VERSION ""

NS_ :

BS_:

BU_: TCM_Diesel ECM_Diesel BECMB_EPM TCM ECM Generic_BCM GWM _delete APIM BCM DCDC_VQM PAM TSTR PCM

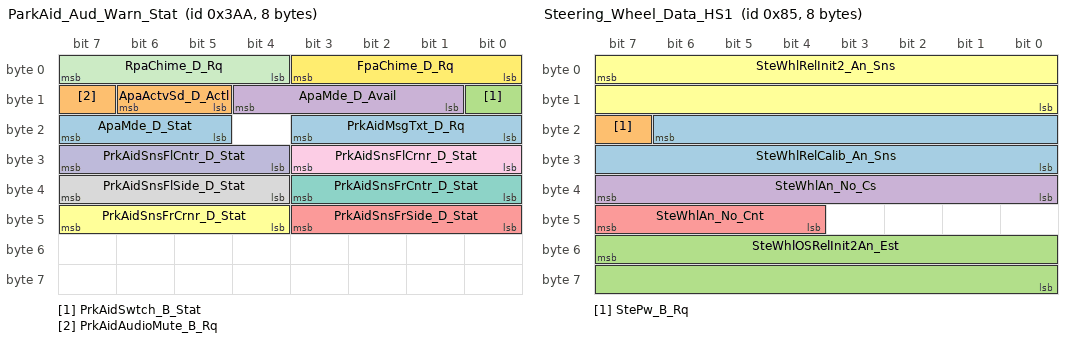
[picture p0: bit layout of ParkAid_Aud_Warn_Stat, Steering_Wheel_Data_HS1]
BO_ 938 ParkAid_Aud_Warn_Stat: 8 PAM
 SG_ ApaMde_D_Stat : 23|3@0+ (1,0) [0|7] "SED"  GWM
 SG_ ApaActvSd_D_Actl : 14|2@0+ (1,0) [0|3] "SED"  GWM
 SG_ PrkAidSwtch_B_Stat : 8|1@0+ (1,0) [0|1] "SED"  GWM
 SG_ ApaMde_D_Avail : 12|4@0+ (1,0) [0|15] "SED"  GWM
 SG_ PrkAidSnsFrSide_D_Stat : 43|4@0+ (1,0) [0|15] "SED"  GWM
 SG_ PrkAidSnsFrCrnr_D_Stat : 47|4@0+ (1,0) [0|15] "SED"  GWM
 SG_ PrkAidSnsFrCntr_D_Stat : 35|4@0+ (1,0) [0|15] "SED"  GWM
 SG_ PrkAidSnsFlSide_D_Stat : 39|4@0+ (1,0) [0|15] "SED"  GWM
 SG_ PrkAidSnsFlCrnr_D_Stat : 27|4@0+ (1,0) [0|15] "SED"  GWM
 SG_ PrkAidSnsFlCntr_D_Stat : 31|4@0+ (1,0) [0|15] "SED"  GWM
 SG_ RpaChime_D_Rq : 7|4@0+ (1,0) [0|15] "SED"  GWM
 SG_ FpaChime_D_Rq : 3|4@0+ (1,0) [0|15] "SED"  GWM
 SG_ PrkAidMsgTxt_D_Rq : 19|4@0+ (1,0) [0|15] "SED"  GWM
 SG_ PrkAidAudioMute_B_Rq : 15|1@0+ (1,0) [0|1] "SED"  GWM

BO_ 963 BCM_Lamp_Stat: 8 BCM
 SG_ WrlssAcsyChrgInhbt_B_Rq : 40|1@0+ (1,0) [0|1] "SED"  GWM
 SG_ PudLampPsngr_D_Rq : 57|2@0+ (1,0) [0|3] "SED"  GWM
 SG_ PudLampDrv_D_Rq : 59|2@0+ (1,0) [0|3] "SED"  GWM
 SG_ DrTgateLck_D_Stat : 61|2@0+ (1,0) [0|3] "SED"  GWM
 SG_ Illuminated_Entry_Stat : 63|2@0+ (1,0) [0|3] "SED"  GWM
 SG_ Dr_Courtesy_Light_Stat : 49|2@0+ (1,0) [0|3] "SED"  GWM
 SG_ Courtesy_Delay_Status : 51|2@0+ (1,0) [0|3] "SED"  GWM
 SG_ ImpactEvntFdbck_D_Stat : 53|2@0+ (1,0) [0|3] "SED"  GWM
 SG_ HeadLampLoOut_B_Stat : 32|1@0+ (1,0) [0|1] "SED"  GWM
 SG_ CrnrLghtRight_Pc_Rq : 47|7@0+ (1,0) [0|100] "percent"  GWM
 SG_ CrnrLghtLeft_Pc_Rq : 39|7@0+ (1,0) [0|100] "percent"  GWM
 SG_ HeadLghtHiFdbck_D_Stat : 55|2@0+ (1,0) [0|3] "SED"  GWM
 SG_ TrnNotInPrkChime_B_Rq : 24|1@0+ (1,0) [0|1] "SED"  GWM
 SG_ PrkLightChime_B_Rq : 25|1@0+ (1,0) [0|1] "SED"  GWM
 SG_ KeyInIgnWarn_B_Cmd : 27|1@0+ (1,0) [0|1] "SED"  GWM
 SG_ HomeSafeLtChime_B_Rq : 28|1@0+ (1,0) [0|1] "SED"  GWM
 SG_ StopLghtOn_B_Stat : 8|1@0+ (1,0) [0|1] "SED"  GWM
 SG_ RvrseLghtOn_B_Stat : 9|1@0+ (1,0) [0|1] "SED"  GWM
 SG_ PrkLght_D_Stat : 13|2@0+ (1,0) [0|3] "SED"  GWM
 SG_ HeadLghtSwtch_D_Stat : 15|2@0+ (1,0) [0|3] "SED"  GWM
 SG_ HeadLampLoFrOn_B_Stat : 2|1@0+ (1,0) [0|1] "SED"  GWM
 SG_ HeadLampLoFlOn_B_Stat : 3|1@0+ (1,0) [0|1] "SED"  GWM
 SG_ HeadLampLoActv_B_Stat : 4|1@0+ (1,0) [0|1] "SED"  ECM_Diesel,ECM,PCM,GWM
 SG_ Headlamp_On_Wrning_Cmd : 29|1@0+ (1,0) [0|1] "SED"  GWM
 SG_ Park_Brake_Chime_Rqst : 26|1@0+ (1,0) [0|1] "SED"  GWM
 SG_ HeadLghtHiOn_B_Stat : 1|1@0+ (1,0) [0|1] "SED"  ECM_Diesel,ECM,PCM,GWM
 SG_ BrkWarnInd_B_Rq : 20|1@0+ (1,0) [0|1] "SED"  GWM
 SG_ Brk_Fluid_Lvl_Low : 31|2@0+ (1,0) [0|3] "SED"  GWM
 SG_ ReducedGuard_D_Stat : 19|2@0+ (1,0) [0|3] "SED"  GWM
 SG_ Perimeter_Alarm_Status : 17|2@0+ (1,0) [0|3] "SED"  GWM
 SG_ Courtesy_BSave_Stat : 7|2@0+ (1,0) [0|3] "SED"  GWM
 SG_ WndwGlbl_D_Cmd : 23|3@0+ (1,0) [0|7] "SED"  GWM
 SG_ PudLamp_D_Rq : 11|2@0+ (1,0) [0|3] "SED"  GWM
 SG_ DayRnngLampOn_B_Stat : 5|1@0+ (1,0) [0|1] "SED"  GWM
 SG_ PerimeterAlarmChimeRq : 0|1@0+ (1,0) [0|1] "SED"  GWM

BO_ 1506 APIM_AutoSar_Network_HS1: 8 APIM
 SG_ APIM_AutoSar_Network_Mgmt : 7|64@0+ (1,0) [0|1.844674407371E+019] "unitless"  TCM_Diesel,BECMB_EPM,TCM,ECM,PCM,BCM,GWM

BO_ 133 Steering_Wheel_Data_HS1: 8 GWM
 SG_ SteWhlRelCalib_An_Sns : 22|15@0+ (0.1,-1600) [-1600|1676.5] "deg" Vector__XXX
 SG_ StePw_B_Rq : 23|1@0+ (1,0) [0|1] "SED"  ECM_Diesel,ECM,PCM
 SG_ SteWhlOSRelInit2An_Est : 55|16@0+ (0.1,-3200) [-3200|3353.3] "deg" Vector__XXX
 SG_ SteWhlAn_No_Cs : 39|8@0+ (1,0) [0|255] "Unitless" Vector__XXX
 SG_ SteWhlAn_No_Cnt : 47|4@0+ (1,0) [0|15] "Counts" Vector__XXX
 SG_ SteWhlRelInit2_An_Sns : 7|16@0+ (0.1,-3200) [-3200|3353.3] "deg"  ECM_Diesel,ECM,PCM

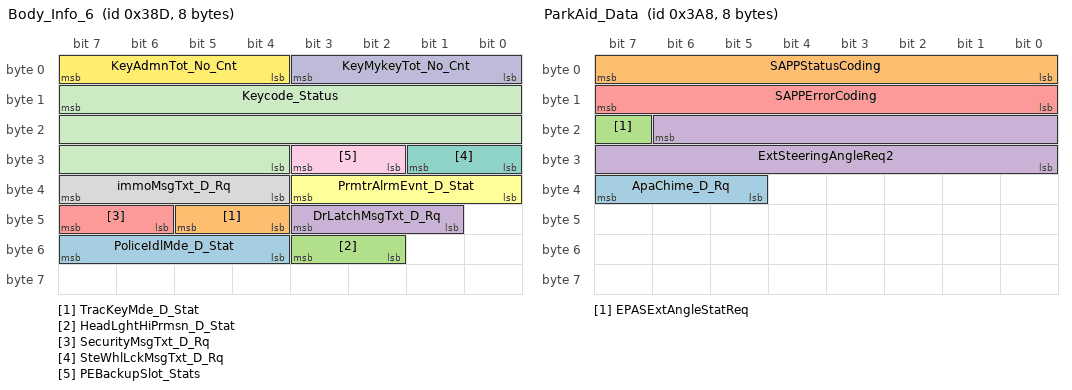
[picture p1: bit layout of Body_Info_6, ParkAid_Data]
BO_ 909 Body_Info_6: 8 BCM
 SG_ PoliceIdlMde_D_Stat : 55|4@0+ (1,0) [0|15] "SED"  GWM
 SG_ TracKeyMde_D_Stat : 45|2@0+ (1,0) [0|3] "SED"  GWM
 SG_ HeadLghtHiPrmsn_D_Stat : 51|2@0+ (1,0) [0|3] "SED"  GWM
 SG_ DrLatchMsgTxt_D_Rq : 43|3@0+ (1,0) [0|7] "SED"  GWM
 SG_ SecurityMsgTxt_D_Rq : 47|2@0+ (1,0) [0|3] "SED"  GWM
 SG_ PrmtrAlrmEvnt_D_Stat : 35|4@0+ (1,0) [0|15] "SED"  GWM
 SG_ SteWhlLckMsgTxt_D_Rq : 25|2@0+ (1,0) [0|3] "SED"  GWM
 SG_ immoMsgTxt_D_Rq : 39|4@0+ (1,0) [0|15] "SED"  GWM
 SG_ PEBackupSlot_Stats : 27|2@0+ (1,0) [0|3] "SED"  GWM
 SG_ KeyMykeyTot_No_Cnt : 3|4@0+ (1,0) [0|15] "Counts"  GWM
 SG_ Keycode_Status : 15|20@0+ (1,0) [0|1048575] "unitless"  GWM
 SG_ KeyAdmnTot_No_Cnt : 7|4@0+ (1,0) [0|15] "Counts"  GWM

BO_ 2024 TesterPhysicalResPCM: 8 PCM
 SG_ TesterPhysicalResPCM : 7|64@0+ (1,0) [0|1.84467E+019] "unitless"  TSTR

BO_ 936 ParkAid_Data: 8 PAM
 SG_ ApaChime_D_Rq : 39|3@0+ (1,0) [0|7] "SED"  GWM
 SG_ SAPPStatusCoding : 7|8@0+ (1,0) [0|255] "unitless"  ECM_Diesel,ECM,BCM,PCM,GWM
 SG_ EPASExtAngleStatReq : 23|1@0+ (1,0) [0|1] "SED"  GWM
 SG_ ExtSteeringAngleReq2 : 22|15@0+ (0.1,-1000) [-1000|2276.5] "Degrees"  GWM
 SG_ SAPPErrorCoding : 15|8@0+ (1,0) [0|255] "SED"  GWM

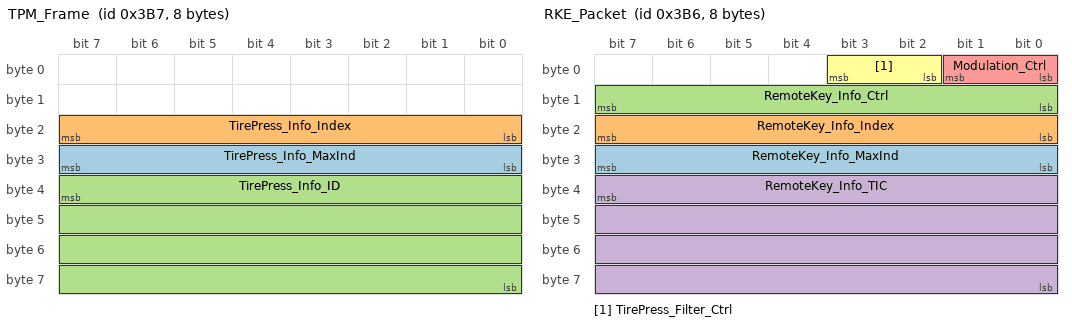
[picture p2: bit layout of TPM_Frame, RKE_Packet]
BO_ 951 TPM_Frame: 8 BCM
 SG_ TirePress_Info_MaxInd : 31|8@0+ (1,0) [0|255] "Unitless"  GWM
 SG_ TirePress_Info_Index : 23|8@0+ (1,0) [0|255] "Unitless"  GWM
 SG_ TirePress_Info_ID : 39|32@0+ (1,0) [0|4294967295] "Unitless"  GWM

BO_ 950 RKE_Packet: 8 BCM
 SG_ RemoteKey_Info_MaxInd : 31|8@0+ (1,0) [0|255] "Unitless"  GWM
 SG_ RemoteKey_Info_Index : 23|8@0+ (1,0) [0|255] "Unitless"  GWM
 SG_ RemoteKey_Info_Ctrl : 15|8@0+ (1,0) [0|255] "Unitless"  GWM
 SG_ RemoteKey_Info_TIC : 39|32@0+ (1,0) [0|4294967295] "Unitless"  GWM
 SG_ Modulation_Ctrl : 1|2@0+ (1,0) [0|3] "SED"  GWM
 SG_ TirePress_Filter_Ctrl : 3|2@0+ (1,0) [0|3] "SED"  GWM

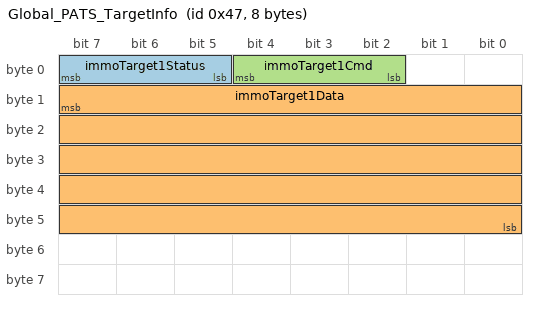
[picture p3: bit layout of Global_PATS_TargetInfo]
BO_ 71 Global_PATS_TargetInfo: 8 PCM
 SG_ immoTarget1Status : 7|3@0+ (1,0) [0|7] "SED"  TCM_Diesel,TCM,GWM,BCM
 SG_ immoTarget1Data : 15|40@0+ (1,0) [0|1099511627775] "Encrypted"  GWM,BCM
 SG_ immoTarget1Cmd : 4|3@0+ (1,0) [0|7] "SED"  GWM,BCM

BO_TX_BU_ 2024 : ECM_Diesel,ECM,PCM;
BO_TX_BU_ 71 : ECM_Diesel,ECM,PCM;
CM_ SG_ 133 SteWhlRelCalib_An_Sns "Signal is not transmitted on vehicles where PSCM is transmitting the message that contains this signal.
Signal data set to 0x0 for ABS only vehicle option content";
CM_ SG_ 133 SteWhlAn_No_Cs "Signal data set to 0x0 for ABS only vehicle option content";
CM_ SG_ 133 SteWhlAn_No_Cnt "Signal data set to 0x0 for ABS only vehicle option content";
CM_ BO_ 71 "Provide target function info. to control function of PATS";
BA_DEF_ SG_  "U_D568C_MY19_Gas_Tx" ENUM  "No","Yes";
BA_DEF_ SG_  "U_CD4_MY19_Diesel_Tx" ENUM  "No","Yes";
BA_DEF_ SG_  "U_CD4_MY19_Gas_Tx" ENUM  "No","Yes";
BA_DEF_ SG_  "U_CD4_MY19_Hev_Tx" ENUM  "No","Yes";
BA_DEF_ SG_  "U_CD4_MY19_Phev_Tx" ENUM  "No","Yes";
BA_DEF_ SG_  "U_V36X_MY19_Tx" ENUM  "No","Yes";
BA_DEF_ SG_  "U_V36X_MY18_5_Gas_Tx" ENUM  "No","Yes";
BA_DEF_ SG_  "U_V36X_MY18_5_Hev_Tx" ENUM  "No","Yes";
BA_DEF_ SG_  "U_V36X_MY19_5_Diesel_Tx" ENUM  "No","Yes";
BA_DEF_ SG_  "U_V363E_N_MY19_5_20_Gas_Tx" ENUM  "No","Yes";
BA_DEF_ SG_  "U_V363E_N_MY19_5_20_Diesel_Tx" ENUM  "No","Yes";
BA_DEF_ SG_  "U_S550_MY18_Gas_Rx" ENUM  "No","Yes";
BA_DEF_ SG_  "U_V408_MY18_Gas_Rx" ENUM  "No","Yes";
BA_DEF_ SG_  "U_V408_MY18_Diesel_Rx" ENUM  "No","Yes";
BA_DEF_ SG_  "U_U502_MY17_Gas_Tx" ENUM  "No","Yes";
BA_DEF_ SG_  "U_CD4_MY18_Diesel_Tx" ENUM  "No","Yes";
BA_DEF_ SG_  "U_CD4_MY18_Gas_Tx" ENUM  "No","Yes";
BA_DEF_ SG_  "U_CD4_MY18_Hev_Tx" ENUM  "No","Yes";
BA_DEF_ SG_  "U_CD4_MY18_Phev_Tx" ENUM  "No","Yes";
BA_DEF_ SG_  "U_S550_MY18_Gas_Tx" ENUM  "No","Yes";
BA_DEF_ SG_  "U_V408_MY18_Gas_Tx" ENUM  "No","Yes";
BA_DEF_ SG_  "U_V408_MY18_Diesel_Tx" ENUM  "No","Yes";
BA_DEF_ SG_  "U_V36X_MY18_5_Diesel_Tx" ENUM  "No","Yes";
BA_DEF_ SG_  "U_P552_MY18_5_Gas_Tx" ENUM  "No","Yes";
BA_DEF_ SG_  "U_P552_MY18_5_Diesel_Tx" ENUM  "No","Yes";
BA_DEF_ SG_  "U_U55x_MY18_Gas_Rx" ENUM  "No","Yes";
BA_DEF_ SG_  "U_P552_MY18_Gas_Tx" ENUM  "No","Yes";
BA_DEF_ SG_  "U_U55x_MY18_Gas_Tx" ENUM  "No","Yes";
BA_DEF_ BO_  "FrameGatewayNetwork" STRING ;
BA_DEF_ SG_  "U_C489_MY17_Gas_Rx" ENUM  "No","Yes";
BA_DEF_ SG_  "U_CD43_MY17_Gas_Rx" ENUM  "No","Yes";
BA_DEF_ SG_  "U_P552_MY17_Gas_Rx" ENUM  "No","Yes";
BA_DEF_ SG_  "U_B515_MCA_MY17_Diesel_Rx" ENUM  "No","Yes";
BA_DEF_ SG_  "U_B515_MCA_MY17_Gas_Rx" ENUM  "No","Yes";
BA_DEF_ SG_  "U_C489_MY17_Gas_Tx" ENUM  "No","Yes";
BA_DEF_ SG_  "U_CD43_MY17_Gas_Tx" ENUM  "No","Yes";
BA_DEF_ SG_  "U_CD4_MY17_Diesel_Rx" ENUM  "No","Yes";
BA_DEF_ SG_  "U_CD4_MY17_Gas_Rx" ENUM  "No","Yes";
BA_DEF_ SG_  "U_CD4_MY17_Hev_Rx" ENUM  "No","Yes";
BA_DEF_ SG_  "U_CD4_MY17_Phev_Rx" ENUM  "No","Yes";
BA_DEF_ SG_  "U_CD42_MY16_Diesel_Rx" ENUM  "No","Yes";
BA_DEF_ SG_  "U_CD42_MY16_Gas_Rx" ENUM  "No","Yes";
BA_DEF_ SG_  "U_B562LC_MY15_Diesel_Tx" ENUM  "No","Yes";
BA_DEF_ SG_  "U_CD4_MY17_Diesel_Tx" ENUM  "No","Yes";
BA_DEF_ SG_  "U_CD4_MY17_Gas_Tx" ENUM  "No","Yes";
BA_DEF_ SG_  "U_CD4_MY17_Hev_Tx" ENUM  "No","Yes";
BA_DEF_ SG_  "U_CD4_MY17_Phev_Tx" ENUM  "No","Yes";
BA_DEF_ SG_  "U_CD42_MY16_Diesel_Tx" ENUM  "No","Yes";
BA_DEF_ SG_  "U_CD42_MY16_Gas_Tx" ENUM  "No","Yes";
BA_DEF_ SG_  "U_CD42_MY15_Gas_Rx" ENUM  "No","Yes";
BA_DEF_ SG_  "U_U502_MY16_Gas_Rx" ENUM  "No","Yes";
BA_DEF_ SG_  "U_P558_MY17_Gas_Rx" ENUM  "No","Yes";
BA_DEF_ SG_  "U_P558_MY17_Diesel_Rx" ENUM  "No","Yes";
BA_DEF_ SG_  "U_V36X_MY16_5_Diesel_Rx" ENUM  "No","Yes";
BA_DEF_ SG_  "U_CD42_MY15_Diesel_Tx" ENUM  "No","Yes";
BA_DEF_ SG_  "U_CD42_MY15_Gas_Tx" ENUM  "No","Yes";
BA_DEF_ SG_  "U_U502_MY16_Gas_Tx" ENUM  "No","Yes";
BA_DEF_ SG_  "U_CD4_MY15_Diesel_Tx" ENUM  "No","Yes";
BA_DEF_ SG_  "U_CD4_MY15_Gas_Tx" ENUM  "No","Yes";
BA_DEF_ SG_  "U_CD4_MY15_Hev_Tx" ENUM  "No","Yes";
BA_DEF_ SG_  "U_CD4_MY15_Phev_Tx" ENUM  "No","Yes";
BA_DEF_ SG_  "U_P558_MY17_Gas_Tx" ENUM  "No","Yes";
BA_DEF_ SG_  "U_P558_MY17_Diesel_Tx" ENUM  "No","Yes";
BA_DEF_ SG_  "U_V36X_MY16_5_Diesel_Tx" ENUM  "No","Yes";
BA_DEF_ BO_  "FrameGatewayHS2" HEX 0 1407;
BA_DEF_ BO_  "NetworkInitialization" ENUM  "No","Yes";
BA_DEF_ BO_  "FrameGatewayId" HEX 0 1407;
BA_DEF_ BO_  "GenMsgStartDelayTime" INT 0 10000;
BA_DEF_ BO_  "GenMsgDelayTime" INT 0 1000;
BA_DEF_ BO_  "GenMsgCycleTime" INT 0 100000;
BA_DEF_ BO_  "GenMsgSendType" ENUM  "FixedPeriodic","Event","EnabledPeriodic","NotUsed","NotUsed","EventPeriodic","NotUsed","NotUsed","NoMsgSendType";
BA_DEF_ SG_  "U_CD4_MY14_Phev_Tx" ENUM  "No","Yes";
BA_DEF_ SG_  "U_CD4_MY14_Hev_Tx" ENUM  "No","Yes";
BA_DEF_ SG_  "U_CD4_MY14_Gas_Tx" ENUM  "No","Yes";
BA_DEF_ SG_  "U_CD4_MY14_Diesel_Tx" ENUM  "No","Yes";
BA_DEF_ SG_  "U_CD43_MY16_Gas_Tx" ENUM  "No","Yes";
BA_DEF_ SG_  "U_UP375_MY15_Diesel_Tx" ENUM  "No","Yes";
BA_DEF_ SG_  "U_UP375_MY15_Gas_Tx" ENUM  "No","Yes";
BA_DEF_ SG_  "U_U502_MY15_Gas_Tx" ENUM  "No","Yes";
BA_DEF_ SG_  "U_B562LC_MY14_Diesel_Tx" ENUM  "No","Yes";
BA_DEF_ SG_  "U_C489_MY14_Gas_Tx" ENUM  "No","Yes";
BA_DEF_ SG_  "U_S550_MY15_Gas_Tx" ENUM  "No","Yes";
BA_DEF_ SG_  "U_P552_MY15_Gas_Tx" ENUM  "No","Yes";
BA_DEF_ SG_  "U_CD42_MY14_Gas_Tx" ENUM  "No","Yes";
BA_DEF_ SG_  "U_CD42_MY14_Diesel_Tx" ENUM  "No","Yes";
BA_DEF_ SG_  "U_CD4_MY13_Phev_Tx" ENUM  "No","Yes";
BA_DEF_ SG_  "U_CD4_MY13_Hev_Tx" ENUM  "No","Yes";
BA_DEF_ SG_  "U_CD4_MY13_Gas_Tx" ENUM  "No","Yes";
BA_DEF_ SG_  "U_CD4_MY13_Diesel_Tx" ENUM  "No","Yes";
BA_DEF_ SG_  "U_CD4_MY14_Phev_Rx" ENUM  "No","Yes";
BA_DEF_ SG_  "U_CD4_MY14_Hev_Rx" ENUM  "No","Yes";
BA_DEF_ SG_  "U_CD4_MY14_Gas_Rx" ENUM  "No","Yes";
BA_DEF_ SG_  "U_CD4_MY14_Diesel_Rx" ENUM  "No","Yes";
BA_DEF_ SG_  "U_CD43_MY16_Gas_Rx" ENUM  "No","Yes";
BA_DEF_ SG_  "U_UP375_MY15_Diesel_Rx" ENUM  "No","Yes";
BA_DEF_ SG_  "U_UP375_MY15_Gas_Rx" ENUM  "No","Yes";
BA_DEF_ SG_  "U_B479_MY15_Gas_Rx" ENUM  "No","Yes";
BA_DEF_ SG_  "U_U502_MY15_Gas_Rx" ENUM  "No","Yes";
BA_DEF_ SG_  "U_C489_MY14_Gas_Rx" ENUM  "No","Yes";
BA_DEF_ SG_  "U_S550_MY15_Gas_Rx" ENUM  "No","Yes";
BA_DEF_ SG_  "U_P552_MY15_Gas_Rx" ENUM  "No","Yes";
BA_DEF_ SG_  "U_CD42_MY14_Gas_Rx" ENUM  "No","Yes";
BA_DEF_ SG_  "U_CD42_MY14_Diesel_Rx" ENUM  "No","Yes";
BA_DEF_ SG_  "U_CD4_MY13_Phev_Rx" ENUM  "No","Yes";
BA_DEF_ SG_  "U_CD4_MY13_Hev_Rx" ENUM  "No","Yes";
BA_DEF_ SG_  "U_CD4_MY13_Gas_Rx" ENUM  "No","Yes";
BA_DEF_ SG_  "U_CD4_MY13_Diesel_Rx" ENUM  "No","Yes";
BA_DEF_ SG_  "ContentDependant" ENUM  "No","Yes";
BA_DEF_ SG_  "GenSigStartValue" INT 0 1000000000;
BA_DEF_ SG_  "CrossOver_LIN" ENUM  "No","Yes";
BA_DEF_ SG_  "CrossOver_InfoCAN" ENUM  "No","Yes";
BA_DEF_ SG_  "WakeupSignal" ENUM  "No","Yes";
BA_DEF_ SG_  "GenSigMissingSourceValue" INT 0 1000000000;
BA_DEF_ SG_  "GenSigSendType" ENUM  "Cyclic","OnWrite","vector_leerstring","OnChange","vector_leerstring","IfActive","vector_leerstring","NoSigSendType";
BA_DEF_ BO_  "NmAsrMessage" ENUM  "No","Yes";
BA_DEF_ BO_  "DiagResponse" ENUM  "No","Yes";
BA_DEF_ BO_  "GenMsgILSupport" ENUM  "No","Yes";
BA_DEF_DEF_  "U_D568C_MY19_Gas_Tx" "No";
BA_DEF_DEF_  "U_CD4_MY19_Diesel_Tx" "No";
BA_DEF_DEF_  "U_CD4_MY19_Gas_Tx" "No";
BA_DEF_DEF_  "U_CD4_MY19_Hev_Tx" "No";
BA_DEF_DEF_  "U_CD4_MY19_Phev_Tx" "No";
BA_DEF_DEF_  "U_V36X_MY19_Tx" "No";
BA_DEF_DEF_  "U_V36X_MY18_5_Gas_Tx" "No";
BA_DEF_DEF_  "U_V36X_MY18_5_Hev_Tx" "No";
BA_DEF_DEF_  "U_V36X_MY19_5_Diesel_Tx" "No";
BA_DEF_DEF_  "U_V363E_N_MY19_5_20_Gas_Tx" "No";
BA_DEF_DEF_  "U_V363E_N_MY19_5_20_Diesel_Tx" "No";
BA_DEF_DEF_  "U_S550_MY18_Gas_Rx" "No";
BA_DEF_DEF_  "U_V408_MY18_Gas_Rx" "No";
BA_DEF_DEF_  "U_V408_MY18_Diesel_Rx" "No";
BA_DEF_DEF_  "U_U502_MY17_Gas_Tx" "No";
BA_DEF_DEF_  "U_CD4_MY18_Diesel_Tx" "No";
BA_DEF_DEF_  "U_CD4_MY18_Gas_Tx" "No";
BA_DEF_DEF_  "U_CD4_MY18_Hev_Tx" "No";
BA_DEF_DEF_  "U_CD4_MY18_Phev_Tx" "No";
BA_DEF_DEF_  "U_S550_MY18_Gas_Tx" "No";
BA_DEF_DEF_  "U_V408_MY18_Gas_Tx" "No";
BA_DEF_DEF_  "U_V408_MY18_Diesel_Tx" "No";
BA_DEF_DEF_  "U_V36X_MY18_5_Diesel_Tx" "No";
BA_DEF_DEF_  "U_P552_MY18_5_Gas_Tx" "No";
BA_DEF_DEF_  "U_P552_MY18_5_Diesel_Tx" "No";
BA_DEF_DEF_  "U_U55x_MY18_Gas_Rx" "No";
BA_DEF_DEF_  "U_P552_MY18_Gas_Tx" "No";
BA_DEF_DEF_  "U_U55x_MY18_Gas_Tx" "No";
BA_DEF_DEF_  "FrameGatewayNetwork" "NONE";
BA_DEF_DEF_  "U_C489_MY17_Gas_Rx" "No";
BA_DEF_DEF_  "U_CD43_MY17_Gas_Rx" "No";
BA_DEF_DEF_  "U_P552_MY17_Gas_Rx" "No";
BA_DEF_DEF_  "U_B515_MCA_MY17_Diesel_Rx" "No";
BA_DEF_DEF_  "U_B515_MCA_MY17_Gas_Rx" "No";
BA_DEF_DEF_  "U_C489_MY17_Gas_Tx" "No";
BA_DEF_DEF_  "U_CD43_MY17_Gas_Tx" "No";
BA_DEF_DEF_  "U_CD4_MY17_Diesel_Rx" "No";
BA_DEF_DEF_  "U_CD4_MY17_Gas_Rx" "No";
BA_DEF_DEF_  "U_CD4_MY17_Hev_Rx" "No";
BA_DEF_DEF_  "U_CD4_MY17_Phev_Rx" "No";
BA_DEF_DEF_  "U_CD42_MY16_Diesel_Rx" "No";
BA_DEF_DEF_  "U_CD42_MY16_Gas_Rx" "No";
BA_DEF_DEF_  "U_B562LC_MY15_Diesel_Tx" "No";
BA_DEF_DEF_  "U_CD4_MY17_Diesel_Tx" "No";
BA_DEF_DEF_  "U_CD4_MY17_Gas_Tx" "No";
BA_DEF_DEF_  "U_CD4_MY17_Hev_Tx" "No";
BA_DEF_DEF_  "U_CD4_MY17_Phev_Tx" "No";
BA_DEF_DEF_  "U_CD42_MY16_Diesel_Tx" "No";
BA_DEF_DEF_  "U_CD42_MY16_Gas_Tx" "No";
BA_DEF_DEF_  "U_CD42_MY15_Gas_Rx" "No";
BA_DEF_DEF_  "U_U502_MY16_Gas_Rx" "No";
BA_DEF_DEF_  "U_P558_MY17_Gas_Rx" "No";
BA_DEF_DEF_  "U_P558_MY17_Diesel_Rx" "No";
BA_DEF_DEF_  "U_V36X_MY16_5_Diesel_Rx" "No";
BA_DEF_DEF_  "U_CD42_MY15_Diesel_Tx" "No";
BA_DEF_DEF_  "U_CD42_MY15_Gas_Tx" "No";
BA_DEF_DEF_  "U_U502_MY16_Gas_Tx" "No";
BA_DEF_DEF_  "U_CD4_MY15_Diesel_Tx" "No";
BA_DEF_DEF_  "U_CD4_MY15_Gas_Tx" "No";
BA_DEF_DEF_  "U_CD4_MY15_Hev_Tx" "No";
BA_DEF_DEF_  "U_CD4_MY15_Phev_Tx" "No";
BA_DEF_DEF_  "U_P558_MY17_Gas_Tx" "No";
BA_DEF_DEF_  "U_P558_MY17_Diesel_Tx" "No";
BA_DEF_DEF_  "U_V36X_MY16_5_Diesel_Tx" "No";
BA_DEF_DEF_  "FrameGatewayHS2" 0;
BA_DEF_DEF_  "NetworkInitialization" "No";
BA_DEF_DEF_  "FrameGatewayId" 0;
BA_DEF_DEF_  "GenMsgStartDelayTime" 0;
BA_DEF_DEF_  "GenMsgDelayTime" 20;
BA_DEF_DEF_  "GenMsgCycleTime" 0;
BA_DEF_DEF_  "GenMsgSendType" "NoMsgSendType";
BA_DEF_DEF_  "U_CD4_MY14_Phev_Tx" "No";
BA_DEF_DEF_  "U_CD4_MY14_Hev_Tx" "No";
BA_DEF_DEF_  "U_CD4_MY14_Gas_Tx" "No";
BA_DEF_DEF_  "U_CD4_MY14_Diesel_Tx" "No";
BA_DEF_DEF_  "U_CD43_MY16_Gas_Tx" "No";
BA_DEF_DEF_  "U_UP375_MY15_Diesel_Tx" "No";
BA_DEF_DEF_  "U_UP375_MY15_Gas_Tx" "No";
BA_DEF_DEF_  "U_U502_MY15_Gas_Tx" "No";
BA_DEF_DEF_  "U_B562LC_MY14_Diesel_Tx" "No";
BA_DEF_DEF_  "U_C489_MY14_Gas_Tx" "No";
BA_DEF_DEF_  "U_S550_MY15_Gas_Tx" "No";
BA_DEF_DEF_  "U_P552_MY15_Gas_Tx" "No";
BA_DEF_DEF_  "U_CD42_MY14_Gas_Tx" "No";
BA_DEF_DEF_  "U_CD42_MY14_Diesel_Tx" "No";
BA_DEF_DEF_  "U_CD4_MY13_Phev_Tx" "No";
BA_DEF_DEF_  "U_CD4_MY13_Hev_Tx" "No";
BA_DEF_DEF_  "U_CD4_MY13_Gas_Tx" "No";
BA_DEF_DEF_  "U_CD4_MY13_Diesel_Tx" "No";
BA_DEF_DEF_  "U_CD4_MY14_Phev_Rx" "No";
BA_DEF_DEF_  "U_CD4_MY14_Hev_Rx" "No";
BA_DEF_DEF_  "U_CD4_MY14_Gas_Rx" "No";
BA_DEF_DEF_  "U_CD4_MY14_Diesel_Rx" "No";
BA_DEF_DEF_  "U_CD43_MY16_Gas_Rx" "No";
BA_DEF_DEF_  "U_UP375_MY15_Diesel_Rx" "No";
BA_DEF_DEF_  "U_UP375_MY15_Gas_Rx" "No";
BA_DEF_DEF_  "U_B479_MY15_Gas_Rx" "No";
BA_DEF_DEF_  "U_U502_MY15_Gas_Rx" "No";
BA_DEF_DEF_  "U_C489_MY14_Gas_Rx" "No";
BA_DEF_DEF_  "U_S550_MY15_Gas_Rx" "No";
BA_DEF_DEF_  "U_P552_MY15_Gas_Rx" "No";
BA_DEF_DEF_  "U_CD42_MY14_Gas_Rx" "No";
BA_DEF_DEF_  "U_CD42_MY14_Diesel_Rx" "No";
BA_DEF_DEF_  "U_CD4_MY13_Phev_Rx" "No";
BA_DEF_DEF_  "U_CD4_MY13_Hev_Rx" "No";
BA_DEF_DEF_  "U_CD4_MY13_Gas_Rx" "No";
BA_DEF_DEF_  "U_CD4_MY13_Diesel_Rx" "No";
BA_DEF_DEF_  "ContentDependant" "No";
BA_DEF_DEF_  "GenSigStartValue" 0;
BA_DEF_DEF_  "CrossOver_LIN" "No";
BA_DEF_DEF_  "CrossOver_InfoCAN" "No";
BA_DEF_DEF_  "WakeupSignal" "No";
BA_DEF_DEF_  "GenSigMissingSourceValue" 0;
BA_DEF_DEF_  "GenSigSendType" "NoSigSendType";
BA_DEF_DEF_  "NmAsrMessage" "No";
BA_DEF_DEF_  "DiagResponse" "No";
BA_DEF_DEF_  "GenMsgILSupport" "Yes";
BA_ "GenMsgSendType" BO_ 938 5;
BA_ "GenMsgCycleTime" BO_ 938 200;
BA_ "GenMsgSendType" BO_ 963 5;
BA_ "GenMsgCycleTime" BO_ 963 1000;
BA_ "GenMsgStartDelayTime" BO_ 963 100;
BA_ "NetworkInitialization" BO_ 963 1;
BA_ "GenMsgILSupport" BO_ 1506 0;
BA_ "NmAsrMessage" BO_ 1506 1;
BA_ "GenMsgSendType" BO_ 1506 1;
BA_ "NetworkInitialization" BO_ 133 1;
BA_ "FrameGatewayNetwork" BO_ 133 "HS2_CAN";
BA_ "GenMsgDelayTime" BO_ 133 5;
BA_ "FrameGatewayId" BO_ 133 133;
BA_ "FrameGatewayHS2" BO_ 133 133;
BA_ "NetworkInitialization" BO_ 909 1;
BA_ "GenMsgSendType" BO_ 909 5;
BA_ "GenMsgCycleTime" BO_ 909 1000;
BA_ "GenMsgILSupport" BO_ 2024 0;
BA_ "DiagResponse" BO_ 2024 1;
BA_ "GenMsgSendType" BO_ 2024 1;
BA_ "GenMsgDelayTime" BO_ 2024 0;
BA_ "GenMsgSendType" BO_ 936 0;
BA_ "GenMsgCycleTime" BO_ 936 20;
BA_ "GenMsgDelayTime" BO_ 936 10;
BA_ "GenMsgSendType" BO_ 951 0;
BA_ "GenMsgCycleTime" BO_ 951 250;
BA_ "GenMsgSendType" BO_ 950 0;
BA_ "GenMsgCycleTime" BO_ 950 250;
BA_ "GenMsgSendType" BO_ 71 0;
BA_ "GenMsgCycleTime" BO_ 71 20;
BA_ "GenMsgDelayTime" BO_ 71 10;
BA_ "CrossOver_InfoCAN" SG_ 938 ApaMde_D_Stat 1;
BA_ "GenSigSendType" SG_ 938 ApaMde_D_Stat 3;
BA_ "U_CD4_MY13_Diesel_Tx" SG_ 938 ApaMde_D_Stat 1;
BA_ "U_CD4_MY13_Gas_Tx" SG_ 938 ApaMde_D_Stat 1;
BA_ "U_CD4_MY13_Hev_Tx" SG_ 938 ApaMde_D_Stat 1;
BA_ "U_CD4_MY13_Phev_Tx" SG_ 938 ApaMde_D_Stat 1;
BA_ "U_CD42_MY14_Diesel_Tx" SG_ 938 ApaMde_D_Stat 1;
BA_ "U_CD42_MY14_Gas_Tx" SG_ 938 ApaMde_D_Stat 1;
BA_ "U_P552_MY15_Gas_Tx" SG_ 938 ApaMde_D_Stat 1;
BA_ "U_S550_MY15_Gas_Tx" SG_ 938 ApaMde_D_Stat 1;
BA_ "U_C489_MY14_Gas_Tx" SG_ 938 ApaMde_D_Stat 1;
BA_ "U_U502_MY15_Gas_Tx" SG_ 938 ApaMde_D_Stat 1;
BA_ "U_UP375_MY15_Gas_Tx" SG_ 938 ApaMde_D_Stat 1;
BA_ "U_UP375_MY15_Diesel_Tx" SG_ 938 ApaMde_D_Stat 1;
BA_ "U_CD43_MY16_Gas_Tx" SG_ 938 ApaMde_D_Stat 1;
BA_ "U_CD4_MY14_Diesel_Tx" SG_ 938 ApaMde_D_Stat 1;
BA_ "U_CD4_MY14_Gas_Tx" SG_ 938 ApaMde_D_Stat 1;
BA_ "U_CD4_MY14_Hev_Tx" SG_ 938 ApaMde_D_Stat 1;
BA_ "U_CD4_MY14_Phev_Tx" SG_ 938 ApaMde_D_Stat 1;
BA_ "CrossOver_InfoCAN" SG_ 938 ApaActvSd_D_Actl 1;
BA_ "GenSigStartValue" SG_ 938 ApaActvSd_D_Actl 1;
BA_ "GenSigSendType" SG_ 938 ApaActvSd_D_Actl 3;
BA_ "U_CD4_MY13_Diesel_Tx" SG_ 938 ApaActvSd_D_Actl 1;
BA_ "U_CD4_MY13_Gas_Tx" SG_ 938 ApaActvSd_D_Actl 1;
BA_ "U_CD4_MY13_Hev_Tx" SG_ 938 ApaActvSd_D_Actl 1;
BA_ "U_CD4_MY13_Phev_Tx" SG_ 938 ApaActvSd_D_Actl 1;
BA_ "U_CD42_MY14_Diesel_Tx" SG_ 938 ApaActvSd_D_Actl 1;
BA_ "U_CD42_MY14_Gas_Tx" SG_ 938 ApaActvSd_D_Actl 1;
BA_ "U_P552_MY15_Gas_Tx" SG_ 938 ApaActvSd_D_Actl 1;
BA_ "U_S550_MY15_Gas_Tx" SG_ 938 ApaActvSd_D_Actl 1;
BA_ "U_C489_MY14_Gas_Tx" SG_ 938 ApaActvSd_D_Actl 1;
BA_ "U_U502_MY15_Gas_Tx" SG_ 938 ApaActvSd_D_Actl 1;
BA_ "U_UP375_MY15_Gas_Tx" SG_ 938 ApaActvSd_D_Actl 1;
BA_ "U_UP375_MY15_Diesel_Tx" SG_ 938 ApaActvSd_D_Actl 1;
BA_ "U_CD43_MY16_Gas_Tx" SG_ 938 ApaActvSd_D_Actl 1;
BA_ "U_CD4_MY14_Diesel_Tx" SG_ 938 ApaActvSd_D_Actl 1;
BA_ "U_CD4_MY14_Gas_Tx" SG_ 938 ApaActvSd_D_Actl 1;
BA_ "U_CD4_MY14_Hev_Tx" SG_ 938 ApaActvSd_D_Actl 1;
BA_ "U_CD4_MY14_Phev_Tx" SG_ 938 ApaActvSd_D_Actl 1;
BA_ "CrossOver_InfoCAN" SG_ 938 PrkAidSwtch_B_Stat 1;
BA_ "GenSigSendType" SG_ 938 PrkAidSwtch_B_Stat 3;
BA_ "U_CD4_MY13_Diesel_Tx" SG_ 938 PrkAidSwtch_B_Stat 1;
BA_ "U_CD4_MY13_Gas_Tx" SG_ 938 PrkAidSwtch_B_Stat 1;
BA_ "U_CD4_MY13_Hev_Tx" SG_ 938 PrkAidSwtch_B_Stat 1;
BA_ "U_CD4_MY13_Phev_Tx" SG_ 938 PrkAidSwtch_B_Stat 1;
BA_ "U_CD42_MY14_Diesel_Tx" SG_ 938 PrkAidSwtch_B_Stat 1;
BA_ "U_CD42_MY14_Gas_Tx" SG_ 938 PrkAidSwtch_B_Stat 1;
BA_ "U_P552_MY15_Gas_Tx" SG_ 938 PrkAidSwtch_B_Stat 1;
BA_ "U_S550_MY15_Gas_Tx" SG_ 938 PrkAidSwtch_B_Stat 1;
BA_ "U_C489_MY14_Gas_Tx" SG_ 938 PrkAidSwtch_B_Stat 1;
BA_ "U_U502_MY15_Gas_Tx" SG_ 938 PrkAidSwtch_B_Stat 1;
BA_ "U_UP375_MY15_Gas_Tx" SG_ 938 PrkAidSwtch_B_Stat 1;
BA_ "U_UP375_MY15_Diesel_Tx" SG_ 938 PrkAidSwtch_B_Stat 1;
BA_ "U_CD43_MY16_Gas_Tx" SG_ 938 PrkAidSwtch_B_Stat 1;
BA_ "U_CD4_MY14_Diesel_Tx" SG_ 938 PrkAidSwtch_B_Stat 1;
BA_ "U_CD4_MY14_Gas_Tx" SG_ 938 PrkAidSwtch_B_Stat 1;
BA_ "U_CD4_MY14_Hev_Tx" SG_ 938 PrkAidSwtch_B_Stat 1;
BA_ "U_CD4_MY14_Phev_Tx" SG_ 938 PrkAidSwtch_B_Stat 1;
BA_ "CrossOver_InfoCAN" SG_ 938 ApaMde_D_Avail 1;
BA_ "GenSigSendType" SG_ 938 ApaMde_D_Avail 3;
BA_ "U_CD4_MY13_Diesel_Tx" SG_ 938 ApaMde_D_Avail 1;
BA_ "U_CD4_MY13_Gas_Tx" SG_ 938 ApaMde_D_Avail 1;
BA_ "U_CD4_MY13_Hev_Tx" SG_ 938 ApaMde_D_Avail 1;
BA_ "U_CD4_MY13_Phev_Tx" SG_ 938 ApaMde_D_Avail 1;
BA_ "U_CD42_MY14_Diesel_Tx" SG_ 938 ApaMde_D_Avail 1;
BA_ "U_CD42_MY14_Gas_Tx" SG_ 938 ApaMde_D_Avail 1;
BA_ "U_P552_MY15_Gas_Tx" SG_ 938 ApaMde_D_Avail 1;
BA_ "U_S550_MY15_Gas_Tx" SG_ 938 ApaMde_D_Avail 1;
BA_ "U_C489_MY14_Gas_Tx" SG_ 938 ApaMde_D_Avail 1;
BA_ "U_U502_MY15_Gas_Tx" SG_ 938 ApaMde_D_Avail 1;
BA_ "U_UP375_MY15_Gas_Tx" SG_ 938 ApaMde_D_Avail 1;
BA_ "U_UP375_MY15_Diesel_Tx" SG_ 938 ApaMde_D_Avail 1;
BA_ "U_CD43_MY16_Gas_Tx" SG_ 938 ApaMde_D_Avail 1;
BA_ "U_CD4_MY14_Diesel_Tx" SG_ 938 ApaMde_D_Avail 1;
BA_ "U_CD4_MY14_Gas_Tx" SG_ 938 ApaMde_D_Avail 1;
BA_ "U_CD4_MY14_Hev_Tx" SG_ 938 ApaMde_D_Avail 1;
BA_ "U_CD4_MY14_Phev_Tx" SG_ 938 ApaMde_D_Avail 1;
BA_ "CrossOver_InfoCAN" SG_ 938 PrkAidSnsFrSide_D_Stat 1;
BA_ "GenSigSendType" SG_ 938 PrkAidSnsFrSide_D_Stat 3;
BA_ "U_CD4_MY13_Diesel_Tx" SG_ 938 PrkAidSnsFrSide_D_Stat 1;
BA_ "U_CD4_MY13_Gas_Tx" SG_ 938 PrkAidSnsFrSide_D_Stat 1;
BA_ "U_CD4_MY13_Hev_Tx" SG_ 938 PrkAidSnsFrSide_D_Stat 1;
BA_ "U_CD4_MY13_Phev_Tx" SG_ 938 PrkAidSnsFrSide_D_Stat 1;
BA_ "U_CD42_MY14_Diesel_Tx" SG_ 938 PrkAidSnsFrSide_D_Stat 1;
BA_ "U_CD42_MY14_Gas_Tx" SG_ 938 PrkAidSnsFrSide_D_Stat 1;
BA_ "U_P552_MY15_Gas_Tx" SG_ 938 PrkAidSnsFrSide_D_Stat 1;
BA_ "U_S550_MY15_Gas_Tx" SG_ 938 PrkAidSnsFrSide_D_Stat 1;
BA_ "U_C489_MY14_Gas_Tx" SG_ 938 PrkAidSnsFrSide_D_Stat 1;
BA_ "U_U502_MY15_Gas_Tx" SG_ 938 PrkAidSnsFrSide_D_Stat 1;
BA_ "U_UP375_MY15_Gas_Tx" SG_ 938 PrkAidSnsFrSide_D_Stat 1;
BA_ "U_UP375_MY15_Diesel_Tx" SG_ 938 PrkAidSnsFrSide_D_Stat 1;
BA_ "U_CD43_MY16_Gas_Tx" SG_ 938 PrkAidSnsFrSide_D_Stat 1;
BA_ "U_CD4_MY14_Diesel_Tx" SG_ 938 PrkAidSnsFrSide_D_Stat 1;
BA_ "U_CD4_MY14_Gas_Tx" SG_ 938 PrkAidSnsFrSide_D_Stat 1;
BA_ "U_CD4_MY14_Hev_Tx" SG_ 938 PrkAidSnsFrSide_D_Stat 1;
BA_ "U_CD4_MY14_Phev_Tx" SG_ 938 PrkAidSnsFrSide_D_Stat 1;
BA_ "CrossOver_InfoCAN" SG_ 938 PrkAidSnsFrCrnr_D_Stat 1;
BA_ "GenSigSendType" SG_ 938 PrkAidSnsFrCrnr_D_Stat 3;
BA_ "U_CD4_MY13_Diesel_Tx" SG_ 938 PrkAidSnsFrCrnr_D_Stat 1;
BA_ "U_CD4_MY13_Gas_Tx" SG_ 938 PrkAidSnsFrCrnr_D_Stat 1;
BA_ "U_CD4_MY13_Hev_Tx" SG_ 938 PrkAidSnsFrCrnr_D_Stat 1;
BA_ "U_CD4_MY13_Phev_Tx" SG_ 938 PrkAidSnsFrCrnr_D_Stat 1;
BA_ "U_CD42_MY14_Diesel_Tx" SG_ 938 PrkAidSnsFrCrnr_D_Stat 1;
BA_ "U_CD42_MY14_Gas_Tx" SG_ 938 PrkAidSnsFrCrnr_D_Stat 1;
BA_ "U_P552_MY15_Gas_Tx" SG_ 938 PrkAidSnsFrCrnr_D_Stat 1;
BA_ "U_S550_MY15_Gas_Tx" SG_ 938 PrkAidSnsFrCrnr_D_Stat 1;
BA_ "U_C489_MY14_Gas_Tx" SG_ 938 PrkAidSnsFrCrnr_D_Stat 1;
BA_ "U_U502_MY15_Gas_Tx" SG_ 938 PrkAidSnsFrCrnr_D_Stat 1;
BA_ "U_UP375_MY15_Gas_Tx" SG_ 938 PrkAidSnsFrCrnr_D_Stat 1;
BA_ "U_UP375_MY15_Diesel_Tx" SG_ 938 PrkAidSnsFrCrnr_D_Stat 1;
BA_ "U_CD43_MY16_Gas_Tx" SG_ 938 PrkAidSnsFrCrnr_D_Stat 1;
BA_ "U_CD4_MY14_Diesel_Tx" SG_ 938 PrkAidSnsFrCrnr_D_Stat 1;
BA_ "U_CD4_MY14_Gas_Tx" SG_ 938 PrkAidSnsFrCrnr_D_Stat 1;
BA_ "U_CD4_MY14_Hev_Tx" SG_ 938 PrkAidSnsFrCrnr_D_Stat 1;
BA_ "U_CD4_MY14_Phev_Tx" SG_ 938 PrkAidSnsFrCrnr_D_Stat 1;
BA_ "CrossOver_InfoCAN" SG_ 938 PrkAidSnsFrCntr_D_Stat 1;
BA_ "GenSigSendType" SG_ 938 PrkAidSnsFrCntr_D_Stat 3;
BA_ "U_CD4_MY13_Diesel_Tx" SG_ 938 PrkAidSnsFrCntr_D_Stat 1;
BA_ "U_CD4_MY13_Gas_Tx" SG_ 938 PrkAidSnsFrCntr_D_Stat 1;
BA_ "U_CD4_MY13_Hev_Tx" SG_ 938 PrkAidSnsFrCntr_D_Stat 1;
BA_ "U_CD4_MY13_Phev_Tx" SG_ 938 PrkAidSnsFrCntr_D_Stat 1;
BA_ "U_CD42_MY14_Diesel_Tx" SG_ 938 PrkAidSnsFrCntr_D_Stat 1;
BA_ "U_CD42_MY14_Gas_Tx" SG_ 938 PrkAidSnsFrCntr_D_Stat 1;
BA_ "U_P552_MY15_Gas_Tx" SG_ 938 PrkAidSnsFrCntr_D_Stat 1;
BA_ "U_S550_MY15_Gas_Tx" SG_ 938 PrkAidSnsFrCntr_D_Stat 1;
BA_ "U_C489_MY14_Gas_Tx" SG_ 938 PrkAidSnsFrCntr_D_Stat 1;
BA_ "U_U502_MY15_Gas_Tx" SG_ 938 PrkAidSnsFrCntr_D_Stat 1;
BA_ "U_UP375_MY15_Gas_Tx" SG_ 938 PrkAidSnsFrCntr_D_Stat 1;
BA_ "U_UP375_MY15_Diesel_Tx" SG_ 938 PrkAidSnsFrCntr_D_Stat 1;
BA_ "U_CD43_MY16_Gas_Tx" SG_ 938 PrkAidSnsFrCntr_D_Stat 1;
BA_ "U_CD4_MY14_Diesel_Tx" SG_ 938 PrkAidSnsFrCntr_D_Stat 1;
BA_ "U_CD4_MY14_Gas_Tx" SG_ 938 PrkAidSnsFrCntr_D_Stat 1;
BA_ "U_CD4_MY14_Hev_Tx" SG_ 938 PrkAidSnsFrCntr_D_Stat 1;
BA_ "U_CD4_MY14_Phev_Tx" SG_ 938 PrkAidSnsFrCntr_D_Stat 1;
BA_ "CrossOver_InfoCAN" SG_ 938 PrkAidSnsFlSide_D_Stat 1;
BA_ "GenSigSendType" SG_ 938 PrkAidSnsFlSide_D_Stat 3;
BA_ "U_CD4_MY13_Diesel_Tx" SG_ 938 PrkAidSnsFlSide_D_Stat 1;
BA_ "U_CD4_MY13_Gas_Tx" SG_ 938 PrkAidSnsFlSide_D_Stat 1;
BA_ "U_CD4_MY13_Hev_Tx" SG_ 938 PrkAidSnsFlSide_D_Stat 1;
BA_ "U_CD4_MY13_Phev_Tx" SG_ 938 PrkAidSnsFlSide_D_Stat 1;
BA_ "U_CD42_MY14_Diesel_Tx" SG_ 938 PrkAidSnsFlSide_D_Stat 1;
BA_ "U_CD42_MY14_Gas_Tx" SG_ 938 PrkAidSnsFlSide_D_Stat 1;
BA_ "U_P552_MY15_Gas_Tx" SG_ 938 PrkAidSnsFlSide_D_Stat 1;
BA_ "U_S550_MY15_Gas_Tx" SG_ 938 PrkAidSnsFlSide_D_Stat 1;
BA_ "U_C489_MY14_Gas_Tx" SG_ 938 PrkAidSnsFlSide_D_Stat 1;
BA_ "U_U502_MY15_Gas_Tx" SG_ 938 PrkAidSnsFlSide_D_Stat 1;
BA_ "U_UP375_MY15_Gas_Tx" SG_ 938 PrkAidSnsFlSide_D_Stat 1;
BA_ "U_UP375_MY15_Diesel_Tx" SG_ 938 PrkAidSnsFlSide_D_Stat 1;
BA_ "U_CD43_MY16_Gas_Tx" SG_ 938 PrkAidSnsFlSide_D_Stat 1;
BA_ "U_CD4_MY14_Diesel_Tx" SG_ 938 PrkAidSnsFlSide_D_Stat 1;
BA_ "U_CD4_MY14_Gas_Tx" SG_ 938 PrkAidSnsFlSide_D_Stat 1;
BA_ "U_CD4_MY14_Hev_Tx" SG_ 938 PrkAidSnsFlSide_D_Stat 1;
BA_ "U_CD4_MY14_Phev_Tx" SG_ 938 PrkAidSnsFlSide_D_Stat 1;
BA_ "CrossOver_InfoCAN" SG_ 938 PrkAidSnsFlCrnr_D_Stat 1;
BA_ "GenSigSendType" SG_ 938 PrkAidSnsFlCrnr_D_Stat 3;
BA_ "U_CD4_MY13_Diesel_Tx" SG_ 938 PrkAidSnsFlCrnr_D_Stat 1;
BA_ "U_CD4_MY13_Gas_Tx" SG_ 938 PrkAidSnsFlCrnr_D_Stat 1;
BA_ "U_CD4_MY13_Hev_Tx" SG_ 938 PrkAidSnsFlCrnr_D_Stat 1;
BA_ "U_CD4_MY13_Phev_Tx" SG_ 938 PrkAidSnsFlCrnr_D_Stat 1;
BA_ "U_CD42_MY14_Diesel_Tx" SG_ 938 PrkAidSnsFlCrnr_D_Stat 1;
BA_ "U_CD42_MY14_Gas_Tx" SG_ 938 PrkAidSnsFlCrnr_D_Stat 1;
BA_ "U_P552_MY15_Gas_Tx" SG_ 938 PrkAidSnsFlCrnr_D_Stat 1;
BA_ "U_S550_MY15_Gas_Tx" SG_ 938 PrkAidSnsFlCrnr_D_Stat 1;
BA_ "U_C489_MY14_Gas_Tx" SG_ 938 PrkAidSnsFlCrnr_D_Stat 1;
BA_ "U_U502_MY15_Gas_Tx" SG_ 938 PrkAidSnsFlCrnr_D_Stat 1;
BA_ "U_UP375_MY15_Gas_Tx" SG_ 938 PrkAidSnsFlCrnr_D_Stat 1;
BA_ "U_UP375_MY15_Diesel_Tx" SG_ 938 PrkAidSnsFlCrnr_D_Stat 1;
BA_ "U_CD43_MY16_Gas_Tx" SG_ 938 PrkAidSnsFlCrnr_D_Stat 1;
BA_ "U_CD4_MY14_Diesel_Tx" SG_ 938 PrkAidSnsFlCrnr_D_Stat 1;
BA_ "U_CD4_MY14_Gas_Tx" SG_ 938 PrkAidSnsFlCrnr_D_Stat 1;
BA_ "U_CD4_MY14_Hev_Tx" SG_ 938 PrkAidSnsFlCrnr_D_Stat 1;
BA_ "U_CD4_MY14_Phev_Tx" SG_ 938 PrkAidSnsFlCrnr_D_Stat 1;
BA_ "CrossOver_InfoCAN" SG_ 938 PrkAidSnsFlCntr_D_Stat 1;
BA_ "GenSigSendType" SG_ 938 PrkAidSnsFlCntr_D_Stat 3;
BA_ "U_CD4_MY13_Diesel_Tx" SG_ 938 PrkAidSnsFlCntr_D_Stat 1;
BA_ "U_CD4_MY13_Gas_Tx" SG_ 938 PrkAidSnsFlCntr_D_Stat 1;
BA_ "U_CD4_MY13_Hev_Tx" SG_ 938 PrkAidSnsFlCntr_D_Stat 1;
BA_ "U_CD4_MY13_Phev_Tx" SG_ 938 PrkAidSnsFlCntr_D_Stat 1;
BA_ "U_CD42_MY14_Diesel_Tx" SG_ 938 PrkAidSnsFlCntr_D_Stat 1;
BA_ "U_CD42_MY14_Gas_Tx" SG_ 938 PrkAidSnsFlCntr_D_Stat 1;
BA_ "U_P552_MY15_Gas_Tx" SG_ 938 PrkAidSnsFlCntr_D_Stat 1;
BA_ "U_S550_MY15_Gas_Tx" SG_ 938 PrkAidSnsFlCntr_D_Stat 1;
BA_ "U_C489_MY14_Gas_Tx" SG_ 938 PrkAidSnsFlCntr_D_Stat 1;
BA_ "U_U502_MY15_Gas_Tx" SG_ 938 PrkAidSnsFlCntr_D_Stat 1;
BA_ "U_UP375_MY15_Gas_Tx" SG_ 938 PrkAidSnsFlCntr_D_Stat 1;
BA_ "U_UP375_MY15_Diesel_Tx" SG_ 938 PrkAidSnsFlCntr_D_Stat 1;
BA_ "U_CD43_MY16_Gas_Tx" SG_ 938 PrkAidSnsFlCntr_D_Stat 1;
BA_ "U_CD4_MY14_Diesel_Tx" SG_ 938 PrkAidSnsFlCntr_D_Stat 1;
BA_ "U_CD4_MY14_Gas_Tx" SG_ 938 PrkAidSnsFlCntr_D_Stat 1;
BA_ "U_CD4_MY14_Hev_Tx" SG_ 938 PrkAidSnsFlCntr_D_Stat 1;
BA_ "U_CD4_MY14_Phev_Tx" SG_ 938 PrkAidSnsFlCntr_D_Stat 1;
BA_ "CrossOver_InfoCAN" SG_ 938 RpaChime_D_Rq 1;
BA_ "GenSigSendType" SG_ 938 RpaChime_D_Rq 3;
BA_ "U_CD4_MY13_Diesel_Tx" SG_ 938 RpaChime_D_Rq 1;
BA_ "U_CD4_MY13_Gas_Tx" SG_ 938 RpaChime_D_Rq 1;
BA_ "U_CD4_MY13_Hev_Tx" SG_ 938 RpaChime_D_Rq 1;
BA_ "U_CD4_MY13_Phev_Tx" SG_ 938 RpaChime_D_Rq 1;
BA_ "U_CD42_MY14_Diesel_Tx" SG_ 938 RpaChime_D_Rq 1;
BA_ "U_CD42_MY14_Gas_Tx" SG_ 938 RpaChime_D_Rq 1;
BA_ "U_P552_MY15_Gas_Tx" SG_ 938 RpaChime_D_Rq 1;
BA_ "U_S550_MY15_Gas_Tx" SG_ 938 RpaChime_D_Rq 1;
BA_ "U_C489_MY14_Gas_Tx" SG_ 938 RpaChime_D_Rq 1;
BA_ "U_U502_MY15_Gas_Tx" SG_ 938 RpaChime_D_Rq 1;
BA_ "U_UP375_MY15_Gas_Tx" SG_ 938 RpaChime_D_Rq 1;
BA_ "U_UP375_MY15_Diesel_Tx" SG_ 938 RpaChime_D_Rq 1;
BA_ "U_CD43_MY16_Gas_Tx" SG_ 938 RpaChime_D_Rq 1;
BA_ "U_CD4_MY14_Diesel_Tx" SG_ 938 RpaChime_D_Rq 1;
BA_ "U_CD4_MY14_Gas_Tx" SG_ 938 RpaChime_D_Rq 1;
BA_ "U_CD4_MY14_Hev_Tx" SG_ 938 RpaChime_D_Rq 1;
BA_ "U_CD4_MY14_Phev_Tx" SG_ 938 RpaChime_D_Rq 1;
BA_ "CrossOver_InfoCAN" SG_ 938 FpaChime_D_Rq 1;
BA_ "GenSigSendType" SG_ 938 FpaChime_D_Rq 3;
BA_ "U_CD4_MY13_Diesel_Tx" SG_ 938 FpaChime_D_Rq 1;
BA_ "U_CD4_MY13_Gas_Tx" SG_ 938 FpaChime_D_Rq 1;
BA_ "U_CD4_MY13_Hev_Tx" SG_ 938 FpaChime_D_Rq 1;
BA_ "U_CD4_MY13_Phev_Tx" SG_ 938 FpaChime_D_Rq 1;
BA_ "U_CD42_MY14_Diesel_Tx" SG_ 938 FpaChime_D_Rq 1;
BA_ "U_CD42_MY14_Gas_Tx" SG_ 938 FpaChime_D_Rq 1;
BA_ "U_P552_MY15_Gas_Tx" SG_ 938 FpaChime_D_Rq 1;
BA_ "U_S550_MY15_Gas_Tx" SG_ 938 FpaChime_D_Rq 1;
BA_ "U_C489_MY14_Gas_Tx" SG_ 938 FpaChime_D_Rq 1;
BA_ "U_U502_MY15_Gas_Tx" SG_ 938 FpaChime_D_Rq 1;
BA_ "U_UP375_MY15_Gas_Tx" SG_ 938 FpaChime_D_Rq 1;
BA_ "U_UP375_MY15_Diesel_Tx" SG_ 938 FpaChime_D_Rq 1;
BA_ "U_CD43_MY16_Gas_Tx" SG_ 938 FpaChime_D_Rq 1;
BA_ "U_CD4_MY14_Diesel_Tx" SG_ 938 FpaChime_D_Rq 1;
BA_ "U_CD4_MY14_Gas_Tx" SG_ 938 FpaChime_D_Rq 1;
BA_ "U_CD4_MY14_Hev_Tx" SG_ 938 FpaChime_D_Rq 1;
BA_ "U_CD4_MY14_Phev_Tx" SG_ 938 FpaChime_D_Rq 1;
BA_ "CrossOver_InfoCAN" SG_ 938 PrkAidMsgTxt_D_Rq 1;
BA_ "GenSigSendType" SG_ 938 PrkAidMsgTxt_D_Rq 3;
BA_ "U_CD4_MY13_Diesel_Tx" SG_ 938 PrkAidMsgTxt_D_Rq 1;
BA_ "U_CD4_MY13_Gas_Tx" SG_ 938 PrkAidMsgTxt_D_Rq 1;
BA_ "U_CD4_MY13_Hev_Tx" SG_ 938 PrkAidMsgTxt_D_Rq 1;
BA_ "U_CD4_MY13_Phev_Tx" SG_ 938 PrkAidMsgTxt_D_Rq 1;
BA_ "U_CD42_MY14_Diesel_Tx" SG_ 938 PrkAidMsgTxt_D_Rq 1;
BA_ "U_CD42_MY14_Gas_Tx" SG_ 938 PrkAidMsgTxt_D_Rq 1;
BA_ "U_P552_MY15_Gas_Tx" SG_ 938 PrkAidMsgTxt_D_Rq 1;
BA_ "U_S550_MY15_Gas_Tx" SG_ 938 PrkAidMsgTxt_D_Rq 1;
BA_ "U_C489_MY14_Gas_Tx" SG_ 938 PrkAidMsgTxt_D_Rq 1;
BA_ "U_U502_MY15_Gas_Tx" SG_ 938 PrkAidMsgTxt_D_Rq 1;
BA_ "U_UP375_MY15_Gas_Tx" SG_ 938 PrkAidMsgTxt_D_Rq 1;
BA_ "U_UP375_MY15_Diesel_Tx" SG_ 938 PrkAidMsgTxt_D_Rq 1;
BA_ "U_CD43_MY16_Gas_Tx" SG_ 938 PrkAidMsgTxt_D_Rq 1;
BA_ "U_CD4_MY14_Diesel_Tx" SG_ 938 PrkAidMsgTxt_D_Rq 1;
BA_ "U_CD4_MY14_Gas_Tx" SG_ 938 PrkAidMsgTxt_D_Rq 1;
BA_ "U_CD4_MY14_Hev_Tx" SG_ 938 PrkAidMsgTxt_D_Rq 1;
BA_ "U_CD4_MY14_Phev_Tx" SG_ 938 PrkAidMsgTxt_D_Rq 1;
BA_ "CrossOver_InfoCAN" SG_ 938 PrkAidAudioMute_B_Rq 1;
BA_ "GenSigSendType" SG_ 938 PrkAidAudioMute_B_Rq 3;
BA_ "U_CD4_MY13_Diesel_Tx" SG_ 938 PrkAidAudioMute_B_Rq 1;
BA_ "U_CD4_MY13_Gas_Tx" SG_ 938 PrkAidAudioMute_B_Rq 1;
BA_ "U_CD4_MY13_Hev_Tx" SG_ 938 PrkAidAudioMute_B_Rq 1;
BA_ "U_CD4_MY13_Phev_Tx" SG_ 938 PrkAidAudioMute_B_Rq 1;
BA_ "U_CD42_MY14_Diesel_Tx" SG_ 938 PrkAidAudioMute_B_Rq 1;
BA_ "U_CD42_MY14_Gas_Tx" SG_ 938 PrkAidAudioMute_B_Rq 1;
BA_ "U_P552_MY15_Gas_Tx" SG_ 938 PrkAidAudioMute_B_Rq 1;
BA_ "U_S550_MY15_Gas_Tx" SG_ 938 PrkAidAudioMute_B_Rq 1;
BA_ "U_C489_MY14_Gas_Tx" SG_ 938 PrkAidAudioMute_B_Rq 1;
BA_ "U_U502_MY15_Gas_Tx" SG_ 938 PrkAidAudioMute_B_Rq 1;
BA_ "U_UP375_MY15_Gas_Tx" SG_ 938 PrkAidAudioMute_B_Rq 1;
BA_ "U_UP375_MY15_Diesel_Tx" SG_ 938 PrkAidAudioMute_B_Rq 1;
BA_ "U_CD43_MY16_Gas_Tx" SG_ 938 PrkAidAudioMute_B_Rq 1;
BA_ "U_CD4_MY14_Diesel_Tx" SG_ 938 PrkAidAudioMute_B_Rq 1;
BA_ "U_CD4_MY14_Gas_Tx" SG_ 938 PrkAidAudioMute_B_Rq 1;
BA_ "U_CD4_MY14_Hev_Tx" SG_ 938 PrkAidAudioMute_B_Rq 1;
BA_ "U_CD4_MY14_Phev_Tx" SG_ 938 PrkAidAudioMute_B_Rq 1;
BA_ "U_V36X_MY18_5_Hev_Tx" SG_ 963 WrlssAcsyChrgInhbt_B_Rq 1;
BA_ "U_V36X_MY18_5_Gas_Tx" SG_ 963 WrlssAcsyChrgInhbt_B_Rq 1;
BA_ "U_V363E_N_MY19_5_20_Diesel_Tx" SG_ 963 WrlssAcsyChrgInhbt_B_Rq 1;
BA_ "U_V363E_N_MY19_5_20_Gas_Tx" SG_ 963 WrlssAcsyChrgInhbt_B_Rq 1;
BA_ "U_P552_MY18_5_Diesel_Tx" SG_ 963 WrlssAcsyChrgInhbt_B_Rq 1;
BA_ "U_P552_MY18_5_Gas_Tx" SG_ 963 WrlssAcsyChrgInhbt_B_Rq 1;
BA_ "U_V408_MY18_Diesel_Tx" SG_ 963 WrlssAcsyChrgInhbt_B_Rq 1;
BA_ "U_V408_MY18_Gas_Tx" SG_ 963 WrlssAcsyChrgInhbt_B_Rq 1;
BA_ "U_U55x_MY18_Gas_Tx" SG_ 963 WrlssAcsyChrgInhbt_B_Rq 1;
BA_ "GenSigSendType" SG_ 963 WrlssAcsyChrgInhbt_B_Rq 3;
BA_ "U_V36X_MY16_5_Diesel_Tx" SG_ 963 PudLampPsngr_D_Rq 1;
BA_ "U_CD4_MY15_Phev_Tx" SG_ 963 PudLampPsngr_D_Rq 1;
BA_ "U_CD4_MY15_Hev_Tx" SG_ 963 PudLampPsngr_D_Rq 1;
BA_ "U_CD4_MY15_Gas_Tx" SG_ 963 PudLampPsngr_D_Rq 1;
BA_ "U_CD4_MY15_Diesel_Tx" SG_ 963 PudLampPsngr_D_Rq 1;
BA_ "U_UP375_MY15_Diesel_Tx" SG_ 963 PudLampPsngr_D_Rq 1;
BA_ "U_UP375_MY15_Gas_Tx" SG_ 963 PudLampPsngr_D_Rq 1;
BA_ "U_U502_MY16_Gas_Tx" SG_ 963 PudLampPsngr_D_Rq 1;
BA_ "U_C489_MY14_Gas_Tx" SG_ 963 PudLampPsngr_D_Rq 1;
BA_ "U_S550_MY15_Gas_Tx" SG_ 963 PudLampPsngr_D_Rq 1;
BA_ "GenSigSendType" SG_ 963 PudLampPsngr_D_Rq 3;
BA_ "U_V36X_MY16_5_Diesel_Tx" SG_ 963 PudLampDrv_D_Rq 1;
BA_ "U_CD4_MY15_Phev_Tx" SG_ 963 PudLampDrv_D_Rq 1;
BA_ "U_CD4_MY15_Hev_Tx" SG_ 963 PudLampDrv_D_Rq 1;
BA_ "U_CD4_MY15_Gas_Tx" SG_ 963 PudLampDrv_D_Rq 1;
BA_ "U_CD4_MY15_Diesel_Tx" SG_ 963 PudLampDrv_D_Rq 1;
BA_ "U_UP375_MY15_Diesel_Tx" SG_ 963 PudLampDrv_D_Rq 1;
BA_ "U_UP375_MY15_Gas_Tx" SG_ 963 PudLampDrv_D_Rq 1;
BA_ "U_U502_MY16_Gas_Tx" SG_ 963 PudLampDrv_D_Rq 1;
BA_ "U_C489_MY14_Gas_Tx" SG_ 963 PudLampDrv_D_Rq 1;
BA_ "U_S550_MY15_Gas_Tx" SG_ 963 PudLampDrv_D_Rq 1;
BA_ "GenSigSendType" SG_ 963 PudLampDrv_D_Rq 3;
BA_ "U_V36X_MY16_5_Diesel_Tx" SG_ 963 DrTgateLck_D_Stat 1;
BA_ "U_CD4_MY15_Phev_Tx" SG_ 963 DrTgateLck_D_Stat 1;
BA_ "U_CD4_MY15_Hev_Tx" SG_ 963 DrTgateLck_D_Stat 1;
BA_ "U_CD4_MY15_Gas_Tx" SG_ 963 DrTgateLck_D_Stat 1;
BA_ "U_CD4_MY15_Diesel_Tx" SG_ 963 DrTgateLck_D_Stat 1;
BA_ "U_CD43_MY16_Gas_Tx" SG_ 963 DrTgateLck_D_Stat 1;
BA_ "U_UP375_MY15_Diesel_Tx" SG_ 963 DrTgateLck_D_Stat 1;
BA_ "U_UP375_MY15_Gas_Tx" SG_ 963 DrTgateLck_D_Stat 1;
BA_ "U_U502_MY16_Gas_Tx" SG_ 963 DrTgateLck_D_Stat 1;
BA_ "U_C489_MY14_Gas_Tx" SG_ 963 DrTgateLck_D_Stat 1;
BA_ "U_S550_MY15_Gas_Tx" SG_ 963 DrTgateLck_D_Stat 1;
BA_ "U_CD42_MY15_Gas_Tx" SG_ 963 DrTgateLck_D_Stat 1;
BA_ "U_CD42_MY15_Diesel_Tx" SG_ 963 DrTgateLck_D_Stat 1;
BA_ "GenSigSendType" SG_ 963 DrTgateLck_D_Stat 3;
BA_ "GenSigSendType" SG_ 963 Illuminated_Entry_Stat 3;
BA_ "U_P552_MY15_Gas_Tx" SG_ 963 Illuminated_Entry_Stat 1;
BA_ "U_S550_MY15_Gas_Tx" SG_ 963 Illuminated_Entry_Stat 1;
BA_ "U_C489_MY14_Gas_Tx" SG_ 963 Illuminated_Entry_Stat 1;
BA_ "U_U502_MY15_Gas_Tx" SG_ 963 Illuminated_Entry_Stat 1;
BA_ "U_CD43_MY16_Gas_Tx" SG_ 963 Illuminated_Entry_Stat 1;
BA_ "U_CD4_MY14_Diesel_Tx" SG_ 963 Illuminated_Entry_Stat 1;
BA_ "U_CD4_MY14_Gas_Tx" SG_ 963 Illuminated_Entry_Stat 1;
BA_ "U_CD4_MY14_Hev_Tx" SG_ 963 Illuminated_Entry_Stat 1;
BA_ "U_CD4_MY14_Phev_Tx" SG_ 963 Illuminated_Entry_Stat 1;
BA_ "GenSigSendType" SG_ 963 Dr_Courtesy_Light_Stat 3;
BA_ "U_P552_MY15_Gas_Tx" SG_ 963 Dr_Courtesy_Light_Stat 1;
BA_ "U_S550_MY15_Gas_Tx" SG_ 963 Dr_Courtesy_Light_Stat 1;
BA_ "U_C489_MY14_Gas_Tx" SG_ 963 Dr_Courtesy_Light_Stat 1;
BA_ "U_U502_MY15_Gas_Tx" SG_ 963 Dr_Courtesy_Light_Stat 1;
BA_ "U_CD43_MY16_Gas_Tx" SG_ 963 Dr_Courtesy_Light_Stat 1;
BA_ "U_CD4_MY14_Diesel_Tx" SG_ 963 Dr_Courtesy_Light_Stat 1;
BA_ "U_CD4_MY14_Gas_Tx" SG_ 963 Dr_Courtesy_Light_Stat 1;
BA_ "U_CD4_MY14_Hev_Tx" SG_ 963 Dr_Courtesy_Light_Stat 1;
BA_ "U_CD4_MY14_Phev_Tx" SG_ 963 Dr_Courtesy_Light_Stat 1;
BA_ "GenSigSendType" SG_ 963 Courtesy_Delay_Status 3;
BA_ "U_P552_MY15_Gas_Tx" SG_ 963 Courtesy_Delay_Status 1;
BA_ "U_S550_MY15_Gas_Tx" SG_ 963 Courtesy_Delay_Status 1;
BA_ "U_C489_MY14_Gas_Tx" SG_ 963 Courtesy_Delay_Status 1;
BA_ "U_U502_MY15_Gas_Tx" SG_ 963 Courtesy_Delay_Status 1;
BA_ "U_CD43_MY16_Gas_Tx" SG_ 963 Courtesy_Delay_Status 1;
BA_ "U_CD4_MY14_Diesel_Tx" SG_ 963 Courtesy_Delay_Status 1;
BA_ "U_CD4_MY14_Gas_Tx" SG_ 963 Courtesy_Delay_Status 1;
BA_ "U_CD4_MY14_Hev_Tx" SG_ 963 Courtesy_Delay_Status 1;
BA_ "U_CD4_MY14_Phev_Tx" SG_ 963 Courtesy_Delay_Status 1;
BA_ "WakeupSignal" SG_ 963 ImpactEvntFdbck_D_Stat 1;
BA_ "CrossOver_InfoCAN" SG_ 963 ImpactEvntFdbck_D_Stat 1;
BA_ "GenSigSendType" SG_ 963 ImpactEvntFdbck_D_Stat 3;
BA_ "U_CD4_MY13_Diesel_Tx" SG_ 963 ImpactEvntFdbck_D_Stat 1;
BA_ "U_CD4_MY13_Gas_Tx" SG_ 963 ImpactEvntFdbck_D_Stat 1;
BA_ "U_CD4_MY13_Hev_Tx" SG_ 963 ImpactEvntFdbck_D_Stat 1;
BA_ "U_CD4_MY13_Phev_Tx" SG_ 963 ImpactEvntFdbck_D_Stat 1;
BA_ "U_CD42_MY14_Diesel_Tx" SG_ 963 ImpactEvntFdbck_D_Stat 1;
BA_ "U_CD42_MY14_Gas_Tx" SG_ 963 ImpactEvntFdbck_D_Stat 1;
BA_ "U_P552_MY15_Gas_Tx" SG_ 963 ImpactEvntFdbck_D_Stat 1;
BA_ "U_S550_MY15_Gas_Tx" SG_ 963 ImpactEvntFdbck_D_Stat 1;
BA_ "U_C489_MY14_Gas_Tx" SG_ 963 ImpactEvntFdbck_D_Stat 1;
BA_ "U_U502_MY15_Gas_Tx" SG_ 963 ImpactEvntFdbck_D_Stat 1;
BA_ "U_UP375_MY15_Gas_Tx" SG_ 963 ImpactEvntFdbck_D_Stat 1;
BA_ "U_UP375_MY15_Diesel_Tx" SG_ 963 ImpactEvntFdbck_D_Stat 1;
BA_ "U_CD43_MY16_Gas_Tx" SG_ 963 ImpactEvntFdbck_D_Stat 1;
BA_ "U_CD4_MY14_Diesel_Tx" SG_ 963 ImpactEvntFdbck_D_Stat 1;
BA_ "U_CD4_MY14_Gas_Tx" SG_ 963 ImpactEvntFdbck_D_Stat 1;
BA_ "U_CD4_MY14_Hev_Tx" SG_ 963 ImpactEvntFdbck_D_Stat 1;
BA_ "U_CD4_MY14_Phev_Tx" SG_ 963 ImpactEvntFdbck_D_Stat 1;
BA_ "CrossOver_InfoCAN" SG_ 963 HeadLampLoOut_B_Stat 1;
BA_ "GenSigSendType" SG_ 963 HeadLampLoOut_B_Stat 3;
BA_ "U_CD4_MY13_Diesel_Tx" SG_ 963 HeadLampLoOut_B_Stat 1;
BA_ "U_CD4_MY13_Gas_Tx" SG_ 963 HeadLampLoOut_B_Stat 1;
BA_ "U_CD4_MY13_Hev_Tx" SG_ 963 HeadLampLoOut_B_Stat 1;
BA_ "U_CD4_MY13_Phev_Tx" SG_ 963 HeadLampLoOut_B_Stat 1;
BA_ "U_CD42_MY14_Diesel_Tx" SG_ 963 HeadLampLoOut_B_Stat 1;
BA_ "U_CD42_MY14_Gas_Tx" SG_ 963 HeadLampLoOut_B_Stat 1;
BA_ "U_P552_MY15_Gas_Tx" SG_ 963 HeadLampLoOut_B_Stat 1;
BA_ "U_S550_MY15_Gas_Tx" SG_ 963 HeadLampLoOut_B_Stat 1;
BA_ "U_C489_MY14_Gas_Tx" SG_ 963 HeadLampLoOut_B_Stat 1;
BA_ "U_U502_MY15_Gas_Tx" SG_ 963 HeadLampLoOut_B_Stat 1;
BA_ "U_UP375_MY15_Gas_Tx" SG_ 963 HeadLampLoOut_B_Stat 1;
BA_ "U_UP375_MY15_Diesel_Tx" SG_ 963 HeadLampLoOut_B_Stat 1;
BA_ "U_CD43_MY16_Gas_Tx" SG_ 963 HeadLampLoOut_B_Stat 1;
BA_ "U_CD4_MY14_Diesel_Tx" SG_ 963 HeadLampLoOut_B_Stat 1;
BA_ "U_CD4_MY14_Gas_Tx" SG_ 963 HeadLampLoOut_B_Stat 1;
BA_ "U_CD4_MY14_Hev_Tx" SG_ 963 HeadLampLoOut_B_Stat 1;
BA_ "U_CD4_MY14_Phev_Tx" SG_ 963 HeadLampLoOut_B_Stat 1;
BA_ "CrossOver_InfoCAN" SG_ 963 CrnrLghtRight_Pc_Rq 1;
BA_ "GenSigSendType" SG_ 963 CrnrLghtRight_Pc_Rq 3;
BA_ "U_CD4_MY13_Diesel_Tx" SG_ 963 CrnrLghtRight_Pc_Rq 1;
BA_ "U_CD4_MY13_Gas_Tx" SG_ 963 CrnrLghtRight_Pc_Rq 1;
BA_ "U_CD4_MY13_Hev_Tx" SG_ 963 CrnrLghtRight_Pc_Rq 1;
BA_ "U_CD4_MY13_Phev_Tx" SG_ 963 CrnrLghtRight_Pc_Rq 1;
BA_ "U_CD42_MY14_Diesel_Tx" SG_ 963 CrnrLghtRight_Pc_Rq 1;
BA_ "U_CD42_MY14_Gas_Tx" SG_ 963 CrnrLghtRight_Pc_Rq 1;
BA_ "U_P552_MY15_Gas_Tx" SG_ 963 CrnrLghtRight_Pc_Rq 1;
BA_ "U_S550_MY15_Gas_Tx" SG_ 963 CrnrLghtRight_Pc_Rq 1;
BA_ "U_C489_MY14_Gas_Tx" SG_ 963 CrnrLghtRight_Pc_Rq 1;
BA_ "U_U502_MY15_Gas_Tx" SG_ 963 CrnrLghtRight_Pc_Rq 1;
BA_ "U_UP375_MY15_Gas_Tx" SG_ 963 CrnrLghtRight_Pc_Rq 1;
BA_ "U_UP375_MY15_Diesel_Tx" SG_ 963 CrnrLghtRight_Pc_Rq 1;
BA_ "U_CD43_MY16_Gas_Tx" SG_ 963 CrnrLghtRight_Pc_Rq 1;
BA_ "U_CD4_MY14_Diesel_Tx" SG_ 963 CrnrLghtRight_Pc_Rq 1;
BA_ "U_CD4_MY14_Gas_Tx" SG_ 963 CrnrLghtRight_Pc_Rq 1;
BA_ "U_CD4_MY14_Hev_Tx" SG_ 963 CrnrLghtRight_Pc_Rq 1;
BA_ "U_CD4_MY14_Phev_Tx" SG_ 963 CrnrLghtRight_Pc_Rq 1;
BA_ "CrossOver_InfoCAN" SG_ 963 CrnrLghtLeft_Pc_Rq 1;
BA_ "GenSigSendType" SG_ 963 CrnrLghtLeft_Pc_Rq 3;
BA_ "U_CD4_MY13_Diesel_Tx" SG_ 963 CrnrLghtLeft_Pc_Rq 1;
BA_ "U_CD4_MY13_Gas_Tx" SG_ 963 CrnrLghtLeft_Pc_Rq 1;
BA_ "U_CD4_MY13_Hev_Tx" SG_ 963 CrnrLghtLeft_Pc_Rq 1;
BA_ "U_CD4_MY13_Phev_Tx" SG_ 963 CrnrLghtLeft_Pc_Rq 1;
BA_ "U_CD42_MY14_Diesel_Tx" SG_ 963 CrnrLghtLeft_Pc_Rq 1;
BA_ "U_CD42_MY14_Gas_Tx" SG_ 963 CrnrLghtLeft_Pc_Rq 1;
BA_ "U_P552_MY15_Gas_Tx" SG_ 963 CrnrLghtLeft_Pc_Rq 1;
BA_ "U_S550_MY15_Gas_Tx" SG_ 963 CrnrLghtLeft_Pc_Rq 1;
BA_ "U_C489_MY14_Gas_Tx" SG_ 963 CrnrLghtLeft_Pc_Rq 1;
BA_ "U_U502_MY15_Gas_Tx" SG_ 963 CrnrLghtLeft_Pc_Rq 1;
BA_ "U_UP375_MY15_Gas_Tx" SG_ 963 CrnrLghtLeft_Pc_Rq 1;
BA_ "U_UP375_MY15_Diesel_Tx" SG_ 963 CrnrLghtLeft_Pc_Rq 1;
BA_ "U_CD43_MY16_Gas_Tx" SG_ 963 CrnrLghtLeft_Pc_Rq 1;
BA_ "U_CD4_MY14_Diesel_Tx" SG_ 963 CrnrLghtLeft_Pc_Rq 1;
BA_ "U_CD4_MY14_Gas_Tx" SG_ 963 CrnrLghtLeft_Pc_Rq 1;
BA_ "U_CD4_MY14_Hev_Tx" SG_ 963 CrnrLghtLeft_Pc_Rq 1;
BA_ "U_CD4_MY14_Phev_Tx" SG_ 963 CrnrLghtLeft_Pc_Rq 1;
BA_ "CrossOver_InfoCAN" SG_ 963 HeadLghtHiFdbck_D_Stat 1;
BA_ "GenSigSendType" SG_ 963 HeadLghtHiFdbck_D_Stat 3;
BA_ "U_CD4_MY13_Diesel_Tx" SG_ 963 HeadLghtHiFdbck_D_Stat 1;
BA_ "U_CD4_MY13_Gas_Tx" SG_ 963 HeadLghtHiFdbck_D_Stat 1;
BA_ "U_CD4_MY13_Hev_Tx" SG_ 963 HeadLghtHiFdbck_D_Stat 1;
BA_ "U_CD4_MY13_Phev_Tx" SG_ 963 HeadLghtHiFdbck_D_Stat 1;
BA_ "U_CD42_MY14_Diesel_Tx" SG_ 963 HeadLghtHiFdbck_D_Stat 1;
BA_ "U_CD42_MY14_Gas_Tx" SG_ 963 HeadLghtHiFdbck_D_Stat 1;
BA_ "U_P552_MY15_Gas_Tx" SG_ 963 HeadLghtHiFdbck_D_Stat 1;
BA_ "U_S550_MY15_Gas_Tx" SG_ 963 HeadLghtHiFdbck_D_Stat 1;
BA_ "U_C489_MY14_Gas_Tx" SG_ 963 HeadLghtHiFdbck_D_Stat 1;
BA_ "U_U502_MY15_Gas_Tx" SG_ 963 HeadLghtHiFdbck_D_Stat 1;
BA_ "U_UP375_MY15_Gas_Tx" SG_ 963 HeadLghtHiFdbck_D_Stat 1;
BA_ "U_UP375_MY15_Diesel_Tx" SG_ 963 HeadLghtHiFdbck_D_Stat 1;
BA_ "U_CD43_MY16_Gas_Tx" SG_ 963 HeadLghtHiFdbck_D_Stat 1;
BA_ "U_CD4_MY14_Diesel_Tx" SG_ 963 HeadLghtHiFdbck_D_Stat 1;
BA_ "U_CD4_MY14_Gas_Tx" SG_ 963 HeadLghtHiFdbck_D_Stat 1;
BA_ "U_CD4_MY14_Hev_Tx" SG_ 963 HeadLghtHiFdbck_D_Stat 1;
BA_ "U_CD4_MY14_Phev_Tx" SG_ 963 HeadLghtHiFdbck_D_Stat 1;
BA_ "CrossOver_InfoCAN" SG_ 963 TrnNotInPrkChime_B_Rq 1;
BA_ "GenSigSendType" SG_ 963 TrnNotInPrkChime_B_Rq 3;
BA_ "U_CD4_MY13_Diesel_Tx" SG_ 963 TrnNotInPrkChime_B_Rq 1;
BA_ "U_CD4_MY13_Gas_Tx" SG_ 963 TrnNotInPrkChime_B_Rq 1;
BA_ "U_CD4_MY13_Hev_Tx" SG_ 963 TrnNotInPrkChime_B_Rq 1;
BA_ "U_CD4_MY13_Phev_Tx" SG_ 963 TrnNotInPrkChime_B_Rq 1;
BA_ "U_CD42_MY14_Diesel_Tx" SG_ 963 TrnNotInPrkChime_B_Rq 1;
BA_ "U_CD42_MY14_Gas_Tx" SG_ 963 TrnNotInPrkChime_B_Rq 1;
BA_ "U_P552_MY15_Gas_Tx" SG_ 963 TrnNotInPrkChime_B_Rq 1;
BA_ "U_S550_MY15_Gas_Tx" SG_ 963 TrnNotInPrkChime_B_Rq 1;
BA_ "U_C489_MY14_Gas_Tx" SG_ 963 TrnNotInPrkChime_B_Rq 1;
BA_ "U_U502_MY15_Gas_Tx" SG_ 963 TrnNotInPrkChime_B_Rq 1;
BA_ "U_UP375_MY15_Gas_Tx" SG_ 963 TrnNotInPrkChime_B_Rq 1;
BA_ "U_UP375_MY15_Diesel_Tx" SG_ 963 TrnNotInPrkChime_B_Rq 1;
BA_ "U_CD43_MY16_Gas_Tx" SG_ 963 TrnNotInPrkChime_B_Rq 1;
BA_ "U_CD4_MY14_Diesel_Tx" SG_ 963 TrnNotInPrkChime_B_Rq 1;
BA_ "U_CD4_MY14_Gas_Tx" SG_ 963 TrnNotInPrkChime_B_Rq 1;
BA_ "U_CD4_MY14_Hev_Tx" SG_ 963 TrnNotInPrkChime_B_Rq 1;
BA_ "U_CD4_MY14_Phev_Tx" SG_ 963 TrnNotInPrkChime_B_Rq 1;
BA_ "CrossOver_InfoCAN" SG_ 963 PrkLightChime_B_Rq 1;
BA_ "GenSigSendType" SG_ 963 PrkLightChime_B_Rq 3;
BA_ "U_CD4_MY13_Diesel_Tx" SG_ 963 PrkLightChime_B_Rq 1;
BA_ "U_CD4_MY13_Gas_Tx" SG_ 963 PrkLightChime_B_Rq 1;
BA_ "U_CD4_MY13_Hev_Tx" SG_ 963 PrkLightChime_B_Rq 1;
BA_ "U_CD4_MY13_Phev_Tx" SG_ 963 PrkLightChime_B_Rq 1;
BA_ "U_CD42_MY14_Diesel_Tx" SG_ 963 PrkLightChime_B_Rq 1;
BA_ "U_CD42_MY14_Gas_Tx" SG_ 963 PrkLightChime_B_Rq 1;
BA_ "U_P552_MY15_Gas_Tx" SG_ 963 PrkLightChime_B_Rq 1;
BA_ "U_S550_MY15_Gas_Tx" SG_ 963 PrkLightChime_B_Rq 1;
BA_ "U_C489_MY14_Gas_Tx" SG_ 963 PrkLightChime_B_Rq 1;
BA_ "U_U502_MY15_Gas_Tx" SG_ 963 PrkLightChime_B_Rq 1;
BA_ "U_UP375_MY15_Gas_Tx" SG_ 963 PrkLightChime_B_Rq 1;
BA_ "U_UP375_MY15_Diesel_Tx" SG_ 963 PrkLightChime_B_Rq 1;
BA_ "U_CD43_MY16_Gas_Tx" SG_ 963 PrkLightChime_B_Rq 1;
BA_ "U_CD4_MY14_Diesel_Tx" SG_ 963 PrkLightChime_B_Rq 1;
BA_ "U_CD4_MY14_Gas_Tx" SG_ 963 PrkLightChime_B_Rq 1;
BA_ "U_CD4_MY14_Hev_Tx" SG_ 963 PrkLightChime_B_Rq 1;
BA_ "U_CD4_MY14_Phev_Tx" SG_ 963 PrkLightChime_B_Rq 1;
BA_ "WakeupSignal" SG_ 963 KeyInIgnWarn_B_Cmd 1;
BA_ "CrossOver_InfoCAN" SG_ 963 KeyInIgnWarn_B_Cmd 1;
BA_ "GenSigSendType" SG_ 963 KeyInIgnWarn_B_Cmd 3;
BA_ "U_CD4_MY13_Diesel_Rx" SG_ 963 KeyInIgnWarn_B_Cmd 1;
BA_ "U_CD4_MY13_Gas_Rx" SG_ 963 KeyInIgnWarn_B_Cmd 1;
BA_ "U_CD4_MY13_Hev_Rx" SG_ 963 KeyInIgnWarn_B_Cmd 1;
BA_ "U_CD4_MY13_Phev_Rx" SG_ 963 KeyInIgnWarn_B_Cmd 1;
BA_ "U_CD42_MY14_Diesel_Rx" SG_ 963 KeyInIgnWarn_B_Cmd 1;
BA_ "U_CD42_MY14_Gas_Rx" SG_ 963 KeyInIgnWarn_B_Cmd 1;
BA_ "U_P552_MY15_Gas_Rx" SG_ 963 KeyInIgnWarn_B_Cmd 1;
BA_ "U_S550_MY15_Gas_Rx" SG_ 963 KeyInIgnWarn_B_Cmd 1;
BA_ "U_C489_MY14_Gas_Rx" SG_ 963 KeyInIgnWarn_B_Cmd 1;
BA_ "U_U502_MY15_Gas_Rx" SG_ 963 KeyInIgnWarn_B_Cmd 1;
BA_ "U_B479_MY15_Gas_Rx" SG_ 963 KeyInIgnWarn_B_Cmd 1;
BA_ "U_UP375_MY15_Gas_Rx" SG_ 963 KeyInIgnWarn_B_Cmd 1;
BA_ "U_UP375_MY15_Diesel_Rx" SG_ 963 KeyInIgnWarn_B_Cmd 1;
BA_ "U_CD4_MY13_Diesel_Tx" SG_ 963 KeyInIgnWarn_B_Cmd 1;
BA_ "U_CD4_MY13_Gas_Tx" SG_ 963 KeyInIgnWarn_B_Cmd 1;
BA_ "U_CD4_MY13_Hev_Tx" SG_ 963 KeyInIgnWarn_B_Cmd 1;
BA_ "U_CD4_MY13_Phev_Tx" SG_ 963 KeyInIgnWarn_B_Cmd 1;
BA_ "U_CD42_MY14_Diesel_Tx" SG_ 963 KeyInIgnWarn_B_Cmd 1;
BA_ "U_CD42_MY14_Gas_Tx" SG_ 963 KeyInIgnWarn_B_Cmd 1;
BA_ "U_P552_MY15_Gas_Tx" SG_ 963 KeyInIgnWarn_B_Cmd 1;
BA_ "U_S550_MY15_Gas_Tx" SG_ 963 KeyInIgnWarn_B_Cmd 1;
BA_ "U_C489_MY14_Gas_Tx" SG_ 963 KeyInIgnWarn_B_Cmd 1;
BA_ "U_U502_MY15_Gas_Tx" SG_ 963 KeyInIgnWarn_B_Cmd 1;
BA_ "U_UP375_MY15_Gas_Tx" SG_ 963 KeyInIgnWarn_B_Cmd 1;
BA_ "U_UP375_MY15_Diesel_Tx" SG_ 963 KeyInIgnWarn_B_Cmd 1;
BA_ "U_CD43_MY16_Gas_Tx" SG_ 963 KeyInIgnWarn_B_Cmd 1;
BA_ "U_CD4_MY14_Diesel_Tx" SG_ 963 KeyInIgnWarn_B_Cmd 1;
BA_ "U_CD4_MY14_Gas_Tx" SG_ 963 KeyInIgnWarn_B_Cmd 1;
BA_ "U_CD4_MY14_Hev_Tx" SG_ 963 KeyInIgnWarn_B_Cmd 1;
BA_ "U_CD4_MY14_Phev_Tx" SG_ 963 KeyInIgnWarn_B_Cmd 1;
BA_ "WakeupSignal" SG_ 963 HomeSafeLtChime_B_Rq 1;
BA_ "CrossOver_InfoCAN" SG_ 963 HomeSafeLtChime_B_Rq 1;
BA_ "GenSigSendType" SG_ 963 HomeSafeLtChime_B_Rq 3;
BA_ "U_CD4_MY13_Diesel_Rx" SG_ 963 HomeSafeLtChime_B_Rq 1;
BA_ "U_CD4_MY13_Gas_Rx" SG_ 963 HomeSafeLtChime_B_Rq 1;
BA_ "U_CD4_MY13_Hev_Rx" SG_ 963 HomeSafeLtChime_B_Rq 1;
BA_ "U_CD4_MY13_Phev_Rx" SG_ 963 HomeSafeLtChime_B_Rq 1;
BA_ "U_CD42_MY14_Diesel_Rx" SG_ 963 HomeSafeLtChime_B_Rq 1;
BA_ "U_CD42_MY14_Gas_Rx" SG_ 963 HomeSafeLtChime_B_Rq 1;
BA_ "U_P552_MY15_Gas_Rx" SG_ 963 HomeSafeLtChime_B_Rq 1;
BA_ "U_S550_MY15_Gas_Rx" SG_ 963 HomeSafeLtChime_B_Rq 1;
BA_ "U_C489_MY14_Gas_Rx" SG_ 963 HomeSafeLtChime_B_Rq 1;
BA_ "U_U502_MY15_Gas_Rx" SG_ 963 HomeSafeLtChime_B_Rq 1;
BA_ "U_B479_MY15_Gas_Rx" SG_ 963 HomeSafeLtChime_B_Rq 1;
BA_ "U_UP375_MY15_Gas_Rx" SG_ 963 HomeSafeLtChime_B_Rq 1;
BA_ "U_UP375_MY15_Diesel_Rx" SG_ 963 HomeSafeLtChime_B_Rq 1;
BA_ "U_CD4_MY13_Diesel_Tx" SG_ 963 HomeSafeLtChime_B_Rq 1;
BA_ "U_CD4_MY13_Gas_Tx" SG_ 963 HomeSafeLtChime_B_Rq 1;
BA_ "U_CD4_MY13_Hev_Tx" SG_ 963 HomeSafeLtChime_B_Rq 1;
BA_ "U_CD4_MY13_Phev_Tx" SG_ 963 HomeSafeLtChime_B_Rq 1;
BA_ "U_CD42_MY14_Diesel_Tx" SG_ 963 HomeSafeLtChime_B_Rq 1;
BA_ "U_CD42_MY14_Gas_Tx" SG_ 963 HomeSafeLtChime_B_Rq 1;
BA_ "U_P552_MY15_Gas_Tx" SG_ 963 HomeSafeLtChime_B_Rq 1;
BA_ "U_S550_MY15_Gas_Tx" SG_ 963 HomeSafeLtChime_B_Rq 1;
BA_ "U_C489_MY14_Gas_Tx" SG_ 963 HomeSafeLtChime_B_Rq 1;
BA_ "U_U502_MY15_Gas_Tx" SG_ 963 HomeSafeLtChime_B_Rq 1;
BA_ "U_UP375_MY15_Gas_Tx" SG_ 963 HomeSafeLtChime_B_Rq 1;
BA_ "U_UP375_MY15_Diesel_Tx" SG_ 963 HomeSafeLtChime_B_Rq 1;
BA_ "U_CD43_MY16_Gas_Tx" SG_ 963 HomeSafeLtChime_B_Rq 1;
BA_ "U_CD4_MY14_Diesel_Tx" SG_ 963 HomeSafeLtChime_B_Rq 1;
BA_ "U_CD4_MY14_Gas_Tx" SG_ 963 HomeSafeLtChime_B_Rq 1;
BA_ "U_CD4_MY14_Hev_Tx" SG_ 963 HomeSafeLtChime_B_Rq 1;
BA_ "U_CD4_MY14_Phev_Tx" SG_ 963 HomeSafeLtChime_B_Rq 1;
BA_ "WakeupSignal" SG_ 963 StopLghtOn_B_Stat 1;
BA_ "CrossOver_InfoCAN" SG_ 963 StopLghtOn_B_Stat 1;
BA_ "CrossOver_LIN" SG_ 963 StopLghtOn_B_Stat 1;
BA_ "GenSigSendType" SG_ 963 StopLghtOn_B_Stat 3;
BA_ "U_CD4_MY13_Diesel_Rx" SG_ 963 StopLghtOn_B_Stat 1;
BA_ "U_CD4_MY13_Gas_Rx" SG_ 963 StopLghtOn_B_Stat 1;
BA_ "U_CD4_MY13_Hev_Rx" SG_ 963 StopLghtOn_B_Stat 1;
BA_ "U_CD4_MY13_Phev_Rx" SG_ 963 StopLghtOn_B_Stat 1;
BA_ "U_CD42_MY14_Diesel_Rx" SG_ 963 StopLghtOn_B_Stat 1;
BA_ "U_CD42_MY14_Gas_Rx" SG_ 963 StopLghtOn_B_Stat 1;
BA_ "U_P552_MY15_Gas_Rx" SG_ 963 StopLghtOn_B_Stat 1;
BA_ "U_S550_MY15_Gas_Rx" SG_ 963 StopLghtOn_B_Stat 1;
BA_ "U_C489_MY14_Gas_Rx" SG_ 963 StopLghtOn_B_Stat 1;
BA_ "U_U502_MY15_Gas_Rx" SG_ 963 StopLghtOn_B_Stat 1;
BA_ "U_B479_MY15_Gas_Rx" SG_ 963 StopLghtOn_B_Stat 1;
BA_ "U_UP375_MY15_Gas_Rx" SG_ 963 StopLghtOn_B_Stat 1;
BA_ "U_UP375_MY15_Diesel_Rx" SG_ 963 StopLghtOn_B_Stat 1;
BA_ "U_CD4_MY13_Diesel_Tx" SG_ 963 StopLghtOn_B_Stat 1;
BA_ "U_CD4_MY13_Gas_Tx" SG_ 963 StopLghtOn_B_Stat 1;
BA_ "U_CD4_MY13_Hev_Tx" SG_ 963 StopLghtOn_B_Stat 1;
BA_ "U_CD4_MY13_Phev_Tx" SG_ 963 StopLghtOn_B_Stat 1;
BA_ "U_CD42_MY14_Diesel_Tx" SG_ 963 StopLghtOn_B_Stat 1;
BA_ "U_CD42_MY14_Gas_Tx" SG_ 963 StopLghtOn_B_Stat 1;
BA_ "U_P552_MY15_Gas_Tx" SG_ 963 StopLghtOn_B_Stat 1;
BA_ "U_S550_MY15_Gas_Tx" SG_ 963 StopLghtOn_B_Stat 1;
BA_ "U_C489_MY14_Gas_Tx" SG_ 963 StopLghtOn_B_Stat 1;
BA_ "U_U502_MY15_Gas_Tx" SG_ 963 StopLghtOn_B_Stat 1;
BA_ "U_UP375_MY15_Gas_Tx" SG_ 963 StopLghtOn_B_Stat 1;
BA_ "U_UP375_MY15_Diesel_Tx" SG_ 963 StopLghtOn_B_Stat 1;
BA_ "U_CD43_MY16_Gas_Tx" SG_ 963 StopLghtOn_B_Stat 1;
BA_ "U_CD4_MY14_Diesel_Tx" SG_ 963 StopLghtOn_B_Stat 1;
BA_ "U_CD4_MY14_Gas_Tx" SG_ 963 StopLghtOn_B_Stat 1;
BA_ "U_CD4_MY14_Hev_Tx" SG_ 963 StopLghtOn_B_Stat 1;
BA_ "U_CD4_MY14_Phev_Tx" SG_ 963 StopLghtOn_B_Stat 1;
BA_ "CrossOver_InfoCAN" SG_ 963 RvrseLghtOn_B_Stat 1;
BA_ "CrossOver_LIN" SG_ 963 RvrseLghtOn_B_Stat 1;
BA_ "GenSigSendType" SG_ 963 RvrseLghtOn_B_Stat 3;
BA_ "U_CD4_MY13_Diesel_Tx" SG_ 963 RvrseLghtOn_B_Stat 1;
BA_ "U_CD4_MY13_Gas_Tx" SG_ 963 RvrseLghtOn_B_Stat 1;
BA_ "U_CD4_MY13_Hev_Tx" SG_ 963 RvrseLghtOn_B_Stat 1;
BA_ "U_CD4_MY13_Phev_Tx" SG_ 963 RvrseLghtOn_B_Stat 1;
BA_ "U_CD42_MY14_Diesel_Tx" SG_ 963 RvrseLghtOn_B_Stat 1;
BA_ "U_CD42_MY14_Gas_Tx" SG_ 963 RvrseLghtOn_B_Stat 1;
BA_ "U_P552_MY15_Gas_Tx" SG_ 963 RvrseLghtOn_B_Stat 1;
BA_ "U_S550_MY15_Gas_Tx" SG_ 963 RvrseLghtOn_B_Stat 1;
BA_ "U_C489_MY14_Gas_Tx" SG_ 963 RvrseLghtOn_B_Stat 1;
BA_ "U_U502_MY15_Gas_Tx" SG_ 963 RvrseLghtOn_B_Stat 1;
BA_ "U_UP375_MY15_Gas_Tx" SG_ 963 RvrseLghtOn_B_Stat 1;
BA_ "U_UP375_MY15_Diesel_Tx" SG_ 963 RvrseLghtOn_B_Stat 1;
BA_ "U_CD43_MY16_Gas_Tx" SG_ 963 RvrseLghtOn_B_Stat 1;
BA_ "U_CD4_MY14_Diesel_Tx" SG_ 963 RvrseLghtOn_B_Stat 1;
BA_ "U_CD4_MY14_Gas_Tx" SG_ 963 RvrseLghtOn_B_Stat 1;
BA_ "U_CD4_MY14_Hev_Tx" SG_ 963 RvrseLghtOn_B_Stat 1;
BA_ "U_CD4_MY14_Phev_Tx" SG_ 963 RvrseLghtOn_B_Stat 1;
BA_ "WakeupSignal" SG_ 963 PrkLght_D_Stat 1;
BA_ "CrossOver_InfoCAN" SG_ 963 PrkLght_D_Stat 1;
BA_ "GenSigSendType" SG_ 963 PrkLght_D_Stat 3;
BA_ "U_CD4_MY13_Diesel_Rx" SG_ 963 PrkLght_D_Stat 1;
BA_ "U_CD4_MY13_Gas_Rx" SG_ 963 PrkLght_D_Stat 1;
BA_ "U_CD4_MY13_Hev_Rx" SG_ 963 PrkLght_D_Stat 1;
BA_ "U_CD4_MY13_Phev_Rx" SG_ 963 PrkLght_D_Stat 1;
BA_ "U_CD42_MY14_Diesel_Rx" SG_ 963 PrkLght_D_Stat 1;
BA_ "U_CD42_MY14_Gas_Rx" SG_ 963 PrkLght_D_Stat 1;
BA_ "U_P552_MY15_Gas_Rx" SG_ 963 PrkLght_D_Stat 1;
BA_ "U_S550_MY15_Gas_Rx" SG_ 963 PrkLght_D_Stat 1;
BA_ "U_C489_MY14_Gas_Rx" SG_ 963 PrkLght_D_Stat 1;
BA_ "U_U502_MY15_Gas_Rx" SG_ 963 PrkLght_D_Stat 1;
BA_ "U_B479_MY15_Gas_Rx" SG_ 963 PrkLght_D_Stat 1;
BA_ "U_UP375_MY15_Gas_Rx" SG_ 963 PrkLght_D_Stat 1;
BA_ "U_UP375_MY15_Diesel_Rx" SG_ 963 PrkLght_D_Stat 1;
BA_ "U_CD4_MY13_Diesel_Tx" SG_ 963 PrkLght_D_Stat 1;
BA_ "U_CD4_MY13_Gas_Tx" SG_ 963 PrkLght_D_Stat 1;
BA_ "U_CD4_MY13_Hev_Tx" SG_ 963 PrkLght_D_Stat 1;
BA_ "U_CD4_MY13_Phev_Tx" SG_ 963 PrkLght_D_Stat 1;
BA_ "U_CD42_MY14_Diesel_Tx" SG_ 963 PrkLght_D_Stat 1;
BA_ "U_CD42_MY14_Gas_Tx" SG_ 963 PrkLght_D_Stat 1;
BA_ "U_P552_MY15_Gas_Tx" SG_ 963 PrkLght_D_Stat 1;
BA_ "U_S550_MY15_Gas_Tx" SG_ 963 PrkLght_D_Stat 1;
BA_ "U_C489_MY14_Gas_Tx" SG_ 963 PrkLght_D_Stat 1;
BA_ "U_U502_MY15_Gas_Tx" SG_ 963 PrkLght_D_Stat 1;
BA_ "U_UP375_MY15_Gas_Tx" SG_ 963 PrkLght_D_Stat 1;
BA_ "U_UP375_MY15_Diesel_Tx" SG_ 963 PrkLght_D_Stat 1;
BA_ "U_CD43_MY16_Gas_Tx" SG_ 963 PrkLght_D_Stat 1;
BA_ "U_CD4_MY14_Diesel_Tx" SG_ 963 PrkLght_D_Stat 1;
BA_ "U_CD4_MY14_Gas_Tx" SG_ 963 PrkLght_D_Stat 1;
BA_ "U_CD4_MY14_Hev_Tx" SG_ 963 PrkLght_D_Stat 1;
BA_ "U_CD4_MY14_Phev_Tx" SG_ 963 PrkLght_D_Stat 1;
BA_ "WakeupSignal" SG_ 963 HeadLghtSwtch_D_Stat 1;
BA_ "CrossOver_InfoCAN" SG_ 963 HeadLghtSwtch_D_Stat 1;
BA_ "GenSigStartValue" SG_ 963 HeadLghtSwtch_D_Stat 2;
BA_ "GenSigSendType" SG_ 963 HeadLghtSwtch_D_Stat 3;
BA_ "U_CD4_MY13_Diesel_Rx" SG_ 963 HeadLghtSwtch_D_Stat 1;
BA_ "U_CD4_MY13_Gas_Rx" SG_ 963 HeadLghtSwtch_D_Stat 1;
BA_ "U_CD4_MY13_Hev_Rx" SG_ 963 HeadLghtSwtch_D_Stat 1;
BA_ "U_CD4_MY13_Phev_Rx" SG_ 963 HeadLghtSwtch_D_Stat 1;
BA_ "U_CD42_MY14_Diesel_Rx" SG_ 963 HeadLghtSwtch_D_Stat 1;
BA_ "U_CD42_MY14_Gas_Rx" SG_ 963 HeadLghtSwtch_D_Stat 1;
BA_ "U_P552_MY15_Gas_Rx" SG_ 963 HeadLghtSwtch_D_Stat 1;
BA_ "U_S550_MY15_Gas_Rx" SG_ 963 HeadLghtSwtch_D_Stat 1;
BA_ "U_C489_MY14_Gas_Rx" SG_ 963 HeadLghtSwtch_D_Stat 1;
BA_ "U_U502_MY15_Gas_Rx" SG_ 963 HeadLghtSwtch_D_Stat 1;
BA_ "U_B479_MY15_Gas_Rx" SG_ 963 HeadLghtSwtch_D_Stat 1;
BA_ "U_UP375_MY15_Gas_Rx" SG_ 963 HeadLghtSwtch_D_Stat 1;
BA_ "U_UP375_MY15_Diesel_Rx" SG_ 963 HeadLghtSwtch_D_Stat 1;
BA_ "U_CD4_MY13_Diesel_Tx" SG_ 963 HeadLghtSwtch_D_Stat 1;
BA_ "U_CD4_MY13_Gas_Tx" SG_ 963 HeadLghtSwtch_D_Stat 1;
BA_ "U_CD4_MY13_Hev_Tx" SG_ 963 HeadLghtSwtch_D_Stat 1;
BA_ "U_CD4_MY13_Phev_Tx" SG_ 963 HeadLghtSwtch_D_Stat 1;
BA_ "U_CD42_MY14_Diesel_Tx" SG_ 963 HeadLghtSwtch_D_Stat 1;
BA_ "U_CD42_MY14_Gas_Tx" SG_ 963 HeadLghtSwtch_D_Stat 1;
BA_ "U_P552_MY15_Gas_Tx" SG_ 963 HeadLghtSwtch_D_Stat 1;
BA_ "U_S550_MY15_Gas_Tx" SG_ 963 HeadLghtSwtch_D_Stat 1;
BA_ "U_C489_MY14_Gas_Tx" SG_ 963 HeadLghtSwtch_D_Stat 1;
BA_ "U_U502_MY15_Gas_Tx" SG_ 963 HeadLghtSwtch_D_Stat 1;
BA_ "U_UP375_MY15_Gas_Tx" SG_ 963 HeadLghtSwtch_D_Stat 1;
BA_ "U_UP375_MY15_Diesel_Tx" SG_ 963 HeadLghtSwtch_D_Stat 1;
BA_ "U_CD43_MY16_Gas_Tx" SG_ 963 HeadLghtSwtch_D_Stat 1;
BA_ "U_CD4_MY14_Diesel_Tx" SG_ 963 HeadLghtSwtch_D_Stat 1;
BA_ "U_CD4_MY14_Gas_Tx" SG_ 963 HeadLghtSwtch_D_Stat 1;
BA_ "U_CD4_MY14_Hev_Tx" SG_ 963 HeadLghtSwtch_D_Stat 1;
BA_ "U_CD4_MY14_Phev_Tx" SG_ 963 HeadLghtSwtch_D_Stat 1;
BA_ "CrossOver_InfoCAN" SG_ 963 HeadLampLoFrOn_B_Stat 1;
BA_ "GenSigStartValue" SG_ 963 HeadLampLoFrOn_B_Stat 1;
BA_ "GenSigSendType" SG_ 963 HeadLampLoFrOn_B_Stat 3;
BA_ "U_CD4_MY13_Diesel_Tx" SG_ 963 HeadLampLoFrOn_B_Stat 1;
BA_ "U_CD4_MY13_Gas_Tx" SG_ 963 HeadLampLoFrOn_B_Stat 1;
BA_ "U_CD4_MY13_Hev_Tx" SG_ 963 HeadLampLoFrOn_B_Stat 1;
BA_ "U_CD4_MY13_Phev_Tx" SG_ 963 HeadLampLoFrOn_B_Stat 1;
BA_ "U_CD42_MY14_Diesel_Tx" SG_ 963 HeadLampLoFrOn_B_Stat 1;
BA_ "U_CD42_MY14_Gas_Tx" SG_ 963 HeadLampLoFrOn_B_Stat 1;
BA_ "U_P552_MY15_Gas_Tx" SG_ 963 HeadLampLoFrOn_B_Stat 1;
BA_ "U_S550_MY15_Gas_Tx" SG_ 963 HeadLampLoFrOn_B_Stat 1;
BA_ "U_C489_MY14_Gas_Tx" SG_ 963 HeadLampLoFrOn_B_Stat 1;
BA_ "U_U502_MY15_Gas_Tx" SG_ 963 HeadLampLoFrOn_B_Stat 1;
BA_ "U_UP375_MY15_Gas_Tx" SG_ 963 HeadLampLoFrOn_B_Stat 1;
BA_ "U_UP375_MY15_Diesel_Tx" SG_ 963 HeadLampLoFrOn_B_Stat 1;
BA_ "U_CD43_MY16_Gas_Tx" SG_ 963 HeadLampLoFrOn_B_Stat 1;
BA_ "U_CD4_MY14_Diesel_Tx" SG_ 963 HeadLampLoFrOn_B_Stat 1;
BA_ "U_CD4_MY14_Gas_Tx" SG_ 963 HeadLampLoFrOn_B_Stat 1;
BA_ "U_CD4_MY14_Hev_Tx" SG_ 963 HeadLampLoFrOn_B_Stat 1;
BA_ "U_CD4_MY14_Phev_Tx" SG_ 963 HeadLampLoFrOn_B_Stat 1;
BA_ "CrossOver_InfoCAN" SG_ 963 HeadLampLoFlOn_B_Stat 1;
BA_ "GenSigStartValue" SG_ 963 HeadLampLoFlOn_B_Stat 1;
BA_ "GenSigSendType" SG_ 963 HeadLampLoFlOn_B_Stat 3;
BA_ "U_CD4_MY13_Diesel_Tx" SG_ 963 HeadLampLoFlOn_B_Stat 1;
BA_ "U_CD4_MY13_Gas_Tx" SG_ 963 HeadLampLoFlOn_B_Stat 1;
BA_ "U_CD4_MY13_Hev_Tx" SG_ 963 HeadLampLoFlOn_B_Stat 1;
BA_ "U_CD4_MY13_Phev_Tx" SG_ 963 HeadLampLoFlOn_B_Stat 1;
BA_ "U_CD42_MY14_Diesel_Tx" SG_ 963 HeadLampLoFlOn_B_Stat 1;
BA_ "U_CD42_MY14_Gas_Tx" SG_ 963 HeadLampLoFlOn_B_Stat 1;
BA_ "U_P552_MY15_Gas_Tx" SG_ 963 HeadLampLoFlOn_B_Stat 1;
BA_ "U_S550_MY15_Gas_Tx" SG_ 963 HeadLampLoFlOn_B_Stat 1;
BA_ "U_C489_MY14_Gas_Tx" SG_ 963 HeadLampLoFlOn_B_Stat 1;
BA_ "U_U502_MY15_Gas_Tx" SG_ 963 HeadLampLoFlOn_B_Stat 1;
BA_ "U_UP375_MY15_Gas_Tx" SG_ 963 HeadLampLoFlOn_B_Stat 1;
BA_ "U_UP375_MY15_Diesel_Tx" SG_ 963 HeadLampLoFlOn_B_Stat 1;
BA_ "U_CD43_MY16_Gas_Tx" SG_ 963 HeadLampLoFlOn_B_Stat 1;
BA_ "U_CD4_MY14_Diesel_Tx" SG_ 963 HeadLampLoFlOn_B_Stat 1;
BA_ "U_CD4_MY14_Gas_Tx" SG_ 963 HeadLampLoFlOn_B_Stat 1;
BA_ "U_CD4_MY14_Hev_Tx" SG_ 963 HeadLampLoFlOn_B_Stat 1;
BA_ "U_CD4_MY14_Phev_Tx" SG_ 963 HeadLampLoFlOn_B_Stat 1;
BA_ "CrossOver_InfoCAN" SG_ 963 HeadLampLoActv_B_Stat 1;
BA_ "GenSigStartValue" SG_ 963 HeadLampLoActv_B_Stat 1;
BA_ "GenSigSendType" SG_ 963 HeadLampLoActv_B_Stat 3;
BA_ "U_CD4_MY13_Gas_Rx" SG_ 963 HeadLampLoActv_B_Stat 1;
BA_ "U_CD42_MY14_Gas_Rx" SG_ 963 HeadLampLoActv_B_Stat 1;
BA_ "U_P552_MY15_Gas_Rx" SG_ 963 HeadLampLoActv_B_Stat 1;
BA_ "U_U502_MY15_Gas_Rx" SG_ 963 HeadLampLoActv_B_Stat 1;
BA_ "U_CD43_MY16_Gas_Rx" SG_ 963 HeadLampLoActv_B_Stat 1;
BA_ "U_CD4_MY14_Gas_Rx" SG_ 963 HeadLampLoActv_B_Stat 1;
BA_ "U_CD4_MY13_Diesel_Tx" SG_ 963 HeadLampLoActv_B_Stat 1;
BA_ "U_CD4_MY13_Gas_Tx" SG_ 963 HeadLampLoActv_B_Stat 1;
BA_ "U_CD4_MY13_Hev_Tx" SG_ 963 HeadLampLoActv_B_Stat 1;
BA_ "U_CD4_MY13_Phev_Tx" SG_ 963 HeadLampLoActv_B_Stat 1;
BA_ "U_CD42_MY14_Diesel_Tx" SG_ 963 HeadLampLoActv_B_Stat 1;
BA_ "U_CD42_MY14_Gas_Tx" SG_ 963 HeadLampLoActv_B_Stat 1;
BA_ "U_P552_MY15_Gas_Tx" SG_ 963 HeadLampLoActv_B_Stat 1;
BA_ "U_S550_MY15_Gas_Tx" SG_ 963 HeadLampLoActv_B_Stat 1;
BA_ "U_C489_MY14_Gas_Tx" SG_ 963 HeadLampLoActv_B_Stat 1;
BA_ "U_U502_MY15_Gas_Tx" SG_ 963 HeadLampLoActv_B_Stat 1;
BA_ "U_UP375_MY15_Gas_Tx" SG_ 963 HeadLampLoActv_B_Stat 1;
BA_ "U_UP375_MY15_Diesel_Tx" SG_ 963 HeadLampLoActv_B_Stat 1;
BA_ "U_CD43_MY16_Gas_Tx" SG_ 963 HeadLampLoActv_B_Stat 1;
BA_ "U_CD4_MY14_Diesel_Tx" SG_ 963 HeadLampLoActv_B_Stat 1;
BA_ "U_CD4_MY14_Gas_Tx" SG_ 963 HeadLampLoActv_B_Stat 1;
BA_ "U_CD4_MY14_Hev_Tx" SG_ 963 HeadLampLoActv_B_Stat 1;
BA_ "U_CD4_MY14_Phev_Tx" SG_ 963 HeadLampLoActv_B_Stat 1;
BA_ "WakeupSignal" SG_ 963 Headlamp_On_Wrning_Cmd 1;
BA_ "CrossOver_InfoCAN" SG_ 963 Headlamp_On_Wrning_Cmd 1;
BA_ "GenSigSendType" SG_ 963 Headlamp_On_Wrning_Cmd 3;
BA_ "U_CD4_MY13_Diesel_Rx" SG_ 963 Headlamp_On_Wrning_Cmd 1;
BA_ "U_CD4_MY13_Gas_Rx" SG_ 963 Headlamp_On_Wrning_Cmd 1;
BA_ "U_CD4_MY13_Hev_Rx" SG_ 963 Headlamp_On_Wrning_Cmd 1;
BA_ "U_CD4_MY13_Phev_Rx" SG_ 963 Headlamp_On_Wrning_Cmd 1;
BA_ "U_CD42_MY14_Diesel_Rx" SG_ 963 Headlamp_On_Wrning_Cmd 1;
BA_ "U_CD42_MY14_Gas_Rx" SG_ 963 Headlamp_On_Wrning_Cmd 1;
BA_ "U_P552_MY15_Gas_Rx" SG_ 963 Headlamp_On_Wrning_Cmd 1;
BA_ "U_S550_MY15_Gas_Rx" SG_ 963 Headlamp_On_Wrning_Cmd 1;
BA_ "U_C489_MY14_Gas_Rx" SG_ 963 Headlamp_On_Wrning_Cmd 1;
BA_ "U_U502_MY15_Gas_Rx" SG_ 963 Headlamp_On_Wrning_Cmd 1;
BA_ "U_B479_MY15_Gas_Rx" SG_ 963 Headlamp_On_Wrning_Cmd 1;
BA_ "U_UP375_MY15_Gas_Rx" SG_ 963 Headlamp_On_Wrning_Cmd 1;
BA_ "U_UP375_MY15_Diesel_Rx" SG_ 963 Headlamp_On_Wrning_Cmd 1;
BA_ "U_CD4_MY13_Diesel_Tx" SG_ 963 Headlamp_On_Wrning_Cmd 1;
BA_ "U_CD4_MY13_Gas_Tx" SG_ 963 Headlamp_On_Wrning_Cmd 1;
BA_ "U_CD4_MY13_Hev_Tx" SG_ 963 Headlamp_On_Wrning_Cmd 1;
BA_ "U_CD4_MY13_Phev_Tx" SG_ 963 Headlamp_On_Wrning_Cmd 1;
BA_ "U_CD42_MY14_Diesel_Tx" SG_ 963 Headlamp_On_Wrning_Cmd 1;
BA_ "U_CD42_MY14_Gas_Tx" SG_ 963 Headlamp_On_Wrning_Cmd 1;
BA_ "U_P552_MY15_Gas_Tx" SG_ 963 Headlamp_On_Wrning_Cmd 1;
BA_ "U_S550_MY15_Gas_Tx" SG_ 963 Headlamp_On_Wrning_Cmd 1;
BA_ "U_C489_MY14_Gas_Tx" SG_ 963 Headlamp_On_Wrning_Cmd 1;
BA_ "U_U502_MY15_Gas_Tx" SG_ 963 Headlamp_On_Wrning_Cmd 1;
BA_ "U_UP375_MY15_Gas_Tx" SG_ 963 Headlamp_On_Wrning_Cmd 1;
BA_ "U_UP375_MY15_Diesel_Tx" SG_ 963 Headlamp_On_Wrning_Cmd 1;
BA_ "U_CD43_MY16_Gas_Tx" SG_ 963 Headlamp_On_Wrning_Cmd 1;
BA_ "U_CD4_MY14_Diesel_Tx" SG_ 963 Headlamp_On_Wrning_Cmd 1;
BA_ "U_CD4_MY14_Gas_Tx" SG_ 963 Headlamp_On_Wrning_Cmd 1;
BA_ "U_CD4_MY14_Hev_Tx" SG_ 963 Headlamp_On_Wrning_Cmd 1;
BA_ "U_CD4_MY14_Phev_Tx" SG_ 963 Headlamp_On_Wrning_Cmd 1;
BA_ "CrossOver_InfoCAN" SG_ 963 Park_Brake_Chime_Rqst 1;
BA_ "GenSigSendType" SG_ 963 Park_Brake_Chime_Rqst 3;
BA_ "U_CD4_MY13_Diesel_Tx" SG_ 963 Park_Brake_Chime_Rqst 1;
BA_ "U_CD4_MY13_Gas_Tx" SG_ 963 Park_Brake_Chime_Rqst 1;
BA_ "U_CD4_MY13_Hev_Tx" SG_ 963 Park_Brake_Chime_Rqst 1;
BA_ "U_CD4_MY13_Phev_Tx" SG_ 963 Park_Brake_Chime_Rqst 1;
BA_ "U_CD42_MY14_Diesel_Tx" SG_ 963 Park_Brake_Chime_Rqst 1;
BA_ "U_CD42_MY14_Gas_Tx" SG_ 963 Park_Brake_Chime_Rqst 1;
BA_ "U_P552_MY15_Gas_Tx" SG_ 963 Park_Brake_Chime_Rqst 1;
BA_ "U_S550_MY15_Gas_Tx" SG_ 963 Park_Brake_Chime_Rqst 1;
BA_ "U_C489_MY14_Gas_Tx" SG_ 963 Park_Brake_Chime_Rqst 1;
BA_ "U_U502_MY15_Gas_Tx" SG_ 963 Park_Brake_Chime_Rqst 1;
BA_ "U_UP375_MY15_Gas_Tx" SG_ 963 Park_Brake_Chime_Rqst 1;
BA_ "U_UP375_MY15_Diesel_Tx" SG_ 963 Park_Brake_Chime_Rqst 1;
BA_ "U_CD43_MY16_Gas_Tx" SG_ 963 Park_Brake_Chime_Rqst 1;
BA_ "U_CD4_MY14_Diesel_Tx" SG_ 963 Park_Brake_Chime_Rqst 1;
BA_ "U_CD4_MY14_Gas_Tx" SG_ 963 Park_Brake_Chime_Rqst 1;
BA_ "U_CD4_MY14_Hev_Tx" SG_ 963 Park_Brake_Chime_Rqst 1;
BA_ "U_CD4_MY14_Phev_Tx" SG_ 963 Park_Brake_Chime_Rqst 1;
BA_ "WakeupSignal" SG_ 963 HeadLghtHiOn_B_Stat 1;
BA_ "CrossOver_InfoCAN" SG_ 963 HeadLghtHiOn_B_Stat 1;
BA_ "GenSigSendType" SG_ 963 HeadLghtHiOn_B_Stat 3;
BA_ "U_CD4_MY13_Gas_Rx" SG_ 963 HeadLghtHiOn_B_Stat 1;
BA_ "U_CD42_MY14_Gas_Rx" SG_ 963 HeadLghtHiOn_B_Stat 1;
BA_ "U_P552_MY15_Gas_Rx" SG_ 963 HeadLghtHiOn_B_Stat 1;
BA_ "U_C489_MY14_Gas_Rx" SG_ 963 HeadLghtHiOn_B_Stat 1;
BA_ "U_U502_MY15_Gas_Rx" SG_ 963 HeadLghtHiOn_B_Stat 1;
BA_ "U_B479_MY15_Gas_Rx" SG_ 963 HeadLghtHiOn_B_Stat 1;
BA_ "U_UP375_MY15_Gas_Rx" SG_ 963 HeadLghtHiOn_B_Stat 1;
BA_ "U_UP375_MY15_Diesel_Rx" SG_ 963 HeadLghtHiOn_B_Stat 1;
BA_ "U_CD43_MY16_Gas_Rx" SG_ 963 HeadLghtHiOn_B_Stat 1;
BA_ "U_CD4_MY14_Gas_Rx" SG_ 963 HeadLghtHiOn_B_Stat 1;
BA_ "U_CD4_MY13_Diesel_Tx" SG_ 963 HeadLghtHiOn_B_Stat 1;
BA_ "U_CD4_MY13_Gas_Tx" SG_ 963 HeadLghtHiOn_B_Stat 1;
BA_ "U_CD4_MY13_Hev_Tx" SG_ 963 HeadLghtHiOn_B_Stat 1;
BA_ "U_CD4_MY13_Phev_Tx" SG_ 963 HeadLghtHiOn_B_Stat 1;
BA_ "U_CD42_MY14_Diesel_Tx" SG_ 963 HeadLghtHiOn_B_Stat 1;
BA_ "U_CD42_MY14_Gas_Tx" SG_ 963 HeadLghtHiOn_B_Stat 1;
BA_ "U_P552_MY15_Gas_Tx" SG_ 963 HeadLghtHiOn_B_Stat 1;
BA_ "U_S550_MY15_Gas_Tx" SG_ 963 HeadLghtHiOn_B_Stat 1;
BA_ "U_C489_MY14_Gas_Tx" SG_ 963 HeadLghtHiOn_B_Stat 1;
BA_ "U_U502_MY15_Gas_Tx" SG_ 963 HeadLghtHiOn_B_Stat 1;
BA_ "U_UP375_MY15_Gas_Tx" SG_ 963 HeadLghtHiOn_B_Stat 1;
BA_ "U_UP375_MY15_Diesel_Tx" SG_ 963 HeadLghtHiOn_B_Stat 1;
BA_ "U_CD43_MY16_Gas_Tx" SG_ 963 HeadLghtHiOn_B_Stat 1;
BA_ "U_CD4_MY14_Diesel_Tx" SG_ 963 HeadLghtHiOn_B_Stat 1;
BA_ "U_CD4_MY14_Gas_Tx" SG_ 963 HeadLghtHiOn_B_Stat 1;
BA_ "U_CD4_MY14_Hev_Tx" SG_ 963 HeadLghtHiOn_B_Stat 1;
BA_ "U_CD4_MY14_Phev_Tx" SG_ 963 HeadLghtHiOn_B_Stat 1;
BA_ "WakeupSignal" SG_ 963 BrkWarnInd_B_Rq 1;
BA_ "CrossOver_InfoCAN" SG_ 963 BrkWarnInd_B_Rq 1;
BA_ "GenSigSendType" SG_ 963 BrkWarnInd_B_Rq 3;
BA_ "U_CD4_MY13_Diesel_Rx" SG_ 963 BrkWarnInd_B_Rq 1;
BA_ "U_CD4_MY13_Gas_Rx" SG_ 963 BrkWarnInd_B_Rq 1;
BA_ "U_CD4_MY13_Hev_Rx" SG_ 963 BrkWarnInd_B_Rq 1;
BA_ "U_CD4_MY13_Phev_Rx" SG_ 963 BrkWarnInd_B_Rq 1;
BA_ "U_CD42_MY14_Diesel_Rx" SG_ 963 BrkWarnInd_B_Rq 1;
BA_ "U_CD42_MY14_Gas_Rx" SG_ 963 BrkWarnInd_B_Rq 1;
BA_ "U_P552_MY15_Gas_Rx" SG_ 963 BrkWarnInd_B_Rq 1;
BA_ "U_S550_MY15_Gas_Rx" SG_ 963 BrkWarnInd_B_Rq 1;
BA_ "U_C489_MY14_Gas_Rx" SG_ 963 BrkWarnInd_B_Rq 1;
BA_ "U_U502_MY15_Gas_Rx" SG_ 963 BrkWarnInd_B_Rq 1;
BA_ "U_B479_MY15_Gas_Rx" SG_ 963 BrkWarnInd_B_Rq 1;
BA_ "U_UP375_MY15_Gas_Rx" SG_ 963 BrkWarnInd_B_Rq 1;
BA_ "U_UP375_MY15_Diesel_Rx" SG_ 963 BrkWarnInd_B_Rq 1;
BA_ "U_CD4_MY13_Diesel_Tx" SG_ 963 BrkWarnInd_B_Rq 1;
BA_ "U_CD4_MY13_Gas_Tx" SG_ 963 BrkWarnInd_B_Rq 1;
BA_ "U_CD4_MY13_Hev_Tx" SG_ 963 BrkWarnInd_B_Rq 1;
BA_ "U_CD4_MY13_Phev_Tx" SG_ 963 BrkWarnInd_B_Rq 1;
BA_ "U_CD42_MY14_Diesel_Tx" SG_ 963 BrkWarnInd_B_Rq 1;
BA_ "U_CD42_MY14_Gas_Tx" SG_ 963 BrkWarnInd_B_Rq 1;
BA_ "U_P552_MY15_Gas_Tx" SG_ 963 BrkWarnInd_B_Rq 1;
BA_ "U_S550_MY15_Gas_Tx" SG_ 963 BrkWarnInd_B_Rq 1;
BA_ "U_C489_MY14_Gas_Tx" SG_ 963 BrkWarnInd_B_Rq 1;
BA_ "U_U502_MY15_Gas_Tx" SG_ 963 BrkWarnInd_B_Rq 1;
BA_ "U_UP375_MY15_Gas_Tx" SG_ 963 BrkWarnInd_B_Rq 1;
BA_ "U_UP375_MY15_Diesel_Tx" SG_ 963 BrkWarnInd_B_Rq 1;
BA_ "U_CD43_MY16_Gas_Tx" SG_ 963 BrkWarnInd_B_Rq 1;
BA_ "U_CD4_MY14_Diesel_Tx" SG_ 963 BrkWarnInd_B_Rq 1;
BA_ "U_CD4_MY14_Gas_Tx" SG_ 963 BrkWarnInd_B_Rq 1;
BA_ "U_CD4_MY14_Hev_Tx" SG_ 963 BrkWarnInd_B_Rq 1;
BA_ "U_CD4_MY14_Phev_Tx" SG_ 963 BrkWarnInd_B_Rq 1;
BA_ "CrossOver_InfoCAN" SG_ 963 Brk_Fluid_Lvl_Low 1;
BA_ "GenSigSendType" SG_ 963 Brk_Fluid_Lvl_Low 3;
BA_ "U_CD4_MY13_Diesel_Tx" SG_ 963 Brk_Fluid_Lvl_Low 1;
BA_ "U_CD4_MY13_Gas_Tx" SG_ 963 Brk_Fluid_Lvl_Low 1;
BA_ "U_CD4_MY13_Hev_Tx" SG_ 963 Brk_Fluid_Lvl_Low 1;
BA_ "U_CD4_MY13_Phev_Tx" SG_ 963 Brk_Fluid_Lvl_Low 1;
BA_ "U_CD42_MY14_Diesel_Tx" SG_ 963 Brk_Fluid_Lvl_Low 1;
BA_ "U_CD42_MY14_Gas_Tx" SG_ 963 Brk_Fluid_Lvl_Low 1;
BA_ "U_P552_MY15_Gas_Tx" SG_ 963 Brk_Fluid_Lvl_Low 1;
BA_ "U_S550_MY15_Gas_Tx" SG_ 963 Brk_Fluid_Lvl_Low 1;
BA_ "U_C489_MY14_Gas_Tx" SG_ 963 Brk_Fluid_Lvl_Low 1;
BA_ "U_U502_MY15_Gas_Tx" SG_ 963 Brk_Fluid_Lvl_Low 1;
BA_ "U_UP375_MY15_Gas_Tx" SG_ 963 Brk_Fluid_Lvl_Low 1;
BA_ "U_UP375_MY15_Diesel_Tx" SG_ 963 Brk_Fluid_Lvl_Low 1;
BA_ "U_CD43_MY16_Gas_Tx" SG_ 963 Brk_Fluid_Lvl_Low 1;
BA_ "U_CD4_MY14_Diesel_Tx" SG_ 963 Brk_Fluid_Lvl_Low 1;
BA_ "U_CD4_MY14_Gas_Tx" SG_ 963 Brk_Fluid_Lvl_Low 1;
BA_ "U_CD4_MY14_Hev_Tx" SG_ 963 Brk_Fluid_Lvl_Low 1;
BA_ "U_CD4_MY14_Phev_Tx" SG_ 963 Brk_Fluid_Lvl_Low 1;
BA_ "CrossOver_InfoCAN" SG_ 963 ReducedGuard_D_Stat 1;
BA_ "GenSigSendType" SG_ 963 ReducedGuard_D_Stat 3;
BA_ "U_CD4_MY13_Diesel_Tx" SG_ 963 ReducedGuard_D_Stat 1;
BA_ "U_CD4_MY13_Gas_Tx" SG_ 963 ReducedGuard_D_Stat 1;
BA_ "U_CD4_MY13_Hev_Tx" SG_ 963 ReducedGuard_D_Stat 1;
BA_ "U_CD4_MY13_Phev_Tx" SG_ 963 ReducedGuard_D_Stat 1;
BA_ "U_CD42_MY14_Diesel_Tx" SG_ 963 ReducedGuard_D_Stat 1;
BA_ "U_CD42_MY14_Gas_Tx" SG_ 963 ReducedGuard_D_Stat 1;
BA_ "U_P552_MY15_Gas_Tx" SG_ 963 ReducedGuard_D_Stat 1;
BA_ "U_S550_MY15_Gas_Tx" SG_ 963 ReducedGuard_D_Stat 1;
BA_ "U_C489_MY14_Gas_Tx" SG_ 963 ReducedGuard_D_Stat 1;
BA_ "U_U502_MY15_Gas_Tx" SG_ 963 ReducedGuard_D_Stat 1;
BA_ "U_UP375_MY15_Gas_Tx" SG_ 963 ReducedGuard_D_Stat 1;
BA_ "U_UP375_MY15_Diesel_Tx" SG_ 963 ReducedGuard_D_Stat 1;
BA_ "U_CD43_MY16_Gas_Tx" SG_ 963 ReducedGuard_D_Stat 1;
BA_ "U_CD4_MY14_Diesel_Tx" SG_ 963 ReducedGuard_D_Stat 1;
BA_ "U_CD4_MY14_Gas_Tx" SG_ 963 ReducedGuard_D_Stat 1;
BA_ "U_CD4_MY14_Hev_Tx" SG_ 963 ReducedGuard_D_Stat 1;
BA_ "U_CD4_MY14_Phev_Tx" SG_ 963 ReducedGuard_D_Stat 1;
BA_ "WakeupSignal" SG_ 963 Perimeter_Alarm_Status 1;
BA_ "CrossOver_InfoCAN" SG_ 963 Perimeter_Alarm_Status 1;
BA_ "GenSigSendType" SG_ 963 Perimeter_Alarm_Status 3;
BA_ "U_CD4_MY13_Diesel_Tx" SG_ 963 Perimeter_Alarm_Status 1;
BA_ "U_CD4_MY13_Gas_Tx" SG_ 963 Perimeter_Alarm_Status 1;
BA_ "U_CD4_MY13_Hev_Tx" SG_ 963 Perimeter_Alarm_Status 1;
BA_ "U_CD4_MY13_Phev_Tx" SG_ 963 Perimeter_Alarm_Status 1;
BA_ "U_CD42_MY14_Diesel_Tx" SG_ 963 Perimeter_Alarm_Status 1;
BA_ "U_CD42_MY14_Gas_Tx" SG_ 963 Perimeter_Alarm_Status 1;
BA_ "U_P552_MY15_Gas_Tx" SG_ 963 Perimeter_Alarm_Status 1;
BA_ "U_S550_MY15_Gas_Tx" SG_ 963 Perimeter_Alarm_Status 1;
BA_ "U_C489_MY14_Gas_Tx" SG_ 963 Perimeter_Alarm_Status 1;
BA_ "U_U502_MY15_Gas_Tx" SG_ 963 Perimeter_Alarm_Status 1;
BA_ "U_UP375_MY15_Gas_Tx" SG_ 963 Perimeter_Alarm_Status 1;
BA_ "U_UP375_MY15_Diesel_Tx" SG_ 963 Perimeter_Alarm_Status 1;
BA_ "U_CD43_MY16_Gas_Tx" SG_ 963 Perimeter_Alarm_Status 1;
BA_ "U_CD4_MY14_Diesel_Tx" SG_ 963 Perimeter_Alarm_Status 1;
BA_ "U_CD4_MY14_Gas_Tx" SG_ 963 Perimeter_Alarm_Status 1;
BA_ "U_CD4_MY14_Hev_Tx" SG_ 963 Perimeter_Alarm_Status 1;
BA_ "U_CD4_MY14_Phev_Tx" SG_ 963 Perimeter_Alarm_Status 1;
BA_ "WakeupSignal" SG_ 963 Courtesy_BSave_Stat 1;
BA_ "CrossOver_InfoCAN" SG_ 963 Courtesy_BSave_Stat 1;
BA_ "GenSigStartValue" SG_ 963 Courtesy_BSave_Stat 1;
BA_ "GenSigSendType" SG_ 963 Courtesy_BSave_Stat 3;
BA_ "U_CD4_MY13_Diesel_Tx" SG_ 963 Courtesy_BSave_Stat 1;
BA_ "U_CD4_MY13_Gas_Tx" SG_ 963 Courtesy_BSave_Stat 1;
BA_ "U_CD4_MY13_Hev_Tx" SG_ 963 Courtesy_BSave_Stat 1;
BA_ "U_CD4_MY13_Phev_Tx" SG_ 963 Courtesy_BSave_Stat 1;
BA_ "U_CD42_MY14_Diesel_Tx" SG_ 963 Courtesy_BSave_Stat 1;
BA_ "U_CD42_MY14_Gas_Tx" SG_ 963 Courtesy_BSave_Stat 1;
BA_ "U_P552_MY15_Gas_Tx" SG_ 963 Courtesy_BSave_Stat 1;
BA_ "U_S550_MY15_Gas_Tx" SG_ 963 Courtesy_BSave_Stat 1;
BA_ "U_C489_MY14_Gas_Tx" SG_ 963 Courtesy_BSave_Stat 1;
BA_ "U_U502_MY15_Gas_Tx" SG_ 963 Courtesy_BSave_Stat 1;
BA_ "U_UP375_MY15_Gas_Tx" SG_ 963 Courtesy_BSave_Stat 1;
BA_ "U_UP375_MY15_Diesel_Tx" SG_ 963 Courtesy_BSave_Stat 1;
BA_ "U_CD43_MY16_Gas_Tx" SG_ 963 Courtesy_BSave_Stat 1;
BA_ "U_CD4_MY14_Diesel_Tx" SG_ 963 Courtesy_BSave_Stat 1;
BA_ "U_CD4_MY14_Gas_Tx" SG_ 963 Courtesy_BSave_Stat 1;
BA_ "U_CD4_MY14_Hev_Tx" SG_ 963 Courtesy_BSave_Stat 1;
BA_ "U_CD4_MY14_Phev_Tx" SG_ 963 Courtesy_BSave_Stat 1;
BA_ "WakeupSignal" SG_ 963 WndwGlbl_D_Cmd 1;
BA_ "CrossOver_InfoCAN" SG_ 963 WndwGlbl_D_Cmd 1;
BA_ "GenSigSendType" SG_ 963 WndwGlbl_D_Cmd 3;
BA_ "U_CD4_MY13_Diesel_Rx" SG_ 963 WndwGlbl_D_Cmd 1;
BA_ "U_CD4_MY13_Gas_Rx" SG_ 963 WndwGlbl_D_Cmd 1;
BA_ "U_CD4_MY13_Hev_Rx" SG_ 963 WndwGlbl_D_Cmd 1;
BA_ "U_CD4_MY13_Phev_Rx" SG_ 963 WndwGlbl_D_Cmd 1;
BA_ "U_CD42_MY14_Diesel_Rx" SG_ 963 WndwGlbl_D_Cmd 1;
BA_ "U_CD42_MY14_Gas_Rx" SG_ 963 WndwGlbl_D_Cmd 1;
BA_ "U_P552_MY15_Gas_Rx" SG_ 963 WndwGlbl_D_Cmd 1;
BA_ "U_S550_MY15_Gas_Rx" SG_ 963 WndwGlbl_D_Cmd 1;
BA_ "U_C489_MY14_Gas_Rx" SG_ 963 WndwGlbl_D_Cmd 1;
BA_ "U_U502_MY15_Gas_Rx" SG_ 963 WndwGlbl_D_Cmd 1;
BA_ "U_B479_MY15_Gas_Rx" SG_ 963 WndwGlbl_D_Cmd 1;
BA_ "U_UP375_MY15_Gas_Rx" SG_ 963 WndwGlbl_D_Cmd 1;
BA_ "U_UP375_MY15_Diesel_Rx" SG_ 963 WndwGlbl_D_Cmd 1;
BA_ "U_CD4_MY13_Diesel_Tx" SG_ 963 WndwGlbl_D_Cmd 1;
BA_ "U_CD4_MY13_Gas_Tx" SG_ 963 WndwGlbl_D_Cmd 1;
BA_ "U_CD4_MY13_Hev_Tx" SG_ 963 WndwGlbl_D_Cmd 1;
BA_ "U_CD4_MY13_Phev_Tx" SG_ 963 WndwGlbl_D_Cmd 1;
BA_ "U_CD42_MY14_Diesel_Tx" SG_ 963 WndwGlbl_D_Cmd 1;
BA_ "U_CD42_MY14_Gas_Tx" SG_ 963 WndwGlbl_D_Cmd 1;
BA_ "U_P552_MY15_Gas_Tx" SG_ 963 WndwGlbl_D_Cmd 1;
BA_ "U_S550_MY15_Gas_Tx" SG_ 963 WndwGlbl_D_Cmd 1;
BA_ "U_C489_MY14_Gas_Tx" SG_ 963 WndwGlbl_D_Cmd 1;
BA_ "U_U502_MY15_Gas_Tx" SG_ 963 WndwGlbl_D_Cmd 1;
BA_ "U_UP375_MY15_Gas_Tx" SG_ 963 WndwGlbl_D_Cmd 1;
BA_ "U_UP375_MY15_Diesel_Tx" SG_ 963 WndwGlbl_D_Cmd 1;
BA_ "U_CD43_MY16_Gas_Tx" SG_ 963 WndwGlbl_D_Cmd 1;
BA_ "U_CD4_MY14_Diesel_Tx" SG_ 963 WndwGlbl_D_Cmd 1;
BA_ "U_CD4_MY14_Gas_Tx" SG_ 963 WndwGlbl_D_Cmd 1;
BA_ "U_CD4_MY14_Hev_Tx" SG_ 963 WndwGlbl_D_Cmd 1;
BA_ "U_CD4_MY14_Phev_Tx" SG_ 963 WndwGlbl_D_Cmd 1;
BA_ "WakeupSignal" SG_ 963 PudLamp_D_Rq 1;
BA_ "CrossOver_InfoCAN" SG_ 963 PudLamp_D_Rq 1;
BA_ "GenSigSendType" SG_ 963 PudLamp_D_Rq 3;
BA_ "U_CD4_MY13_Diesel_Rx" SG_ 963 PudLamp_D_Rq 1;
BA_ "U_CD4_MY13_Gas_Rx" SG_ 963 PudLamp_D_Rq 1;
BA_ "U_CD4_MY13_Hev_Rx" SG_ 963 PudLamp_D_Rq 1;
BA_ "U_CD4_MY13_Phev_Rx" SG_ 963 PudLamp_D_Rq 1;
BA_ "U_CD42_MY14_Diesel_Rx" SG_ 963 PudLamp_D_Rq 1;
BA_ "U_CD42_MY14_Gas_Rx" SG_ 963 PudLamp_D_Rq 1;
BA_ "U_P552_MY15_Gas_Rx" SG_ 963 PudLamp_D_Rq 1;
BA_ "U_S550_MY15_Gas_Rx" SG_ 963 PudLamp_D_Rq 1;
BA_ "U_C489_MY14_Gas_Rx" SG_ 963 PudLamp_D_Rq 1;
BA_ "U_U502_MY15_Gas_Rx" SG_ 963 PudLamp_D_Rq 1;
BA_ "U_B479_MY15_Gas_Rx" SG_ 963 PudLamp_D_Rq 1;
BA_ "U_UP375_MY15_Gas_Rx" SG_ 963 PudLamp_D_Rq 1;
BA_ "U_UP375_MY15_Diesel_Rx" SG_ 963 PudLamp_D_Rq 1;
BA_ "U_CD4_MY13_Diesel_Tx" SG_ 963 PudLamp_D_Rq 1;
BA_ "U_CD4_MY13_Gas_Tx" SG_ 963 PudLamp_D_Rq 1;
BA_ "U_CD4_MY13_Hev_Tx" SG_ 963 PudLamp_D_Rq 1;
BA_ "U_CD4_MY13_Phev_Tx" SG_ 963 PudLamp_D_Rq 1;
BA_ "U_CD42_MY14_Diesel_Tx" SG_ 963 PudLamp_D_Rq 1;
BA_ "U_CD42_MY14_Gas_Tx" SG_ 963 PudLamp_D_Rq 1;
BA_ "U_P552_MY15_Gas_Tx" SG_ 963 PudLamp_D_Rq 1;
BA_ "U_S550_MY15_Gas_Tx" SG_ 963 PudLamp_D_Rq 1;
BA_ "U_C489_MY14_Gas_Tx" SG_ 963 PudLamp_D_Rq 1;
BA_ "U_U502_MY15_Gas_Tx" SG_ 963 PudLamp_D_Rq 1;
BA_ "U_UP375_MY15_Gas_Tx" SG_ 963 PudLamp_D_Rq 1;
BA_ "U_UP375_MY15_Diesel_Tx" SG_ 963 PudLamp_D_Rq 1;
BA_ "U_CD43_MY16_Gas_Tx" SG_ 963 PudLamp_D_Rq 1;
BA_ "U_CD4_MY14_Diesel_Tx" SG_ 963 PudLamp_D_Rq 1;
BA_ "U_CD4_MY14_Gas_Tx" SG_ 963 PudLamp_D_Rq 1;
BA_ "U_CD4_MY14_Hev_Tx" SG_ 963 PudLamp_D_Rq 1;
BA_ "U_CD4_MY14_Phev_Tx" SG_ 963 PudLamp_D_Rq 1;
BA_ "CrossOver_InfoCAN" SG_ 963 DayRnngLampOn_B_Stat 1;
BA_ "GenSigSendType" SG_ 963 DayRnngLampOn_B_Stat 3;
BA_ "U_CD4_MY13_Diesel_Tx" SG_ 963 DayRnngLampOn_B_Stat 1;
BA_ "U_CD4_MY13_Gas_Tx" SG_ 963 DayRnngLampOn_B_Stat 1;
BA_ "U_CD4_MY13_Hev_Tx" SG_ 963 DayRnngLampOn_B_Stat 1;
BA_ "U_CD4_MY13_Phev_Tx" SG_ 963 DayRnngLampOn_B_Stat 1;
BA_ "U_CD42_MY14_Diesel_Tx" SG_ 963 DayRnngLampOn_B_Stat 1;
BA_ "U_CD42_MY14_Gas_Tx" SG_ 963 DayRnngLampOn_B_Stat 1;
BA_ "U_P552_MY15_Gas_Tx" SG_ 963 DayRnngLampOn_B_Stat 1;
BA_ "U_S550_MY15_Gas_Tx" SG_ 963 DayRnngLampOn_B_Stat 1;
BA_ "U_C489_MY14_Gas_Tx" SG_ 963 DayRnngLampOn_B_Stat 1;
BA_ "U_U502_MY15_Gas_Tx" SG_ 963 DayRnngLampOn_B_Stat 1;
BA_ "U_UP375_MY15_Gas_Tx" SG_ 963 DayRnngLampOn_B_Stat 1;
BA_ "U_UP375_MY15_Diesel_Tx" SG_ 963 DayRnngLampOn_B_Stat 1;
BA_ "U_CD43_MY16_Gas_Tx" SG_ 963 DayRnngLampOn_B_Stat 1;
BA_ "U_CD4_MY14_Diesel_Tx" SG_ 963 DayRnngLampOn_B_Stat 1;
BA_ "U_CD4_MY14_Gas_Tx" SG_ 963 DayRnngLampOn_B_Stat 1;
BA_ "U_CD4_MY14_Hev_Tx" SG_ 963 DayRnngLampOn_B_Stat 1;
BA_ "U_CD4_MY14_Phev_Tx" SG_ 963 DayRnngLampOn_B_Stat 1;
BA_ "WakeupSignal" SG_ 963 PerimeterAlarmChimeRq 1;
BA_ "CrossOver_InfoCAN" SG_ 963 PerimeterAlarmChimeRq 1;
BA_ "GenSigSendType" SG_ 963 PerimeterAlarmChimeRq 3;
BA_ "U_CD4_MY13_Diesel_Rx" SG_ 963 PerimeterAlarmChimeRq 1;
BA_ "U_CD4_MY13_Gas_Rx" SG_ 963 PerimeterAlarmChimeRq 1;
BA_ "U_CD4_MY13_Hev_Rx" SG_ 963 PerimeterAlarmChimeRq 1;
BA_ "U_CD4_MY13_Phev_Rx" SG_ 963 PerimeterAlarmChimeRq 1;
BA_ "U_CD42_MY14_Diesel_Rx" SG_ 963 PerimeterAlarmChimeRq 1;
BA_ "U_CD42_MY14_Gas_Rx" SG_ 963 PerimeterAlarmChimeRq 1;
BA_ "U_P552_MY15_Gas_Rx" SG_ 963 PerimeterAlarmChimeRq 1;
BA_ "U_S550_MY15_Gas_Rx" SG_ 963 PerimeterAlarmChimeRq 1;
BA_ "U_C489_MY14_Gas_Rx" SG_ 963 PerimeterAlarmChimeRq 1;
BA_ "U_U502_MY15_Gas_Rx" SG_ 963 PerimeterAlarmChimeRq 1;
BA_ "U_B479_MY15_Gas_Rx" SG_ 963 PerimeterAlarmChimeRq 1;
BA_ "U_UP375_MY15_Gas_Rx" SG_ 963 PerimeterAlarmChimeRq 1;
BA_ "U_UP375_MY15_Diesel_Rx" SG_ 963 PerimeterAlarmChimeRq 1;
BA_ "U_CD4_MY13_Diesel_Tx" SG_ 963 PerimeterAlarmChimeRq 1;
BA_ "U_CD4_MY13_Gas_Tx" SG_ 963 PerimeterAlarmChimeRq 1;
BA_ "U_CD4_MY13_Hev_Tx" SG_ 963 PerimeterAlarmChimeRq 1;
BA_ "U_CD4_MY13_Phev_Tx" SG_ 963 PerimeterAlarmChimeRq 1;
BA_ "U_CD42_MY14_Diesel_Tx" SG_ 963 PerimeterAlarmChimeRq 1;
BA_ "U_CD42_MY14_Gas_Tx" SG_ 963 PerimeterAlarmChimeRq 1;
BA_ "U_P552_MY15_Gas_Tx" SG_ 963 PerimeterAlarmChimeRq 1;
BA_ "U_S550_MY15_Gas_Tx" SG_ 963 PerimeterAlarmChimeRq 1;
BA_ "U_C489_MY14_Gas_Tx" SG_ 963 PerimeterAlarmChimeRq 1;
BA_ "U_U502_MY15_Gas_Tx" SG_ 963 PerimeterAlarmChimeRq 1;
BA_ "U_UP375_MY15_Gas_Tx" SG_ 963 PerimeterAlarmChimeRq 1;
BA_ "U_UP375_MY15_Diesel_Tx" SG_ 963 PerimeterAlarmChimeRq 1;
BA_ "U_CD43_MY16_Gas_Tx" SG_ 963 PerimeterAlarmChimeRq 1;
BA_ "U_CD4_MY14_Diesel_Tx" SG_ 963 PerimeterAlarmChimeRq 1;
BA_ "U_CD4_MY14_Gas_Tx" SG_ 963 PerimeterAlarmChimeRq 1;
BA_ "U_CD4_MY14_Hev_Tx" SG_ 963 PerimeterAlarmChimeRq 1;
BA_ "U_CD4_MY14_Phev_Tx" SG_ 963 PerimeterAlarmChimeRq 1;
BA_ "U_CD42_MY15_Gas_Rx" SG_ 1506 APIM_AutoSar_Network_Mgmt 1;
BA_ "U_U502_MY16_Gas_Rx" SG_ 1506 APIM_AutoSar_Network_Mgmt 1;
BA_ "U_CD4_MY17_Diesel_Rx" SG_ 1506 APIM_AutoSar_Network_Mgmt 1;
BA_ "U_CD4_MY17_Gas_Rx" SG_ 1506 APIM_AutoSar_Network_Mgmt 1;
BA_ "U_CD4_MY17_Hev_Rx" SG_ 1506 APIM_AutoSar_Network_Mgmt 1;
BA_ "U_CD4_MY17_Phev_Rx" SG_ 1506 APIM_AutoSar_Network_Mgmt 1;
BA_ "U_P558_MY17_Gas_Rx" SG_ 1506 APIM_AutoSar_Network_Mgmt 1;
BA_ "U_P558_MY17_Diesel_Rx" SG_ 1506 APIM_AutoSar_Network_Mgmt 1;
BA_ "U_V36X_MY16_5_Diesel_Rx" SG_ 1506 APIM_AutoSar_Network_Mgmt 1;
BA_ "U_C489_MY17_Gas_Rx" SG_ 1506 APIM_AutoSar_Network_Mgmt 1;
BA_ "U_CD42_MY16_Diesel_Rx" SG_ 1506 APIM_AutoSar_Network_Mgmt 1;
BA_ "U_CD42_MY16_Gas_Rx" SG_ 1506 APIM_AutoSar_Network_Mgmt 1;
BA_ "U_CD43_MY17_Gas_Rx" SG_ 1506 APIM_AutoSar_Network_Mgmt 1;
BA_ "U_P552_MY17_Gas_Rx" SG_ 1506 APIM_AutoSar_Network_Mgmt 1;
BA_ "U_B515_MCA_MY17_Diesel_Rx" SG_ 1506 APIM_AutoSar_Network_Mgmt 1;
BA_ "U_B515_MCA_MY17_Gas_Rx" SG_ 1506 APIM_AutoSar_Network_Mgmt 1;
BA_ "U_U55x_MY18_Gas_Rx" SG_ 1506 APIM_AutoSar_Network_Mgmt 1;
BA_ "U_CD42_MY15_Diesel_Tx" SG_ 1506 APIM_AutoSar_Network_Mgmt 1;
BA_ "U_CD42_MY15_Gas_Tx" SG_ 1506 APIM_AutoSar_Network_Mgmt 1;
BA_ "U_B562LC_MY15_Diesel_Tx" SG_ 1506 APIM_AutoSar_Network_Mgmt 1;
BA_ "U_U502_MY16_Gas_Tx" SG_ 1506 APIM_AutoSar_Network_Mgmt 1;
BA_ "U_UP375_MY15_Gas_Tx" SG_ 1506 APIM_AutoSar_Network_Mgmt 1;
BA_ "U_UP375_MY15_Diesel_Tx" SG_ 1506 APIM_AutoSar_Network_Mgmt 1;
BA_ "U_CD4_MY17_Diesel_Tx" SG_ 1506 APIM_AutoSar_Network_Mgmt 1;
BA_ "U_CD4_MY17_Gas_Tx" SG_ 1506 APIM_AutoSar_Network_Mgmt 1;
BA_ "U_CD4_MY17_Hev_Tx" SG_ 1506 APIM_AutoSar_Network_Mgmt 1;
BA_ "U_CD4_MY17_Phev_Tx" SG_ 1506 APIM_AutoSar_Network_Mgmt 1;
BA_ "U_P558_MY17_Gas_Tx" SG_ 1506 APIM_AutoSar_Network_Mgmt 1;
BA_ "U_P558_MY17_Diesel_Tx" SG_ 1506 APIM_AutoSar_Network_Mgmt 1;
BA_ "U_C489_MY17_Gas_Tx" SG_ 1506 APIM_AutoSar_Network_Mgmt 1;
BA_ "U_CD42_MY16_Diesel_Tx" SG_ 1506 APIM_AutoSar_Network_Mgmt 1;
BA_ "U_CD42_MY16_Gas_Tx" SG_ 1506 APIM_AutoSar_Network_Mgmt 1;
BA_ "U_CD43_MY17_Gas_Tx" SG_ 1506 APIM_AutoSar_Network_Mgmt 1;
BA_ "U_U55x_MY18_Gas_Tx" SG_ 1506 APIM_AutoSar_Network_Mgmt 1;
BA_ "CrossOver_InfoCAN" SG_ 1506 APIM_AutoSar_Network_Mgmt 1;
BA_ "GenSigSendType" SG_ 1506 APIM_AutoSar_Network_Mgmt 3;
BA_ "U_CD4_MY13_Gas_Rx" SG_ 1506 APIM_AutoSar_Network_Mgmt 1;
BA_ "U_CD42_MY14_Gas_Rx" SG_ 1506 APIM_AutoSar_Network_Mgmt 1;
BA_ "U_P552_MY15_Gas_Rx" SG_ 1506 APIM_AutoSar_Network_Mgmt 1;
BA_ "U_S550_MY15_Gas_Rx" SG_ 1506 APIM_AutoSar_Network_Mgmt 1;
BA_ "U_C489_MY14_Gas_Rx" SG_ 1506 APIM_AutoSar_Network_Mgmt 1;
BA_ "U_U502_MY15_Gas_Rx" SG_ 1506 APIM_AutoSar_Network_Mgmt 1;
BA_ "U_UP375_MY15_Gas_Rx" SG_ 1506 APIM_AutoSar_Network_Mgmt 1;
BA_ "U_UP375_MY15_Diesel_Rx" SG_ 1506 APIM_AutoSar_Network_Mgmt 1;
BA_ "U_CD43_MY16_Gas_Rx" SG_ 1506 APIM_AutoSar_Network_Mgmt 1;
BA_ "U_CD4_MY14_Diesel_Rx" SG_ 1506 APIM_AutoSar_Network_Mgmt 1;
BA_ "U_CD4_MY14_Gas_Rx" SG_ 1506 APIM_AutoSar_Network_Mgmt 1;
BA_ "U_CD4_MY14_Hev_Rx" SG_ 1506 APIM_AutoSar_Network_Mgmt 1;
BA_ "U_CD4_MY14_Phev_Rx" SG_ 1506 APIM_AutoSar_Network_Mgmt 1;
BA_ "U_CD4_MY13_Diesel_Tx" SG_ 1506 APIM_AutoSar_Network_Mgmt 1;
BA_ "U_CD4_MY13_Gas_Tx" SG_ 1506 APIM_AutoSar_Network_Mgmt 1;
BA_ "U_CD4_MY13_Hev_Tx" SG_ 1506 APIM_AutoSar_Network_Mgmt 1;
BA_ "U_CD4_MY13_Phev_Tx" SG_ 1506 APIM_AutoSar_Network_Mgmt 1;
BA_ "U_CD42_MY14_Diesel_Tx" SG_ 1506 APIM_AutoSar_Network_Mgmt 1;
BA_ "U_CD42_MY14_Gas_Tx" SG_ 1506 APIM_AutoSar_Network_Mgmt 1;
BA_ "U_P552_MY15_Gas_Tx" SG_ 1506 APIM_AutoSar_Network_Mgmt 1;
BA_ "U_S550_MY15_Gas_Tx" SG_ 1506 APIM_AutoSar_Network_Mgmt 1;
BA_ "U_C489_MY14_Gas_Tx" SG_ 1506 APIM_AutoSar_Network_Mgmt 1;
BA_ "U_B562LC_MY14_Diesel_Tx" SG_ 1506 APIM_AutoSar_Network_Mgmt 1;
BA_ "U_U502_MY15_Gas_Tx" SG_ 1506 APIM_AutoSar_Network_Mgmt 1;
BA_ "U_CD43_MY16_Gas_Tx" SG_ 1506 APIM_AutoSar_Network_Mgmt 1;
BA_ "U_CD4_MY14_Diesel_Tx" SG_ 1506 APIM_AutoSar_Network_Mgmt 1;
BA_ "U_CD4_MY14_Gas_Tx" SG_ 1506 APIM_AutoSar_Network_Mgmt 1;
BA_ "U_CD4_MY14_Hev_Tx" SG_ 1506 APIM_AutoSar_Network_Mgmt 1;
BA_ "U_CD4_MY14_Phev_Tx" SG_ 1506 APIM_AutoSar_Network_Mgmt 1;
BA_ "ContentDependant" SG_ 133 SteWhlRelCalib_An_Sns 1;
BA_ "U_V36X_MY16_5_Diesel_Rx" SG_ 133 SteWhlRelCalib_An_Sns 1;
BA_ "U_V408_MY18_Gas_Rx" SG_ 133 SteWhlRelCalib_An_Sns 1;
BA_ "U_V408_MY18_Diesel_Rx" SG_ 133 SteWhlRelCalib_An_Sns 1;
BA_ "U_CD4_MY13_Gas_Rx" SG_ 133 StePw_B_Rq 1;
BA_ "U_CD42_MY14_Gas_Rx" SG_ 133 StePw_B_Rq 1;
BA_ "U_P552_MY15_Gas_Rx" SG_ 133 StePw_B_Rq 1;
BA_ "U_U502_MY15_Gas_Rx" SG_ 133 StePw_B_Rq 1;
BA_ "U_CD43_MY16_Gas_Rx" SG_ 133 StePw_B_Rq 1;
BA_ "U_CD4_MY14_Gas_Rx" SG_ 133 StePw_B_Rq 1;
BA_ "CrossOver_LIN" SG_ 133 SteWhlOSRelInit2An_Est 1;
BA_ "GenSigStartValue" SG_ 133 SteWhlOSRelInit2An_Est 65534;
BA_ "ContentDependant" SG_ 133 SteWhlAn_No_Cs 1;
BA_ "ContentDependant" SG_ 133 SteWhlAn_No_Cnt 1;
BA_ "CrossOver_LIN" SG_ 133 SteWhlRelInit2_An_Sns 1;
BA_ "GenSigStartValue" SG_ 133 SteWhlRelInit2_An_Sns 65535;
BA_ "U_CD4_MY13_Gas_Rx" SG_ 133 SteWhlRelInit2_An_Sns 1;
BA_ "U_CD42_MY14_Gas_Rx" SG_ 133 SteWhlRelInit2_An_Sns 1;
BA_ "U_P552_MY15_Gas_Rx" SG_ 133 SteWhlRelInit2_An_Sns 1;
BA_ "U_S550_MY15_Gas_Rx" SG_ 133 SteWhlRelInit2_An_Sns 1;
BA_ "U_C489_MY14_Gas_Rx" SG_ 133 SteWhlRelInit2_An_Sns 1;
BA_ "U_U502_MY15_Gas_Rx" SG_ 133 SteWhlRelInit2_An_Sns 1;
BA_ "U_CD43_MY16_Gas_Rx" SG_ 133 SteWhlRelInit2_An_Sns 1;
BA_ "U_CD4_MY14_Gas_Rx" SG_ 133 SteWhlRelInit2_An_Sns 1;
BA_ "U_V363E_N_MY19_5_20_Diesel_Tx" SG_ 909 PoliceIdlMde_D_Stat 1;
BA_ "U_V363E_N_MY19_5_20_Gas_Tx" SG_ 909 PoliceIdlMde_D_Stat 1;
BA_ "U_P552_MY18_5_Diesel_Tx" SG_ 909 PoliceIdlMde_D_Stat 1;
BA_ "U_P552_MY18_5_Gas_Tx" SG_ 909 PoliceIdlMde_D_Stat 1;
BA_ "U_V36X_MY19_Tx" SG_ 909 PoliceIdlMde_D_Stat 1;
BA_ "U_V408_MY18_Diesel_Tx" SG_ 909 PoliceIdlMde_D_Stat 1;
BA_ "U_V408_MY18_Gas_Tx" SG_ 909 PoliceIdlMde_D_Stat 1;
BA_ "U_S550_MY18_Gas_Tx" SG_ 909 PoliceIdlMde_D_Stat 1;
BA_ "U_CD4_MY19_Phev_Tx" SG_ 909 PoliceIdlMde_D_Stat 1;
BA_ "U_CD4_MY19_Hev_Tx" SG_ 909 PoliceIdlMde_D_Stat 1;
BA_ "U_CD4_MY19_Gas_Tx" SG_ 909 PoliceIdlMde_D_Stat 1;
BA_ "U_CD4_MY19_Diesel_Tx" SG_ 909 PoliceIdlMde_D_Stat 1;
BA_ "U_U502_MY17_Gas_Tx" SG_ 909 PoliceIdlMde_D_Stat 1;
BA_ "U_U55x_MY18_Gas_Tx" SG_ 909 PoliceIdlMde_D_Stat 1;
BA_ "U_CD43_MY17_Gas_Tx" SG_ 909 PoliceIdlMde_D_Stat 1;
BA_ "U_P558_MY17_Diesel_Tx" SG_ 909 PoliceIdlMde_D_Stat 1;
BA_ "U_P558_MY17_Gas_Tx" SG_ 909 PoliceIdlMde_D_Stat 1;
BA_ "U_D568C_MY19_Gas_Tx" SG_ 909 PoliceIdlMde_D_Stat 1;
BA_ "GenSigSendType" SG_ 909 PoliceIdlMde_D_Stat 3;
BA_ "GenSigSendType" SG_ 909 TracKeyMde_D_Stat 3;
BA_ "U_S550_MY15_Gas_Rx" SG_ 909 TracKeyMde_D_Stat 1;
BA_ "U_S550_MY18_Gas_Rx" SG_ 909 TracKeyMde_D_Stat 1;
BA_ "U_S550_MY15_Gas_Tx" SG_ 909 TracKeyMde_D_Stat 1;
BA_ "U_P558_MY17_Gas_Tx" SG_ 909 TracKeyMde_D_Stat 1;
BA_ "U_P558_MY17_Diesel_Tx" SG_ 909 TracKeyMde_D_Stat 1;
BA_ "U_V36X_MY16_5_Diesel_Tx" SG_ 909 TracKeyMde_D_Stat 1;
BA_ "U_CD43_MY17_Gas_Tx" SG_ 909 TracKeyMde_D_Stat 1;
BA_ "U_P552_MY18_Gas_Tx" SG_ 909 TracKeyMde_D_Stat 1;
BA_ "U_U55x_MY18_Gas_Tx" SG_ 909 TracKeyMde_D_Stat 1;
BA_ "U_U502_MY17_Gas_Tx" SG_ 909 TracKeyMde_D_Stat 1;
BA_ "U_CD4_MY18_Diesel_Tx" SG_ 909 TracKeyMde_D_Stat 1;
BA_ "U_CD4_MY18_Gas_Tx" SG_ 909 TracKeyMde_D_Stat 1;
BA_ "U_CD4_MY18_Hev_Tx" SG_ 909 TracKeyMde_D_Stat 1;
BA_ "U_CD4_MY18_Phev_Tx" SG_ 909 TracKeyMde_D_Stat 1;
BA_ "U_S550_MY18_Gas_Tx" SG_ 909 TracKeyMde_D_Stat 1;
BA_ "U_V408_MY18_Gas_Tx" SG_ 909 TracKeyMde_D_Stat 1;
BA_ "U_V408_MY18_Diesel_Tx" SG_ 909 TracKeyMde_D_Stat 1;
BA_ "U_V36X_MY18_5_Diesel_Tx" SG_ 909 TracKeyMde_D_Stat 1;
BA_ "U_P552_MY18_5_Gas_Tx" SG_ 909 TracKeyMde_D_Stat 1;
BA_ "U_P552_MY18_5_Diesel_Tx" SG_ 909 TracKeyMde_D_Stat 1;
BA_ "U_V36X_MY19_5_Diesel_Tx" SG_ 909 TracKeyMde_D_Stat 1;
BA_ "U_V363E_N_MY19_5_20_Gas_Tx" SG_ 909 TracKeyMde_D_Stat 1;
BA_ "U_V363E_N_MY19_5_20_Diesel_Tx" SG_ 909 TracKeyMde_D_Stat 1;
BA_ "U_V36X_MY18_5_Gas_Tx" SG_ 909 TracKeyMde_D_Stat 1;
BA_ "U_V36X_MY18_5_Hev_Tx" SG_ 909 TracKeyMde_D_Stat 1;
BA_ "GenSigSendType" SG_ 909 HeadLghtHiPrmsn_D_Stat 3;
BA_ "GenSigStartValue" SG_ 909 HeadLghtHiPrmsn_D_Stat 3;
BA_ "U_U55x_MY18_Gas_Rx" SG_ 909 HeadLghtHiPrmsn_D_Stat 1;
BA_ "U_V408_MY18_Gas_Rx" SG_ 909 HeadLghtHiPrmsn_D_Stat 1;
BA_ "U_P552_MY18_Gas_Tx" SG_ 909 HeadLghtHiPrmsn_D_Stat 1;
BA_ "U_U55x_MY18_Gas_Tx" SG_ 909 HeadLghtHiPrmsn_D_Stat 1;
BA_ "U_CD4_MY18_Diesel_Tx" SG_ 909 HeadLghtHiPrmsn_D_Stat 1;
BA_ "U_CD4_MY18_Gas_Tx" SG_ 909 HeadLghtHiPrmsn_D_Stat 1;
BA_ "U_CD4_MY18_Hev_Tx" SG_ 909 HeadLghtHiPrmsn_D_Stat 1;
BA_ "U_CD4_MY18_Phev_Tx" SG_ 909 HeadLghtHiPrmsn_D_Stat 1;
BA_ "U_S550_MY18_Gas_Tx" SG_ 909 HeadLghtHiPrmsn_D_Stat 1;
BA_ "U_V408_MY18_Gas_Tx" SG_ 909 HeadLghtHiPrmsn_D_Stat 1;
BA_ "U_V408_MY18_Diesel_Tx" SG_ 909 HeadLghtHiPrmsn_D_Stat 1;
BA_ "U_V36X_MY18_5_Diesel_Tx" SG_ 909 HeadLghtHiPrmsn_D_Stat 1;
BA_ "U_P552_MY18_5_Gas_Tx" SG_ 909 HeadLghtHiPrmsn_D_Stat 1;
BA_ "U_P552_MY18_5_Diesel_Tx" SG_ 909 HeadLghtHiPrmsn_D_Stat 1;
BA_ "U_V36X_MY19_5_Diesel_Tx" SG_ 909 HeadLghtHiPrmsn_D_Stat 1;
BA_ "U_V363E_N_MY19_5_20_Gas_Tx" SG_ 909 HeadLghtHiPrmsn_D_Stat 1;
BA_ "U_V363E_N_MY19_5_20_Diesel_Tx" SG_ 909 HeadLghtHiPrmsn_D_Stat 1;
BA_ "U_V36X_MY18_5_Gas_Tx" SG_ 909 HeadLghtHiPrmsn_D_Stat 1;
BA_ "U_V36X_MY18_5_Hev_Tx" SG_ 909 HeadLghtHiPrmsn_D_Stat 1;
BA_ "GenSigSendType" SG_ 909 DrLatchMsgTxt_D_Rq 3;
BA_ "U_P558_MY17_Gas_Tx" SG_ 909 DrLatchMsgTxt_D_Rq 1;
BA_ "U_P558_MY17_Diesel_Tx" SG_ 909 DrLatchMsgTxt_D_Rq 1;
BA_ "U_CD43_MY17_Gas_Tx" SG_ 909 DrLatchMsgTxt_D_Rq 1;
BA_ "U_P552_MY18_Gas_Tx" SG_ 909 DrLatchMsgTxt_D_Rq 1;
BA_ "U_U55x_MY18_Gas_Tx" SG_ 909 DrLatchMsgTxt_D_Rq 1;
BA_ "U_U502_MY17_Gas_Tx" SG_ 909 DrLatchMsgTxt_D_Rq 1;
BA_ "U_CD4_MY18_Diesel_Tx" SG_ 909 DrLatchMsgTxt_D_Rq 1;
BA_ "U_CD4_MY18_Gas_Tx" SG_ 909 DrLatchMsgTxt_D_Rq 1;
BA_ "U_CD4_MY18_Hev_Tx" SG_ 909 DrLatchMsgTxt_D_Rq 1;
BA_ "U_CD4_MY18_Phev_Tx" SG_ 909 DrLatchMsgTxt_D_Rq 1;
BA_ "U_S550_MY18_Gas_Tx" SG_ 909 DrLatchMsgTxt_D_Rq 1;
BA_ "U_V408_MY18_Gas_Tx" SG_ 909 DrLatchMsgTxt_D_Rq 1;
BA_ "U_V408_MY18_Diesel_Tx" SG_ 909 DrLatchMsgTxt_D_Rq 1;
BA_ "U_V36X_MY18_5_Diesel_Tx" SG_ 909 DrLatchMsgTxt_D_Rq 1;
BA_ "U_P552_MY18_5_Gas_Tx" SG_ 909 DrLatchMsgTxt_D_Rq 1;
BA_ "U_P552_MY18_5_Diesel_Tx" SG_ 909 DrLatchMsgTxt_D_Rq 1;
BA_ "U_V36X_MY19_5_Diesel_Tx" SG_ 909 DrLatchMsgTxt_D_Rq 1;
BA_ "U_V363E_N_MY19_5_20_Gas_Tx" SG_ 909 DrLatchMsgTxt_D_Rq 1;
BA_ "U_V363E_N_MY19_5_20_Diesel_Tx" SG_ 909 DrLatchMsgTxt_D_Rq 1;
BA_ "U_V36X_MY18_5_Gas_Tx" SG_ 909 DrLatchMsgTxt_D_Rq 1;
BA_ "U_V36X_MY18_5_Hev_Tx" SG_ 909 DrLatchMsgTxt_D_Rq 1;
BA_ "CrossOver_InfoCAN" SG_ 909 SecurityMsgTxt_D_Rq 1;
BA_ "GenSigSendType" SG_ 909 SecurityMsgTxt_D_Rq 3;
BA_ "U_CD4_MY13_Diesel_Tx" SG_ 909 SecurityMsgTxt_D_Rq 1;
BA_ "U_CD4_MY13_Gas_Tx" SG_ 909 SecurityMsgTxt_D_Rq 1;
BA_ "U_CD4_MY13_Hev_Tx" SG_ 909 SecurityMsgTxt_D_Rq 1;
BA_ "U_CD4_MY13_Phev_Tx" SG_ 909 SecurityMsgTxt_D_Rq 1;
BA_ "U_CD42_MY14_Diesel_Tx" SG_ 909 SecurityMsgTxt_D_Rq 1;
BA_ "U_CD42_MY14_Gas_Tx" SG_ 909 SecurityMsgTxt_D_Rq 1;
BA_ "U_P552_MY15_Gas_Tx" SG_ 909 SecurityMsgTxt_D_Rq 1;
BA_ "U_S550_MY15_Gas_Tx" SG_ 909 SecurityMsgTxt_D_Rq 1;
BA_ "U_C489_MY14_Gas_Tx" SG_ 909 SecurityMsgTxt_D_Rq 1;
BA_ "U_U502_MY15_Gas_Tx" SG_ 909 SecurityMsgTxt_D_Rq 1;
BA_ "U_UP375_MY15_Gas_Tx" SG_ 909 SecurityMsgTxt_D_Rq 1;
BA_ "U_UP375_MY15_Diesel_Tx" SG_ 909 SecurityMsgTxt_D_Rq 1;
BA_ "U_CD43_MY16_Gas_Tx" SG_ 909 SecurityMsgTxt_D_Rq 1;
BA_ "U_CD4_MY14_Diesel_Tx" SG_ 909 SecurityMsgTxt_D_Rq 1;
BA_ "U_CD4_MY14_Gas_Tx" SG_ 909 SecurityMsgTxt_D_Rq 1;
BA_ "U_CD4_MY14_Hev_Tx" SG_ 909 SecurityMsgTxt_D_Rq 1;
BA_ "U_CD4_MY14_Phev_Tx" SG_ 909 SecurityMsgTxt_D_Rq 1;
BA_ "GenSigSendType" SG_ 909 PrmtrAlrmEvnt_D_Stat 3;
BA_ "U_CD4_MY13_Diesel_Tx" SG_ 909 PrmtrAlrmEvnt_D_Stat 1;
BA_ "U_CD4_MY13_Gas_Tx" SG_ 909 PrmtrAlrmEvnt_D_Stat 1;
BA_ "U_CD4_MY13_Hev_Tx" SG_ 909 PrmtrAlrmEvnt_D_Stat 1;
BA_ "U_CD4_MY13_Phev_Tx" SG_ 909 PrmtrAlrmEvnt_D_Stat 1;
BA_ "U_CD42_MY14_Diesel_Tx" SG_ 909 PrmtrAlrmEvnt_D_Stat 1;
BA_ "U_CD42_MY14_Gas_Tx" SG_ 909 PrmtrAlrmEvnt_D_Stat 1;
BA_ "U_P552_MY15_Gas_Tx" SG_ 909 PrmtrAlrmEvnt_D_Stat 1;
BA_ "U_S550_MY15_Gas_Tx" SG_ 909 PrmtrAlrmEvnt_D_Stat 1;
BA_ "U_C489_MY14_Gas_Tx" SG_ 909 PrmtrAlrmEvnt_D_Stat 1;
BA_ "U_U502_MY15_Gas_Tx" SG_ 909 PrmtrAlrmEvnt_D_Stat 1;
BA_ "U_UP375_MY15_Gas_Tx" SG_ 909 PrmtrAlrmEvnt_D_Stat 1;
BA_ "U_UP375_MY15_Diesel_Tx" SG_ 909 PrmtrAlrmEvnt_D_Stat 1;
BA_ "U_CD43_MY16_Gas_Tx" SG_ 909 PrmtrAlrmEvnt_D_Stat 1;
BA_ "U_CD4_MY14_Diesel_Tx" SG_ 909 PrmtrAlrmEvnt_D_Stat 1;
BA_ "U_CD4_MY14_Gas_Tx" SG_ 909 PrmtrAlrmEvnt_D_Stat 1;
BA_ "U_CD4_MY14_Hev_Tx" SG_ 909 PrmtrAlrmEvnt_D_Stat 1;
BA_ "U_CD4_MY14_Phev_Tx" SG_ 909 PrmtrAlrmEvnt_D_Stat 1;
BA_ "CrossOver_InfoCAN" SG_ 909 SteWhlLckMsgTxt_D_Rq 1;
BA_ "GenSigSendType" SG_ 909 SteWhlLckMsgTxt_D_Rq 3;
BA_ "U_CD4_MY13_Diesel_Tx" SG_ 909 SteWhlLckMsgTxt_D_Rq 1;
BA_ "U_CD4_MY13_Gas_Tx" SG_ 909 SteWhlLckMsgTxt_D_Rq 1;
BA_ "U_CD4_MY13_Hev_Tx" SG_ 909 SteWhlLckMsgTxt_D_Rq 1;
BA_ "U_CD4_MY13_Phev_Tx" SG_ 909 SteWhlLckMsgTxt_D_Rq 1;
BA_ "U_CD42_MY14_Diesel_Tx" SG_ 909 SteWhlLckMsgTxt_D_Rq 1;
BA_ "U_CD42_MY14_Gas_Tx" SG_ 909 SteWhlLckMsgTxt_D_Rq 1;
BA_ "U_P552_MY15_Gas_Tx" SG_ 909 SteWhlLckMsgTxt_D_Rq 1;
BA_ "U_S550_MY15_Gas_Tx" SG_ 909 SteWhlLckMsgTxt_D_Rq 1;
BA_ "U_C489_MY14_Gas_Tx" SG_ 909 SteWhlLckMsgTxt_D_Rq 1;
BA_ "U_U502_MY15_Gas_Tx" SG_ 909 SteWhlLckMsgTxt_D_Rq 1;
BA_ "U_UP375_MY15_Gas_Tx" SG_ 909 SteWhlLckMsgTxt_D_Rq 1;
BA_ "U_UP375_MY15_Diesel_Tx" SG_ 909 SteWhlLckMsgTxt_D_Rq 1;
BA_ "U_CD43_MY16_Gas_Tx" SG_ 909 SteWhlLckMsgTxt_D_Rq 1;
BA_ "U_CD4_MY14_Diesel_Tx" SG_ 909 SteWhlLckMsgTxt_D_Rq 1;
BA_ "U_CD4_MY14_Gas_Tx" SG_ 909 SteWhlLckMsgTxt_D_Rq 1;
BA_ "U_CD4_MY14_Hev_Tx" SG_ 909 SteWhlLckMsgTxt_D_Rq 1;
BA_ "U_CD4_MY14_Phev_Tx" SG_ 909 SteWhlLckMsgTxt_D_Rq 1;
BA_ "WakeupSignal" SG_ 909 immoMsgTxt_D_Rq 1;
BA_ "CrossOver_InfoCAN" SG_ 909 immoMsgTxt_D_Rq 1;
BA_ "GenSigSendType" SG_ 909 immoMsgTxt_D_Rq 3;
BA_ "U_CD4_MY13_Diesel_Rx" SG_ 909 immoMsgTxt_D_Rq 1;
BA_ "U_CD4_MY13_Gas_Rx" SG_ 909 immoMsgTxt_D_Rq 1;
BA_ "U_CD4_MY13_Hev_Rx" SG_ 909 immoMsgTxt_D_Rq 1;
BA_ "U_CD4_MY13_Phev_Rx" SG_ 909 immoMsgTxt_D_Rq 1;
BA_ "U_CD42_MY14_Diesel_Rx" SG_ 909 immoMsgTxt_D_Rq 1;
BA_ "U_CD42_MY14_Gas_Rx" SG_ 909 immoMsgTxt_D_Rq 1;
BA_ "U_P552_MY15_Gas_Rx" SG_ 909 immoMsgTxt_D_Rq 1;
BA_ "U_S550_MY15_Gas_Rx" SG_ 909 immoMsgTxt_D_Rq 1;
BA_ "U_C489_MY14_Gas_Rx" SG_ 909 immoMsgTxt_D_Rq 1;
BA_ "U_U502_MY15_Gas_Rx" SG_ 909 immoMsgTxt_D_Rq 1;
BA_ "U_B479_MY15_Gas_Rx" SG_ 909 immoMsgTxt_D_Rq 1;
BA_ "U_UP375_MY15_Gas_Rx" SG_ 909 immoMsgTxt_D_Rq 1;
BA_ "U_UP375_MY15_Diesel_Rx" SG_ 909 immoMsgTxt_D_Rq 1;
BA_ "U_CD4_MY13_Diesel_Tx" SG_ 909 immoMsgTxt_D_Rq 1;
BA_ "U_CD4_MY13_Gas_Tx" SG_ 909 immoMsgTxt_D_Rq 1;
BA_ "U_CD4_MY13_Hev_Tx" SG_ 909 immoMsgTxt_D_Rq 1;
BA_ "U_CD4_MY13_Phev_Tx" SG_ 909 immoMsgTxt_D_Rq 1;
BA_ "U_CD42_MY14_Diesel_Tx" SG_ 909 immoMsgTxt_D_Rq 1;
BA_ "U_CD42_MY14_Gas_Tx" SG_ 909 immoMsgTxt_D_Rq 1;
BA_ "U_P552_MY15_Gas_Tx" SG_ 909 immoMsgTxt_D_Rq 1;
BA_ "U_S550_MY15_Gas_Tx" SG_ 909 immoMsgTxt_D_Rq 1;
BA_ "U_C489_MY14_Gas_Tx" SG_ 909 immoMsgTxt_D_Rq 1;
BA_ "U_U502_MY15_Gas_Tx" SG_ 909 immoMsgTxt_D_Rq 1;
BA_ "U_UP375_MY15_Gas_Tx" SG_ 909 immoMsgTxt_D_Rq 1;
BA_ "U_UP375_MY15_Diesel_Tx" SG_ 909 immoMsgTxt_D_Rq 1;
BA_ "U_CD43_MY16_Gas_Tx" SG_ 909 immoMsgTxt_D_Rq 1;
BA_ "U_CD4_MY14_Diesel_Tx" SG_ 909 immoMsgTxt_D_Rq 1;
BA_ "U_CD4_MY14_Gas_Tx" SG_ 909 immoMsgTxt_D_Rq 1;
BA_ "U_CD4_MY14_Hev_Tx" SG_ 909 immoMsgTxt_D_Rq 1;
BA_ "U_CD4_MY14_Phev_Tx" SG_ 909 immoMsgTxt_D_Rq 1;
BA_ "CrossOver_InfoCAN" SG_ 909 PEBackupSlot_Stats 1;
BA_ "GenSigSendType" SG_ 909 PEBackupSlot_Stats 3;
BA_ "U_CD4_MY13_Diesel_Tx" SG_ 909 PEBackupSlot_Stats 1;
BA_ "U_CD4_MY13_Gas_Tx" SG_ 909 PEBackupSlot_Stats 1;
BA_ "U_CD4_MY13_Hev_Tx" SG_ 909 PEBackupSlot_Stats 1;
BA_ "U_CD4_MY13_Phev_Tx" SG_ 909 PEBackupSlot_Stats 1;
BA_ "U_CD42_MY14_Diesel_Tx" SG_ 909 PEBackupSlot_Stats 1;
BA_ "U_CD42_MY14_Gas_Tx" SG_ 909 PEBackupSlot_Stats 1;
BA_ "U_P552_MY15_Gas_Tx" SG_ 909 PEBackupSlot_Stats 1;
BA_ "U_S550_MY15_Gas_Tx" SG_ 909 PEBackupSlot_Stats 1;
BA_ "U_C489_MY14_Gas_Tx" SG_ 909 PEBackupSlot_Stats 1;
BA_ "U_U502_MY15_Gas_Tx" SG_ 909 PEBackupSlot_Stats 1;
BA_ "U_UP375_MY15_Gas_Tx" SG_ 909 PEBackupSlot_Stats 1;
BA_ "U_UP375_MY15_Diesel_Tx" SG_ 909 PEBackupSlot_Stats 1;
BA_ "U_CD43_MY16_Gas_Tx" SG_ 909 PEBackupSlot_Stats 1;
BA_ "U_CD4_MY14_Diesel_Tx" SG_ 909 PEBackupSlot_Stats 1;
BA_ "U_CD4_MY14_Gas_Tx" SG_ 909 PEBackupSlot_Stats 1;
BA_ "U_CD4_MY14_Hev_Tx" SG_ 909 PEBackupSlot_Stats 1;
BA_ "U_CD4_MY14_Phev_Tx" SG_ 909 PEBackupSlot_Stats 1;
BA_ "CrossOver_InfoCAN" SG_ 909 KeyMykeyTot_No_Cnt 1;
BA_ "GenSigSendType" SG_ 909 KeyMykeyTot_No_Cnt 3;
BA_ "U_CD4_MY13_Diesel_Tx" SG_ 909 KeyMykeyTot_No_Cnt 1;
BA_ "U_CD4_MY13_Gas_Tx" SG_ 909 KeyMykeyTot_No_Cnt 1;
BA_ "U_CD4_MY13_Hev_Tx" SG_ 909 KeyMykeyTot_No_Cnt 1;
BA_ "U_CD4_MY13_Phev_Tx" SG_ 909 KeyMykeyTot_No_Cnt 1;
BA_ "U_CD42_MY14_Diesel_Tx" SG_ 909 KeyMykeyTot_No_Cnt 1;
BA_ "U_CD42_MY14_Gas_Tx" SG_ 909 KeyMykeyTot_No_Cnt 1;
BA_ "U_P552_MY15_Gas_Tx" SG_ 909 KeyMykeyTot_No_Cnt 1;
BA_ "U_S550_MY15_Gas_Tx" SG_ 909 KeyMykeyTot_No_Cnt 1;
BA_ "U_C489_MY14_Gas_Tx" SG_ 909 KeyMykeyTot_No_Cnt 1;
BA_ "U_U502_MY15_Gas_Tx" SG_ 909 KeyMykeyTot_No_Cnt 1;
BA_ "U_UP375_MY15_Gas_Tx" SG_ 909 KeyMykeyTot_No_Cnt 1;
BA_ "U_UP375_MY15_Diesel_Tx" SG_ 909 KeyMykeyTot_No_Cnt 1;
BA_ "U_CD43_MY16_Gas_Tx" SG_ 909 KeyMykeyTot_No_Cnt 1;
BA_ "U_CD4_MY14_Diesel_Tx" SG_ 909 KeyMykeyTot_No_Cnt 1;
BA_ "U_CD4_MY14_Gas_Tx" SG_ 909 KeyMykeyTot_No_Cnt 1;
BA_ "U_CD4_MY14_Hev_Tx" SG_ 909 KeyMykeyTot_No_Cnt 1;
BA_ "U_CD4_MY14_Phev_Tx" SG_ 909 KeyMykeyTot_No_Cnt 1;
BA_ "CrossOver_InfoCAN" SG_ 909 Keycode_Status 1;
BA_ "GenSigSendType" SG_ 909 Keycode_Status 3;
BA_ "U_CD4_MY13_Diesel_Tx" SG_ 909 Keycode_Status 1;
BA_ "U_CD4_MY13_Gas_Tx" SG_ 909 Keycode_Status 1;
BA_ "U_CD4_MY13_Hev_Tx" SG_ 909 Keycode_Status 1;
BA_ "U_CD4_MY13_Phev_Tx" SG_ 909 Keycode_Status 1;
BA_ "U_CD42_MY14_Diesel_Tx" SG_ 909 Keycode_Status 1;
BA_ "U_CD42_MY14_Gas_Tx" SG_ 909 Keycode_Status 1;
BA_ "U_P552_MY15_Gas_Tx" SG_ 909 Keycode_Status 1;
BA_ "U_S550_MY15_Gas_Tx" SG_ 909 Keycode_Status 1;
BA_ "U_C489_MY14_Gas_Tx" SG_ 909 Keycode_Status 1;
BA_ "U_U502_MY15_Gas_Tx" SG_ 909 Keycode_Status 1;
BA_ "U_UP375_MY15_Gas_Tx" SG_ 909 Keycode_Status 1;
BA_ "U_UP375_MY15_Diesel_Tx" SG_ 909 Keycode_Status 1;
BA_ "U_CD43_MY16_Gas_Tx" SG_ 909 Keycode_Status 1;
BA_ "U_CD4_MY14_Diesel_Tx" SG_ 909 Keycode_Status 1;
BA_ "U_CD4_MY14_Gas_Tx" SG_ 909 Keycode_Status 1;
BA_ "U_CD4_MY14_Hev_Tx" SG_ 909 Keycode_Status 1;
BA_ "U_CD4_MY14_Phev_Tx" SG_ 909 Keycode_Status 1;
BA_ "CrossOver_InfoCAN" SG_ 909 KeyAdmnTot_No_Cnt 1;
BA_ "GenSigSendType" SG_ 909 KeyAdmnTot_No_Cnt 3;
BA_ "U_CD4_MY13_Diesel_Tx" SG_ 909 KeyAdmnTot_No_Cnt 1;
BA_ "U_CD4_MY13_Gas_Tx" SG_ 909 KeyAdmnTot_No_Cnt 1;
BA_ "U_CD4_MY13_Hev_Tx" SG_ 909 KeyAdmnTot_No_Cnt 1;
BA_ "U_CD4_MY13_Phev_Tx" SG_ 909 KeyAdmnTot_No_Cnt 1;
BA_ "U_CD42_MY14_Diesel_Tx" SG_ 909 KeyAdmnTot_No_Cnt 1;
BA_ "U_CD42_MY14_Gas_Tx" SG_ 909 KeyAdmnTot_No_Cnt 1;
BA_ "U_P552_MY15_Gas_Tx" SG_ 909 KeyAdmnTot_No_Cnt 1;
BA_ "U_S550_MY15_Gas_Tx" SG_ 909 KeyAdmnTot_No_Cnt 1;
BA_ "U_C489_MY14_Gas_Tx" SG_ 909 KeyAdmnTot_No_Cnt 1;
BA_ "U_U502_MY15_Gas_Tx" SG_ 909 KeyAdmnTot_No_Cnt 1;
BA_ "U_UP375_MY15_Gas_Tx" SG_ 909 KeyAdmnTot_No_Cnt 1;
BA_ "U_UP375_MY15_Diesel_Tx" SG_ 909 KeyAdmnTot_No_Cnt 1;
BA_ "U_CD43_MY16_Gas_Tx" SG_ 909 KeyAdmnTot_No_Cnt 1;
BA_ "U_CD4_MY14_Diesel_Tx" SG_ 909 KeyAdmnTot_No_Cnt 1;
BA_ "U_CD4_MY14_Gas_Tx" SG_ 909 KeyAdmnTot_No_Cnt 1;
BA_ "U_CD4_MY14_Hev_Tx" SG_ 909 KeyAdmnTot_No_Cnt 1;
BA_ "U_CD4_MY14_Phev_Tx" SG_ 909 KeyAdmnTot_No_Cnt 1;
BA_ "GenSigSendType" SG_ 2024 TesterPhysicalResPCM 3;
BA_ "U_CD4_MY13_Diesel_Rx" SG_ 2024 TesterPhysicalResPCM 1;
BA_ "U_CD4_MY13_Gas_Rx" SG_ 2024 TesterPhysicalResPCM 1;
BA_ "U_CD4_MY13_Hev_Rx" SG_ 2024 TesterPhysicalResPCM 1;
BA_ "U_CD4_MY13_Phev_Rx" SG_ 2024 TesterPhysicalResPCM 1;
BA_ "U_CD42_MY14_Diesel_Rx" SG_ 2024 TesterPhysicalResPCM 1;
BA_ "U_CD42_MY14_Gas_Rx" SG_ 2024 TesterPhysicalResPCM 1;
BA_ "U_P552_MY15_Gas_Rx" SG_ 2024 TesterPhysicalResPCM 1;
BA_ "U_S550_MY15_Gas_Rx" SG_ 2024 TesterPhysicalResPCM 1;
BA_ "U_C489_MY14_Gas_Rx" SG_ 2024 TesterPhysicalResPCM 1;
BA_ "U_CD4_MY13_Gas_Tx" SG_ 2024 TesterPhysicalResPCM 1;
BA_ "U_CD42_MY14_Gas_Tx" SG_ 2024 TesterPhysicalResPCM 1;
BA_ "U_P552_MY15_Gas_Tx" SG_ 2024 TesterPhysicalResPCM 1;
BA_ "U_S550_MY15_Gas_Tx" SG_ 2024 TesterPhysicalResPCM 1;
BA_ "U_C489_MY14_Gas_Tx" SG_ 2024 TesterPhysicalResPCM 1;
BA_ "U_U502_MY15_Gas_Tx" SG_ 2024 TesterPhysicalResPCM 1;
BA_ "U_UP375_MY15_Gas_Tx" SG_ 2024 TesterPhysicalResPCM 1;
BA_ "U_CD43_MY16_Gas_Tx" SG_ 2024 TesterPhysicalResPCM 1;
BA_ "U_CD4_MY14_Gas_Tx" SG_ 2024 TesterPhysicalResPCM 1;
BA_ "GenSigMissingSourceValue" SG_ 936 SAPPStatusCoding 6;
BA_ "CrossOver_InfoCAN" SG_ 936 SAPPStatusCoding 1;
BA_ "CrossOver_LIN" SG_ 936 SAPPStatusCoding 1;
BA_ "U_CD4_MY13_Gas_Rx" SG_ 936 SAPPStatusCoding 1;
BA_ "U_CD42_MY14_Gas_Rx" SG_ 936 SAPPStatusCoding 1;
BA_ "U_P552_MY15_Gas_Rx" SG_ 936 SAPPStatusCoding 1;
BA_ "U_C489_MY14_Gas_Rx" SG_ 936 SAPPStatusCoding 1;
BA_ "U_U502_MY15_Gas_Rx" SG_ 936 SAPPStatusCoding 1;
BA_ "U_UP375_MY15_Gas_Rx" SG_ 936 SAPPStatusCoding 1;
BA_ "U_UP375_MY15_Diesel_Rx" SG_ 936 SAPPStatusCoding 1;
BA_ "U_CD43_MY16_Gas_Rx" SG_ 936 SAPPStatusCoding 1;
BA_ "U_CD4_MY14_Diesel_Rx" SG_ 936 SAPPStatusCoding 1;
BA_ "U_CD4_MY14_Gas_Rx" SG_ 936 SAPPStatusCoding 1;
BA_ "U_CD4_MY14_Hev_Rx" SG_ 936 SAPPStatusCoding 1;
BA_ "U_CD4_MY14_Phev_Rx" SG_ 936 SAPPStatusCoding 1;
BA_ "U_CD4_MY13_Diesel_Tx" SG_ 936 SAPPStatusCoding 1;
BA_ "U_CD4_MY13_Gas_Tx" SG_ 936 SAPPStatusCoding 1;
BA_ "U_CD4_MY13_Hev_Tx" SG_ 936 SAPPStatusCoding 1;
BA_ "U_CD4_MY13_Phev_Tx" SG_ 936 SAPPStatusCoding 1;
BA_ "U_CD42_MY14_Diesel_Tx" SG_ 936 SAPPStatusCoding 1;
BA_ "U_CD42_MY14_Gas_Tx" SG_ 936 SAPPStatusCoding 1;
BA_ "U_P552_MY15_Gas_Tx" SG_ 936 SAPPStatusCoding 1;
BA_ "U_C489_MY14_Gas_Tx" SG_ 936 SAPPStatusCoding 1;
BA_ "U_U502_MY15_Gas_Tx" SG_ 936 SAPPStatusCoding 1;
BA_ "U_UP375_MY15_Gas_Tx" SG_ 936 SAPPStatusCoding 1;
BA_ "U_UP375_MY15_Diesel_Tx" SG_ 936 SAPPStatusCoding 1;
BA_ "U_CD43_MY16_Gas_Tx" SG_ 936 SAPPStatusCoding 1;
BA_ "U_CD4_MY14_Diesel_Tx" SG_ 936 SAPPStatusCoding 1;
BA_ "U_CD4_MY14_Gas_Tx" SG_ 936 SAPPStatusCoding 1;
BA_ "U_CD4_MY14_Hev_Tx" SG_ 936 SAPPStatusCoding 1;
BA_ "U_CD4_MY14_Phev_Tx" SG_ 936 SAPPStatusCoding 1;
BA_ "U_CD4_MY13_Diesel_Tx" SG_ 936 EPASExtAngleStatReq 1;
BA_ "U_CD4_MY13_Gas_Tx" SG_ 936 EPASExtAngleStatReq 1;
BA_ "U_CD4_MY13_Hev_Tx" SG_ 936 EPASExtAngleStatReq 1;
BA_ "U_CD4_MY13_Phev_Tx" SG_ 936 EPASExtAngleStatReq 1;
BA_ "U_CD42_MY14_Diesel_Tx" SG_ 936 EPASExtAngleStatReq 1;
BA_ "U_CD42_MY14_Gas_Tx" SG_ 936 EPASExtAngleStatReq 1;
BA_ "U_P552_MY15_Gas_Tx" SG_ 936 EPASExtAngleStatReq 1;
BA_ "U_C489_MY14_Gas_Tx" SG_ 936 EPASExtAngleStatReq 1;
BA_ "U_U502_MY15_Gas_Tx" SG_ 936 EPASExtAngleStatReq 1;
BA_ "U_UP375_MY15_Gas_Tx" SG_ 936 EPASExtAngleStatReq 1;
BA_ "U_UP375_MY15_Diesel_Tx" SG_ 936 EPASExtAngleStatReq 1;
BA_ "U_CD43_MY16_Gas_Tx" SG_ 936 EPASExtAngleStatReq 1;
BA_ "U_CD4_MY14_Diesel_Tx" SG_ 936 EPASExtAngleStatReq 1;
BA_ "U_CD4_MY14_Gas_Tx" SG_ 936 EPASExtAngleStatReq 1;
BA_ "U_CD4_MY14_Hev_Tx" SG_ 936 EPASExtAngleStatReq 1;
BA_ "U_CD4_MY14_Phev_Tx" SG_ 936 EPASExtAngleStatReq 1;
BA_ "U_CD4_MY13_Diesel_Tx" SG_ 936 ExtSteeringAngleReq2 1;
BA_ "U_CD4_MY13_Gas_Tx" SG_ 936 ExtSteeringAngleReq2 1;
BA_ "U_CD4_MY13_Hev_Tx" SG_ 936 ExtSteeringAngleReq2 1;
BA_ "U_CD4_MY13_Phev_Tx" SG_ 936 ExtSteeringAngleReq2 1;
BA_ "U_CD42_MY14_Diesel_Tx" SG_ 936 ExtSteeringAngleReq2 1;
BA_ "U_CD42_MY14_Gas_Tx" SG_ 936 ExtSteeringAngleReq2 1;
BA_ "U_P552_MY15_Gas_Tx" SG_ 936 ExtSteeringAngleReq2 1;
BA_ "U_C489_MY14_Gas_Tx" SG_ 936 ExtSteeringAngleReq2 1;
BA_ "U_U502_MY15_Gas_Tx" SG_ 936 ExtSteeringAngleReq2 1;
BA_ "U_UP375_MY15_Gas_Tx" SG_ 936 ExtSteeringAngleReq2 1;
BA_ "U_UP375_MY15_Diesel_Tx" SG_ 936 ExtSteeringAngleReq2 1;
BA_ "U_CD43_MY16_Gas_Tx" SG_ 936 ExtSteeringAngleReq2 1;
BA_ "U_CD4_MY14_Diesel_Tx" SG_ 936 ExtSteeringAngleReq2 1;
BA_ "U_CD4_MY14_Gas_Tx" SG_ 936 ExtSteeringAngleReq2 1;
BA_ "U_CD4_MY14_Hev_Tx" SG_ 936 ExtSteeringAngleReq2 1;
BA_ "U_CD4_MY14_Phev_Tx" SG_ 936 ExtSteeringAngleReq2 1;
BA_ "U_CD4_MY13_Diesel_Tx" SG_ 936 SAPPErrorCoding 1;
BA_ "U_CD4_MY13_Gas_Tx" SG_ 936 SAPPErrorCoding 1;
BA_ "U_CD4_MY13_Hev_Tx" SG_ 936 SAPPErrorCoding 1;
BA_ "U_CD4_MY13_Phev_Tx" SG_ 936 SAPPErrorCoding 1;
BA_ "U_CD42_MY14_Diesel_Tx" SG_ 936 SAPPErrorCoding 1;
BA_ "U_CD42_MY14_Gas_Tx" SG_ 936 SAPPErrorCoding 1;
BA_ "U_P552_MY15_Gas_Tx" SG_ 936 SAPPErrorCoding 1;
BA_ "U_C489_MY14_Gas_Tx" SG_ 936 SAPPErrorCoding 1;
BA_ "U_U502_MY15_Gas_Tx" SG_ 936 SAPPErrorCoding 1;
BA_ "U_UP375_MY15_Gas_Tx" SG_ 936 SAPPErrorCoding 1;
BA_ "U_UP375_MY15_Diesel_Tx" SG_ 936 SAPPErrorCoding 1;
BA_ "U_CD43_MY16_Gas_Tx" SG_ 936 SAPPErrorCoding 1;
BA_ "U_CD4_MY14_Diesel_Tx" SG_ 936 SAPPErrorCoding 1;
BA_ "U_CD4_MY14_Gas_Tx" SG_ 936 SAPPErrorCoding 1;
BA_ "U_CD4_MY14_Hev_Tx" SG_ 936 SAPPErrorCoding 1;
BA_ "U_CD4_MY14_Phev_Tx" SG_ 936 SAPPErrorCoding 1;
BA_ "U_CD4_MY13_Diesel_Tx" SG_ 951 TirePress_Info_MaxInd 1;
BA_ "U_CD4_MY13_Gas_Tx" SG_ 951 TirePress_Info_MaxInd 1;
BA_ "U_CD4_MY13_Hev_Tx" SG_ 951 TirePress_Info_MaxInd 1;
BA_ "U_CD4_MY13_Phev_Tx" SG_ 951 TirePress_Info_MaxInd 1;
BA_ "U_CD42_MY14_Diesel_Tx" SG_ 951 TirePress_Info_MaxInd 1;
BA_ "U_CD42_MY14_Gas_Tx" SG_ 951 TirePress_Info_MaxInd 1;
BA_ "U_P552_MY15_Gas_Tx" SG_ 951 TirePress_Info_MaxInd 1;
BA_ "U_S550_MY15_Gas_Tx" SG_ 951 TirePress_Info_MaxInd 1;
BA_ "U_C489_MY14_Gas_Tx" SG_ 951 TirePress_Info_MaxInd 1;
BA_ "U_U502_MY15_Gas_Tx" SG_ 951 TirePress_Info_MaxInd 1;
BA_ "U_UP375_MY15_Gas_Tx" SG_ 951 TirePress_Info_MaxInd 1;
BA_ "U_UP375_MY15_Diesel_Tx" SG_ 951 TirePress_Info_MaxInd 1;
BA_ "U_CD43_MY16_Gas_Tx" SG_ 951 TirePress_Info_MaxInd 1;
BA_ "U_CD4_MY14_Diesel_Tx" SG_ 951 TirePress_Info_MaxInd 1;
BA_ "U_CD4_MY14_Gas_Tx" SG_ 951 TirePress_Info_MaxInd 1;
BA_ "U_CD4_MY14_Hev_Tx" SG_ 951 TirePress_Info_MaxInd 1;
BA_ "U_CD4_MY14_Phev_Tx" SG_ 951 TirePress_Info_MaxInd 1;
BA_ "U_CD4_MY13_Diesel_Tx" SG_ 951 TirePress_Info_Index 1;
BA_ "U_CD4_MY13_Gas_Tx" SG_ 951 TirePress_Info_Index 1;
BA_ "U_CD4_MY13_Hev_Tx" SG_ 951 TirePress_Info_Index 1;
BA_ "U_CD4_MY13_Phev_Tx" SG_ 951 TirePress_Info_Index 1;
BA_ "U_CD42_MY14_Diesel_Tx" SG_ 951 TirePress_Info_Index 1;
BA_ "U_CD42_MY14_Gas_Tx" SG_ 951 TirePress_Info_Index 1;
BA_ "U_P552_MY15_Gas_Tx" SG_ 951 TirePress_Info_Index 1;
BA_ "U_S550_MY15_Gas_Tx" SG_ 951 TirePress_Info_Index 1;
BA_ "U_C489_MY14_Gas_Tx" SG_ 951 TirePress_Info_Index 1;
BA_ "U_U502_MY15_Gas_Tx" SG_ 951 TirePress_Info_Index 1;
BA_ "U_UP375_MY15_Gas_Tx" SG_ 951 TirePress_Info_Index 1;
BA_ "U_UP375_MY15_Diesel_Tx" SG_ 951 TirePress_Info_Index 1;
BA_ "U_CD43_MY16_Gas_Tx" SG_ 951 TirePress_Info_Index 1;
BA_ "U_CD4_MY14_Diesel_Tx" SG_ 951 TirePress_Info_Index 1;
BA_ "U_CD4_MY14_Gas_Tx" SG_ 951 TirePress_Info_Index 1;
BA_ "U_CD4_MY14_Hev_Tx" SG_ 951 TirePress_Info_Index 1;
BA_ "U_CD4_MY14_Phev_Tx" SG_ 951 TirePress_Info_Index 1;
BA_ "U_CD4_MY13_Diesel_Tx" SG_ 951 TirePress_Info_ID 1;
BA_ "U_CD4_MY13_Gas_Tx" SG_ 951 TirePress_Info_ID 1;
BA_ "U_CD4_MY13_Hev_Tx" SG_ 951 TirePress_Info_ID 1;
BA_ "U_CD4_MY13_Phev_Tx" SG_ 951 TirePress_Info_ID 1;
BA_ "U_CD42_MY14_Diesel_Tx" SG_ 951 TirePress_Info_ID 1;
BA_ "U_CD42_MY14_Gas_Tx" SG_ 951 TirePress_Info_ID 1;
BA_ "U_P552_MY15_Gas_Tx" SG_ 951 TirePress_Info_ID 1;
BA_ "U_S550_MY15_Gas_Tx" SG_ 951 TirePress_Info_ID 1;
BA_ "U_C489_MY14_Gas_Tx" SG_ 951 TirePress_Info_ID 1;
BA_ "U_U502_MY15_Gas_Tx" SG_ 951 TirePress_Info_ID 1;
BA_ "U_UP375_MY15_Gas_Tx" SG_ 951 TirePress_Info_ID 1;
BA_ "U_UP375_MY15_Diesel_Tx" SG_ 951 TirePress_Info_ID 1;
BA_ "U_CD43_MY16_Gas_Tx" SG_ 951 TirePress_Info_ID 1;
BA_ "U_CD4_MY14_Diesel_Tx" SG_ 951 TirePress_Info_ID 1;
BA_ "U_CD4_MY14_Gas_Tx" SG_ 951 TirePress_Info_ID 1;
BA_ "U_CD4_MY14_Hev_Tx" SG_ 951 TirePress_Info_ID 1;
BA_ "U_CD4_MY14_Phev_Tx" SG_ 951 TirePress_Info_ID 1;
BA_ "U_CD4_MY13_Diesel_Tx" SG_ 950 RemoteKey_Info_MaxInd 1;
BA_ "U_CD4_MY13_Gas_Tx" SG_ 950 RemoteKey_Info_MaxInd 1;
BA_ "U_CD4_MY13_Hev_Tx" SG_ 950 RemoteKey_Info_MaxInd 1;
BA_ "U_CD4_MY13_Phev_Tx" SG_ 950 RemoteKey_Info_MaxInd 1;
BA_ "U_CD42_MY14_Diesel_Tx" SG_ 950 RemoteKey_Info_MaxInd 1;
BA_ "U_CD42_MY14_Gas_Tx" SG_ 950 RemoteKey_Info_MaxInd 1;
BA_ "U_P552_MY15_Gas_Tx" SG_ 950 RemoteKey_Info_MaxInd 1;
BA_ "U_S550_MY15_Gas_Tx" SG_ 950 RemoteKey_Info_MaxInd 1;
BA_ "U_C489_MY14_Gas_Tx" SG_ 950 RemoteKey_Info_MaxInd 1;
BA_ "U_U502_MY15_Gas_Tx" SG_ 950 RemoteKey_Info_MaxInd 1;
BA_ "U_UP375_MY15_Gas_Tx" SG_ 950 RemoteKey_Info_MaxInd 1;
BA_ "U_UP375_MY15_Diesel_Tx" SG_ 950 RemoteKey_Info_MaxInd 1;
BA_ "U_CD43_MY16_Gas_Tx" SG_ 950 RemoteKey_Info_MaxInd 1;
BA_ "U_CD4_MY14_Diesel_Tx" SG_ 950 RemoteKey_Info_MaxInd 1;
BA_ "U_CD4_MY14_Gas_Tx" SG_ 950 RemoteKey_Info_MaxInd 1;
BA_ "U_CD4_MY14_Hev_Tx" SG_ 950 RemoteKey_Info_MaxInd 1;
BA_ "U_CD4_MY14_Phev_Tx" SG_ 950 RemoteKey_Info_MaxInd 1;
BA_ "U_CD4_MY13_Diesel_Tx" SG_ 950 RemoteKey_Info_Index 1;
BA_ "U_CD4_MY13_Gas_Tx" SG_ 950 RemoteKey_Info_Index 1;
BA_ "U_CD4_MY13_Hev_Tx" SG_ 950 RemoteKey_Info_Index 1;
BA_ "U_CD4_MY13_Phev_Tx" SG_ 950 RemoteKey_Info_Index 1;
BA_ "U_CD42_MY14_Diesel_Tx" SG_ 950 RemoteKey_Info_Index 1;
BA_ "U_CD42_MY14_Gas_Tx" SG_ 950 RemoteKey_Info_Index 1;
BA_ "U_P552_MY15_Gas_Tx" SG_ 950 RemoteKey_Info_Index 1;
BA_ "U_S550_MY15_Gas_Tx" SG_ 950 RemoteKey_Info_Index 1;
BA_ "U_C489_MY14_Gas_Tx" SG_ 950 RemoteKey_Info_Index 1;
BA_ "U_U502_MY15_Gas_Tx" SG_ 950 RemoteKey_Info_Index 1;
BA_ "U_UP375_MY15_Gas_Tx" SG_ 950 RemoteKey_Info_Index 1;
BA_ "U_UP375_MY15_Diesel_Tx" SG_ 950 RemoteKey_Info_Index 1;
BA_ "U_CD43_MY16_Gas_Tx" SG_ 950 RemoteKey_Info_Index 1;
BA_ "U_CD4_MY14_Diesel_Tx" SG_ 950 RemoteKey_Info_Index 1;
BA_ "U_CD4_MY14_Gas_Tx" SG_ 950 RemoteKey_Info_Index 1;
BA_ "U_CD4_MY14_Hev_Tx" SG_ 950 RemoteKey_Info_Index 1;
BA_ "U_CD4_MY14_Phev_Tx" SG_ 950 RemoteKey_Info_Index 1;
BA_ "U_CD4_MY13_Diesel_Tx" SG_ 950 RemoteKey_Info_Ctrl 1;
BA_ "U_CD4_MY13_Gas_Tx" SG_ 950 RemoteKey_Info_Ctrl 1;
BA_ "U_CD4_MY13_Hev_Tx" SG_ 950 RemoteKey_Info_Ctrl 1;
BA_ "U_CD4_MY13_Phev_Tx" SG_ 950 RemoteKey_Info_Ctrl 1;
BA_ "U_CD42_MY14_Diesel_Tx" SG_ 950 RemoteKey_Info_Ctrl 1;
BA_ "U_CD42_MY14_Gas_Tx" SG_ 950 RemoteKey_Info_Ctrl 1;
BA_ "U_P552_MY15_Gas_Tx" SG_ 950 RemoteKey_Info_Ctrl 1;
BA_ "U_S550_MY15_Gas_Tx" SG_ 950 RemoteKey_Info_Ctrl 1;
BA_ "U_C489_MY14_Gas_Tx" SG_ 950 RemoteKey_Info_Ctrl 1;
BA_ "U_U502_MY15_Gas_Tx" SG_ 950 RemoteKey_Info_Ctrl 1;
BA_ "U_UP375_MY15_Gas_Tx" SG_ 950 RemoteKey_Info_Ctrl 1;
BA_ "U_UP375_MY15_Diesel_Tx" SG_ 950 RemoteKey_Info_Ctrl 1;
BA_ "U_CD43_MY16_Gas_Tx" SG_ 950 RemoteKey_Info_Ctrl 1;
BA_ "U_CD4_MY14_Diesel_Tx" SG_ 950 RemoteKey_Info_Ctrl 1;
BA_ "U_CD4_MY14_Gas_Tx" SG_ 950 RemoteKey_Info_Ctrl 1;
BA_ "U_CD4_MY14_Hev_Tx" SG_ 950 RemoteKey_Info_Ctrl 1;
BA_ "U_CD4_MY14_Phev_Tx" SG_ 950 RemoteKey_Info_Ctrl 1;
BA_ "U_CD4_MY13_Diesel_Tx" SG_ 950 RemoteKey_Info_TIC 1;
BA_ "U_CD4_MY13_Gas_Tx" SG_ 950 RemoteKey_Info_TIC 1;
BA_ "U_CD4_MY13_Hev_Tx" SG_ 950 RemoteKey_Info_TIC 1;
BA_ "U_CD4_MY13_Phev_Tx" SG_ 950 RemoteKey_Info_TIC 1;
BA_ "U_CD42_MY14_Diesel_Tx" SG_ 950 RemoteKey_Info_TIC 1;
BA_ "U_CD42_MY14_Gas_Tx" SG_ 950 RemoteKey_Info_TIC 1;
BA_ "U_P552_MY15_Gas_Tx" SG_ 950 RemoteKey_Info_TIC 1;
BA_ "U_S550_MY15_Gas_Tx" SG_ 950 RemoteKey_Info_TIC 1;
BA_ "U_C489_MY14_Gas_Tx" SG_ 950 RemoteKey_Info_TIC 1;
BA_ "U_U502_MY15_Gas_Tx" SG_ 950 RemoteKey_Info_TIC 1;
BA_ "U_UP375_MY15_Gas_Tx" SG_ 950 RemoteKey_Info_TIC 1;
BA_ "U_UP375_MY15_Diesel_Tx" SG_ 950 RemoteKey_Info_TIC 1;
BA_ "U_CD43_MY16_Gas_Tx" SG_ 950 RemoteKey_Info_TIC 1;
BA_ "U_CD4_MY14_Diesel_Tx" SG_ 950 RemoteKey_Info_TIC 1;
BA_ "U_CD4_MY14_Gas_Tx" SG_ 950 RemoteKey_Info_TIC 1;
BA_ "U_CD4_MY14_Hev_Tx" SG_ 950 RemoteKey_Info_TIC 1;
BA_ "U_CD4_MY14_Phev_Tx" SG_ 950 RemoteKey_Info_TIC 1;
BA_ "U_CD4_MY13_Diesel_Tx" SG_ 950 Modulation_Ctrl 1;
BA_ "U_CD4_MY13_Gas_Tx" SG_ 950 Modulation_Ctrl 1;
BA_ "U_CD4_MY13_Hev_Tx" SG_ 950 Modulation_Ctrl 1;
BA_ "U_CD4_MY13_Phev_Tx" SG_ 950 Modulation_Ctrl 1;
BA_ "U_CD42_MY14_Diesel_Tx" SG_ 950 Modulation_Ctrl 1;
BA_ "U_CD42_MY14_Gas_Tx" SG_ 950 Modulation_Ctrl 1;
BA_ "U_P552_MY15_Gas_Tx" SG_ 950 Modulation_Ctrl 1;
BA_ "U_S550_MY15_Gas_Tx" SG_ 950 Modulation_Ctrl 1;
BA_ "U_C489_MY14_Gas_Tx" SG_ 950 Modulation_Ctrl 1;
BA_ "U_U502_MY15_Gas_Tx" SG_ 950 Modulation_Ctrl 1;
BA_ "U_UP375_MY15_Gas_Tx" SG_ 950 Modulation_Ctrl 1;
BA_ "U_UP375_MY15_Diesel_Tx" SG_ 950 Modulation_Ctrl 1;
BA_ "U_CD43_MY16_Gas_Tx" SG_ 950 Modulation_Ctrl 1;
BA_ "U_CD4_MY14_Diesel_Tx" SG_ 950 Modulation_Ctrl 1;
BA_ "U_CD4_MY14_Gas_Tx" SG_ 950 Modulation_Ctrl 1;
BA_ "U_CD4_MY14_Hev_Tx" SG_ 950 Modulation_Ctrl 1;
BA_ "U_CD4_MY14_Phev_Tx" SG_ 950 Modulation_Ctrl 1;
BA_ "GenSigStartValue" SG_ 950 TirePress_Filter_Ctrl 2;
BA_ "U_CD4_MY13_Diesel_Tx" SG_ 950 TirePress_Filter_Ctrl 1;
BA_ "U_CD4_MY13_Gas_Tx" SG_ 950 TirePress_Filter_Ctrl 1;
BA_ "U_CD4_MY13_Hev_Tx" SG_ 950 TirePress_Filter_Ctrl 1;
BA_ "U_CD4_MY13_Phev_Tx" SG_ 950 TirePress_Filter_Ctrl 1;
BA_ "U_CD42_MY14_Diesel_Tx" SG_ 950 TirePress_Filter_Ctrl 1;
BA_ "U_CD42_MY14_Gas_Tx" SG_ 950 TirePress_Filter_Ctrl 1;
BA_ "U_P552_MY15_Gas_Tx" SG_ 950 TirePress_Filter_Ctrl 1;
BA_ "U_S550_MY15_Gas_Tx" SG_ 950 TirePress_Filter_Ctrl 1;
BA_ "U_C489_MY14_Gas_Tx" SG_ 950 TirePress_Filter_Ctrl 1;
BA_ "U_U502_MY15_Gas_Tx" SG_ 950 TirePress_Filter_Ctrl 1;
BA_ "U_UP375_MY15_Gas_Tx" SG_ 950 TirePress_Filter_Ctrl 1;
BA_ "U_UP375_MY15_Diesel_Tx" SG_ 950 TirePress_Filter_Ctrl 1;
BA_ "U_CD43_MY16_Gas_Tx" SG_ 950 TirePress_Filter_Ctrl 1;
BA_ "U_CD4_MY14_Diesel_Tx" SG_ 950 TirePress_Filter_Ctrl 1;
BA_ "U_CD4_MY14_Gas_Tx" SG_ 950 TirePress_Filter_Ctrl 1;
BA_ "U_CD4_MY14_Hev_Tx" SG_ 950 TirePress_Filter_Ctrl 1;
BA_ "U_CD4_MY14_Phev_Tx" SG_ 950 TirePress_Filter_Ctrl 1;
BA_ "U_CD4_MY13_Phev_Rx" SG_ 71 immoTarget1Status 1;
BA_ "U_CD42_MY14_Diesel_Rx" SG_ 71 immoTarget1Status 1;
BA_ "U_CD42_MY14_Gas_Rx" SG_ 71 immoTarget1Status 1;
BA_ "U_P552_MY15_Gas_Rx" SG_ 71 immoTarget1Status 1;
BA_ "U_S550_MY15_Gas_Rx" SG_ 71 immoTarget1Status 1;
BA_ "U_C489_MY14_Gas_Rx" SG_ 71 immoTarget1Status 1;
BA_ "U_U502_MY15_Gas_Rx" SG_ 71 immoTarget1Status 1;
BA_ "U_UP375_MY15_Gas_Rx" SG_ 71 immoTarget1Status 1;
BA_ "U_UP375_MY15_Diesel_Rx" SG_ 71 immoTarget1Status 1;
BA_ "U_CD43_MY16_Gas_Rx" SG_ 71 immoTarget1Status 1;
BA_ "U_CD4_MY14_Diesel_Rx" SG_ 71 immoTarget1Status 1;
BA_ "U_CD4_MY14_Gas_Rx" SG_ 71 immoTarget1Status 1;
BA_ "U_CD4_MY14_Hev_Rx" SG_ 71 immoTarget1Status 1;
BA_ "U_CD4_MY14_Phev_Rx" SG_ 71 immoTarget1Status 1;
BA_ "U_CD4_MY13_Gas_Tx" SG_ 71 immoTarget1Status 1;
BA_ "U_CD42_MY14_Gas_Tx" SG_ 71 immoTarget1Status 1;
BA_ "U_P552_MY15_Gas_Tx" SG_ 71 immoTarget1Status 1;
BA_ "U_S550_MY15_Gas_Tx" SG_ 71 immoTarget1Status 1;
BA_ "U_C489_MY14_Gas_Tx" SG_ 71 immoTarget1Status 1;
BA_ "U_U502_MY15_Gas_Tx" SG_ 71 immoTarget1Status 1;
BA_ "U_UP375_MY15_Gas_Tx" SG_ 71 immoTarget1Status 1;
BA_ "U_CD43_MY16_Gas_Tx" SG_ 71 immoTarget1Status 1;
BA_ "U_CD4_MY14_Gas_Tx" SG_ 71 immoTarget1Status 1;
BA_ "U_CD4_MY13_Phev_Rx" SG_ 71 immoTarget1Data 1;
BA_ "U_CD42_MY14_Diesel_Rx" SG_ 71 immoTarget1Data 1;
BA_ "U_CD42_MY14_Gas_Rx" SG_ 71 immoTarget1Data 1;
BA_ "U_P552_MY15_Gas_Rx" SG_ 71 immoTarget1Data 1;
BA_ "U_S550_MY15_Gas_Rx" SG_ 71 immoTarget1Data 1;
BA_ "U_C489_MY14_Gas_Rx" SG_ 71 immoTarget1Data 1;
BA_ "U_U502_MY15_Gas_Rx" SG_ 71 immoTarget1Data 1;
BA_ "U_UP375_MY15_Gas_Rx" SG_ 71 immoTarget1Data 1;
BA_ "U_UP375_MY15_Diesel_Rx" SG_ 71 immoTarget1Data 1;
BA_ "U_CD43_MY16_Gas_Rx" SG_ 71 immoTarget1Data 1;
BA_ "U_CD4_MY14_Diesel_Rx" SG_ 71 immoTarget1Data 1;
BA_ "U_CD4_MY14_Gas_Rx" SG_ 71 immoTarget1Data 1;
BA_ "U_CD4_MY14_Hev_Rx" SG_ 71 immoTarget1Data 1;
BA_ "U_CD4_MY14_Phev_Rx" SG_ 71 immoTarget1Data 1;
BA_ "U_CD4_MY13_Gas_Tx" SG_ 71 immoTarget1Data 1;
BA_ "U_CD42_MY14_Gas_Tx" SG_ 71 immoTarget1Data 1;
BA_ "U_P552_MY15_Gas_Tx" SG_ 71 immoTarget1Data 1;
BA_ "U_S550_MY15_Gas_Tx" SG_ 71 immoTarget1Data 1;
BA_ "U_C489_MY14_Gas_Tx" SG_ 71 immoTarget1Data 1;
BA_ "U_U502_MY15_Gas_Tx" SG_ 71 immoTarget1Data 1;
BA_ "U_UP375_MY15_Gas_Tx" SG_ 71 immoTarget1Data 1;
BA_ "U_CD43_MY16_Gas_Tx" SG_ 71 immoTarget1Data 1;
BA_ "U_CD4_MY14_Gas_Tx" SG_ 71 immoTarget1Data 1;
BA_ "U_CD4_MY13_Phev_Rx" SG_ 71 immoTarget1Cmd 1;
BA_ "U_CD42_MY14_Diesel_Rx" SG_ 71 immoTarget1Cmd 1;
BA_ "U_CD42_MY14_Gas_Rx" SG_ 71 immoTarget1Cmd 1;
BA_ "U_P552_MY15_Gas_Rx" SG_ 71 immoTarget1Cmd 1;
BA_ "U_S550_MY15_Gas_Rx" SG_ 71 immoTarget1Cmd 1;
BA_ "U_C489_MY14_Gas_Rx" SG_ 71 immoTarget1Cmd 1;
BA_ "U_U502_MY15_Gas_Rx" SG_ 71 immoTarget1Cmd 1;
BA_ "U_UP375_MY15_Gas_Rx" SG_ 71 immoTarget1Cmd 1;
BA_ "U_UP375_MY15_Diesel_Rx" SG_ 71 immoTarget1Cmd 1;
BA_ "U_CD43_MY16_Gas_Rx" SG_ 71 immoTarget1Cmd 1;
BA_ "U_CD4_MY14_Diesel_Rx" SG_ 71 immoTarget1Cmd 1;
BA_ "U_CD4_MY14_Gas_Rx" SG_ 71 immoTarget1Cmd 1;
BA_ "U_CD4_MY14_Hev_Rx" SG_ 71 immoTarget1Cmd 1;
BA_ "U_CD4_MY14_Phev_Rx" SG_ 71 immoTarget1Cmd 1;
BA_ "U_CD4_MY13_Gas_Tx" SG_ 71 immoTarget1Cmd 1;
BA_ "U_CD42_MY14_Gas_Tx" SG_ 71 immoTarget1Cmd 1;
BA_ "U_P552_MY15_Gas_Tx" SG_ 71 immoTarget1Cmd 1;
BA_ "U_S550_MY15_Gas_Tx" SG_ 71 immoTarget1Cmd 1;
BA_ "U_C489_MY14_Gas_Tx" SG_ 71 immoTarget1Cmd 1;
BA_ "U_U502_MY15_Gas_Tx" SG_ 71 immoTarget1Cmd 1;
BA_ "U_UP375_MY15_Gas_Tx" SG_ 71 immoTarget1Cmd 1;
BA_ "U_CD43_MY16_Gas_Tx" SG_ 71 immoTarget1Cmd 1;
BA_ "U_CD4_MY14_Gas_Tx" SG_ 71 immoTarget1Cmd 1;
VAL_ 938 ApaMde_D_Stat 7 "NotUsed3" 6 "NotUsed2" 5 "NotUsed1" 4 "POA" 3 "PPA" 2 "SAPP" 1 "Off" 0 "Null" ;
VAL_ 938 ApaActvSd_D_Actl 3 "Dirver_Side" 2 "Passenger_Side" 1 "No_Side" 0 "Null" ;
VAL_ 938 PrkAidSwtch_B_Stat 1 "Pressed" 0 "Not_Pressed" ;
VAL_ 938 ApaMde_D_Avail 15 "NotUsed7" 14 "NotUsed6" 13 "NotUsed5" 12 "NotUsed4" 11 "NotUsed3" 10 "NotUsed2" 9 "NotUsed1" 8 "PPA_POA" 7 "SAPP_POA" 6 "POA" 5 "PPA" 4 "SAPP" 3 "SAPP_PPA_POA" 2 "SAPP_PPA" 1 "None" 0 "Null" ;
VAL_ 938 PrkAidSnsFrSide_D_Stat 15 "Zone_15" 14 "Zone_14" 13 "Zone_13" 12 "Zone_12" 11 "Zone_11" 10 "Zone_10" 9 "Zone_9" 8 "Zone_8" 7 "Zone_7" 6 "Zone_6" 5 "Zone_5" 4 "Zone_4" 3 "Zone_3" 2 "Zone_2" 1 "Zone_1" 0 "Off" ;
VAL_ 938 PrkAidSnsFrCrnr_D_Stat 15 "Zone_15" 14 "Zone_14" 13 "Zone_13" 12 "Zone_12" 11 "Zone_11" 10 "Zone_10" 9 "Zone_9" 8 "Zone_8" 7 "Zone_7" 6 "Zone_6" 5 "Zone_5" 4 "Zone_4" 3 "Zone_3" 2 "Zone_2" 1 "Zone_1" 0 "Off" ;
VAL_ 938 PrkAidSnsFrCntr_D_Stat 15 "Zone_15" 14 "Zone_14" 13 "Zone_13" 12 "Zone_12" 11 "Zone_11" 10 "Zone_10" 9 "Zone_9" 8 "Zone_8" 7 "Zone_7" 6 "Zone_6" 5 "Zone_5" 4 "Zone_4" 3 "Zone_3" 2 "Zone_2" 1 "Zone_1" 0 "Off" ;
VAL_ 938 PrkAidSnsFlSide_D_Stat 15 "Zone_15" 14 "Zone_14" 13 "Zone_13" 12 "Zone_12" 11 "Zone_11" 10 "Zone_10" 9 "Zone_9" 8 "Zone_8" 7 "Zone_7" 6 "Zone_6" 5 "Zone_5" 4 "Zone_4" 3 "Zone_3" 2 "Zone_2" 1 "Zone_1" 0 "Off" ;
VAL_ 938 PrkAidSnsFlCrnr_D_Stat 15 "Zone_15" 14 "Zone_14" 13 "Zone_13" 12 "Zone_12" 11 "Zone_11" 10 "Zone_10" 9 "Zone_9" 8 "Zone_8" 7 "Zone_7" 6 "Zone_6" 5 "Zone_5" 4 "Zone_4" 3 "Zone_3" 2 "Zone_2" 1 "Zone_1" 0 "Off" ;
VAL_ 938 PrkAidSnsFlCntr_D_Stat 15 "Zone_15" 14 "Zone_14" 13 "Zone_13" 12 "Zone_12" 11 "Zone_11" 10 "Zone_10" 9 "Zone_9" 8 "Zone_8" 7 "Zone_7" 6 "Zone_6" 5 "Zone_5" 4 "Zone_4" 3 "Zone_3" 2 "Zone_2" 1 "Zone_1" 0 "Off" ;
VAL_ 938 RpaChime_D_Rq 15 "Zone15_Chime" 14 "Zone14_Chime" 13 "Zone13_Chime" 12 "Zone12_Chime" 11 "Zone11_Chime" 10 "Zone10_Chime" 9 "Zone9_Chime" 8 "Zone8_Chime" 7 "Zone7_Chime" 6 "Zone6_Chime" 5 "Zone5_Chime" 4 "Zone4_Chime" 3 "Zone3_Chime" 2 "Zone2_Chime" 1 "Zone1_Chime" 0 "No_Chime" ;
VAL_ 938 FpaChime_D_Rq 15 "Zone15_Chime" 14 "Zone14_Chime" 13 "Zone13_Chime" 12 "Zone12_Chime" 11 "Zone11_Chime" 10 "Zone10_Chime" 9 "Zone9_Chime" 8 "Zone8_Chime" 7 "Zone7_Chime" 6 "Zone6_Chime" 5 "Zone5_Chime" 4 "Zone4_Chime" 3 "Zone3_Chime" 2 "Zone2_Chime" 1 "Zone1_Chime" 0 "No_Chime" ;
VAL_ 938 PrkAidMsgTxt_D_Rq 15 "NotUsed7" 14 "NotUsed6" 13 "NotUsed5" 12 "R_Sns_Inactive_Trlr_atch" 11 "Not_Avail_Trlr_attchd" 10 "Fail_Mode_no_Chime" 9 "Fail_Mode_with_Chime" 8 "NotUsed4" 7 "NotUsed3" 6 "Park_Sys_Alternate_Mode" 5 "R_Snsrs_On_F_Snsrs_On" 4 "NotUsed2" 3 "NotUsed1" 2 "R_Snsrs_Off_F_Snsrs_On" 1 "R_Snsrs_On_F_Snsrs_Off" 0 "All_Park_Sensors_Off" ;
VAL_ 938 PrkAidAudioMute_B_Rq 1 "Enable" 0 "Disable" ;
VAL_ 963 WrlssAcsyChrgInhbt_B_Rq 1 "Yes" 0 "No" ;
VAL_ 963 PudLampPsngr_D_Rq 3 "Ramp_Down" 2 "Ramp_Up" 1 "On" 0 "Off" ;
VAL_ 963 PudLampDrv_D_Rq 3 "Ramp_Down" 2 "Ramp_Up" 1 "On" 0 "Off" ;
VAL_ 963 DrTgateLck_D_Stat 3 "NotUsed" 2 "Unlock" 1 "Lock" 0 "Null" ;
VAL_ 963 Illuminated_Entry_Stat 1 "On" 0 "Off" 3 "Invalid" 2 "Unknown" ;
VAL_ 963 Dr_Courtesy_Light_Stat 1 "On" 0 "Off" 3 "Invalid" 2 "Unknown" ;
VAL_ 963 Courtesy_Delay_Status 3 "Invalid" 2 "Unknown" 1 "On" 0 "Off" ;
VAL_ 963 ImpactEvntFdbck_D_Stat 3 "NotUsed" 2 "EventComplete" 1 "EventInProgress" 0 "Normal" ;
VAL_ 963 HeadLampLoOut_B_Stat 1 "Out" 0 "Null" ;
VAL_ 963 HeadLghtHiFdbck_D_Stat 3 "NotUsed" 2 "Cancel" 1 "Hold" 0 "Allow_Change" ;
VAL_ 963 TrnNotInPrkChime_B_Rq 1 "On" 0 "Off" ;
VAL_ 963 PrkLightChime_B_Rq 1 "On" 0 "Off" ;
VAL_ 963 KeyInIgnWarn_B_Cmd 1 "On" 0 "Off" ;
VAL_ 963 HomeSafeLtChime_B_Rq 1 "On" 0 "Off" ;
VAL_ 963 StopLghtOn_B_Stat 1 "On" 0 "Off" ;
VAL_ 963 RvrseLghtOn_B_Stat 1 "On" 0 "Off" ;
VAL_ 963 PrkLght_D_Stat 3 "Park_Both" 2 "Park_Right" 1 "Park_Left" 0 "Off" ;
VAL_ 963 HeadLghtSwtch_D_Stat 3 "Autolamp" 2 "Headlamp" 1 "Parklamp" 0 "Off" ;
VAL_ 963 HeadLampLoFrOn_B_Stat 1 "Low" 0 "Not_Low" ;
VAL_ 963 HeadLampLoFlOn_B_Stat 1 "Low" 0 "Not_Low" ;
VAL_ 963 HeadLampLoActv_B_Stat 1 "On" 0 "Off" ;
VAL_ 963 Headlamp_On_Wrning_Cmd 1 "On" 0 "Off" ;
VAL_ 963 Park_Brake_Chime_Rqst 1 "On" 0 "Off" ;
VAL_ 963 HeadLghtHiOn_B_Stat 1 "On" 0 "Off" ;
VAL_ 963 BrkWarnInd_B_Rq 1 "On" 0 "Off" ;
VAL_ 963 Brk_Fluid_Lvl_Low 3 "Invalid" 2 "Unknown" 1 "Low" 0 "OK" ;
VAL_ 963 ReducedGuard_D_Stat 3 "NotUsed" 2 "Alarm_On" 1 "Alarm_Off_Previously_On" 0 "Alarm_Off" ;
VAL_ 963 Perimeter_Alarm_Status 3 "Activated" 2 "Armed" 1 "Prearmed" 0 "Disarmed" ;
VAL_ 963 Courtesy_BSave_Stat 3 "Invalid" 2 "Unknown" 1 "No_Effect" 0 "Off" ;
VAL_ 963 WndwGlbl_D_Cmd 7 "NotUsed3" 6 "NotUsed2" 5 "NotUsed1" 4 "GLEARN" 3 "GCLOSE" 2 "GOPEN" 1 "GSTOP" 0 "Null" ;
VAL_ 963 PudLamp_D_Rq 3 "RAMP_DOWN" 2 "RAMP_UP" 1 "ON" 0 "OFF" ;
VAL_ 963 DayRnngLampOn_B_Stat 1 "On" 0 "Off" ;
VAL_ 963 PerimeterAlarmChimeRq 1 "On" 0 "Off" ;
VAL_ 133 SteWhlRelCalib_An_Sns 32767 "Fault" 32766 "NoDataExists" ;
VAL_ 133 StePw_B_Rq 1 "Yes" 0 "No" ;
VAL_ 133 SteWhlOSRelInit2An_Est 65535 "Fault" 65534 "Unknown" ;
VAL_ 133 SteWhlRelInit2_An_Sns 65535 "Fault" 65534 "Unknown" ;
VAL_ 909 PoliceIdlMde_D_Stat 15 "NotUsed_7" 14 "NotUsed_6" 13 "NotUsed_5" 12 "NotUsed_4" 11 "NotUsed_3" 10 "NotUsed_2" 9 "NotUsed_1" 8 "Decommissioned" 7 "ActiveFault" 6 "ArmFault" 5 "PrearmedFault" 4 "OffFault" 3 "Active" 2 "Arm" 1 "Prearmed" 0 "Off" ;
VAL_ 909 TracKeyMde_D_Stat 3 "NotUsed" 2 "NotActive" 1 "Active" 0 "ModeNotDetermined" ;
VAL_ 909 HeadLghtHiPrmsn_D_Stat 3 "CancelAndSuppress" 2 "Cancel" 1 "Hold" 0 "AllowChange" ;
VAL_ 909 DrLatchMsgTxt_D_Rq 7 "Message7" 6 "Message6" 5 "Message5" 4 "Message4" 3 "Message3" 2 "Message2" 1 "Message1" 0 "NoMessage" ;
VAL_ 909 SecurityMsgTxt_D_Rq 3 "Message3" 2 "Message2" 1 "Message1" 0 "NoMessage" ;
VAL_ 909 PrmtrAlrmEvnt_D_Stat 15 "Diag_Tamper" 14 "Trailer" 13 "Shock_Sensor" 12 "Post_Crash" 11 "Panic" 10 "Intrusion" 9 "Inclination" 8 "Ign_Tamper" 7 "LG_Door" 6 "Decklid" 5 "Hood" 4 "PR_Door" 3 "PF_Door" 2 "DR_Door" 1 "DF_Door" 0 "Null" ;
VAL_ 909 SteWhlLckMsgTxt_D_Rq 3 "NotUsed" 2 "Message_2" 1 "Message_1" 0 "No_Message" ;
VAL_ 909 immoMsgTxt_D_Rq 15 "Immo_Msg_15" 14 "Immo_Msg_14" 13 "Immo_Msg_13" 12 "Immo_Msg_12" 11 "Immo_Msg_11" 10 "Immo_Msg_10" 9 "Immo_Msg_9" 8 "Immo_Msg_8" 7 "Immo_Msg_7" 6 "Immo_Msg_6" 5 "Immo_Msg_5" 4 "Immo_Msg_4" 3 "Immo_Msg_3" 2 "Immo_Msg_2" 1 "Immo_Msg_1" 0 "Immo_Msg_0_Null" ;
VAL_ 909 PEBackupSlot_Stats 3 "No_Valid_FOB_In_Slot" 2 "MyKey_FOB_In_Slot" 1 "Standard_FOB_In_Slot" 0 "Null" ;
VAL_ 909 KeyMykeyTot_No_Cnt 13 "Thirteen" 12 "Twelve" 11 "Eleven" 10 "Ten" 9 "Nine" 8 "Eight" 7 "Seven" 6 "Six" 5 "Five" 4 "Four" 3 "Three" 2 "Two" 1 "One" 0 "Zero" 15 "Invalid" 14 "Unlimited" ;
VAL_ 909 KeyAdmnTot_No_Cnt 13 "Thirteen" 12 "Twelve" 11 "Eleven" 10 "Ten" 9 "Nine" 8 "Eight" 7 "Seven" 6 "Six" 5 "Five" 4 "Four" 3 "Three" 2 "Two" 1 "One" 0 "Zero" 15 "Invalid" 14 "Unlimited" ;
VAL_ 936 ApaChime_D_Rq 7 "NotUsed2" 6 "NotUsed1" 5 "Warning_Chime" 4 "Finish_Chime" 3 "Stop_Now_Chime" 2 "Spot_Ready_Chime" 1 "Spot_Found_Chime" 0 "No_Chime" ;
VAL_ 936 EPASExtAngleStatReq 1 "Request" 0 "NoRequest" ;
VAL_ 936 ExtSteeringAngleReq2 32767 "Invalid" 32766 "Unknown" ;
VAL_ 936 SAPPErrorCoding 32 "Error_32" 31 "Error_31" 30 "Error_30" 29 "Error_29" 28 "Error_28" 27 "Error_27" 26 "Error_26" 25 "Error_25" 24 "Error_24" 23 "Error_23" 22 "Error_22" 21 "Error_21" 20 "Error_20" 19 "Error_19" 18 "Error_18" 17 "Error_17" 16 "Error_16" 15 "Error_15" 14 "Error_14" 13 "Error_13" 12 "Error_12" 11 "Error_11" 10 "Error_10" 9 "Error_9" 8 "Error_8" 7 "Error_7" 6 "Error_6" 5 "Error_5" 4 "Error_4" 3 "Error_3" 2 "Error_2" 1 "Error_1" 0 "Not_Used" ;
VAL_ 950 Modulation_Ctrl 3 "Unused" 2 "FSK" 1 "ASK_FSK" 0 "ASK" ;
VAL_ 950 TirePress_Filter_Ctrl 3 "Streaming" 2 "Filter" 1 "Not_Used" 0 "Null" ;
VAL_ 71 immoTarget1Status 7 "Unused4" 6 "Unused3" 5 "Unused2" 4 "Unused1" 3 "DISABLED_RESET   " 2 "ENABLED_NONMOTIVE_START" 1 "ENABLED_MOTIVE_START" 0 "DISABLED" ;
VAL_ 71 immoTarget1Cmd 7 "Unused4" 6 "Unused3" 5 "Unused2" 4 "Unused1" 3 "TARGET1_IDBLOCK2" 2 "TARGET1_IDBLOCK1" 1 "CHALLENGE" 0 "IDLE" ;
